VERSION ""

NS_ :

BS_:

BU_: External_Tool IFV SODFR SODFL

BO_ 1064 SODFR_DETECTION_161_164: 64 SODFR
 SG_ CAN_FR_DET_RANGE_161 : 7|14@0+ (0.015625,0) [0|255.984375] "m"  IFV
 SG_ CAN_FR_DET_SD_RANGE_161 : 9|6@0+ (0.025,0) [0|1.5] "m"  IFV
 SG_ CAN_FR_DET_RANGE_RATE_161 : 19|14@0+ (0.015625,-128) [-128|127.984375] "m/s"  IFV
 SG_ CAN_FR_DET_SD_RANGE_RATE_161 : 37|6@0+ (0.02,0) [0|1.2] "m/s"  IFV
 SG_ CAN_FR_DET_AZIMUTH_161 : 47|13@0+ (0.0007668,-3.141593) [-3.141593|3.141593] "rad"  IFV
 SG_ CAN_FR_DET_SD_AZIMUTH_161 : 50|6@0+ (0.001745329,0) [0|0.104719755] "rad"  IFV
 SG_ CAN_FR_DET_ELEVATION_161 : 60|7@0+ (0.157449,-9.99812) [-9.99812|9.997903] "deg"  IFV
 SG_ CAN_FR_DET_SD_ELEVATION_161 : 69|6@0+ (0.003490659,0) [0|0.20943951] "rad"  IFV
 SG_ CAN_FR_DET_AMPLITUDE_161 : 79|7@0+ (1,-64) [-64|63] "dBsm"  IFV
 SG_ CAN_FR_DET_VALID_FLAG_161 : 72|1@0+ (1,0) [0|1] ""  IFV
 SG_ CAN_FR_DET_SUPER_RES_161 : 80|1@0+ (1,0) [0|1] ""  IFV
 SG_ CAN_FR_DET_LOW_SNR_FLAG_161 : 81|1@0+ (1,0) [0|1] ""  IFV
 SG_ CAN_FR_DET_MIXER_BIAS_FLAG_161 : 82|1@0+ (1,0) [0|1] ""  IFV
 SG_ CAN_FR_DET_RESERVED_FLAGS_161 : 87|5@0+ (1,0) [0|31] ""  IFV
 SG_ CAN_FR_DET_SNR_161 : 95|8@0+ (0.35156,0) [0|89.6478] "dB"  IFV
 SG_ CAN_FR_DET_MULTI_TARGET_PROB_161 : 99|4@0+ (0.06667,0) [0|1] ""  IFV
 SG_ CAN_FR_DET_CONFID_AZIMUTH_161 : 101|2@0+ (1,0) [0|3] ""  IFV
 SG_ CAN_FR_DET_CONFID_ELEVATION_161 : 103|2@0+ (1,0) [0|3] ""  IFV
 SG_ CAN_FR_DET_EXISTENCE_PROB_161 : 107|4@0+ (1,0) [0|15] ""  IFV
 SG_ CAN_FR_DET_CLASS_161 : 111|4@0+ (1,0) [0|15] ""  IFV
 SG_ CAN_FR_DET_RANGE_162 : 127|14@0+ (0.015625,0) [0|255.984375] "m"  IFV
 SG_ CAN_FR_DET_SD_RANGE_162 : 129|6@0+ (0.025,0) [0|1.5] "m"  IFV
 SG_ CAN_FR_DET_RANGE_RATE_162 : 139|14@0+ (0.015625,-128) [-128|127.984375] "m/s"  IFV
 SG_ CAN_FR_DET_SD_RANGE_RATE_162 : 157|6@0+ (0.02,0) [0|1.2] "m/s"  IFV
 SG_ CAN_FR_DET_AZIMUTH_162 : 167|13@0+ (0.0007668,-3.141593) [-3.141593|3.141593] "rad"  IFV
 SG_ CAN_FR_DET_SD_AZIMUTH_162 : 170|6@0+ (0.001745329,0) [0|0.104719755] "rad"  IFV
 SG_ CAN_FR_DET_ELEVATION_162 : 180|7@0+ (0.157449,-9.99812) [-9.99812|9.997903] "deg"  IFV
 SG_ CAN_FR_DET_SD_ELEVATION_162 : 189|6@0+ (0.003490659,0) [0|0.20943951] "rad"  IFV
 SG_ CAN_FR_DET_AMPLITUDE_162 : 199|7@0+ (1,-64) [-64|63] "dBsm"  IFV
 SG_ CAN_FR_DET_VALID_FLAG_162 : 192|1@0+ (1,0) [0|1] ""  IFV
 SG_ CAN_FR_DET_SUPER_RES_162 : 200|1@0+ (1,0) [0|1] ""  IFV
 SG_ CAN_FR_DET_LOW_SNR_FLAG_162 : 201|1@0+ (1,0) [0|1] ""  IFV
 SG_ CAN_FR_DET_MIXER_BIAS_FLAG_162 : 202|1@0+ (1,0) [0|1] ""  IFV
 SG_ CAN_FR_DET_RESERVED_FLAGS_162 : 207|5@0+ (1,0) [0|31] ""  IFV
 SG_ CAN_FR_DET_SNR_162 : 215|8@0+ (0.35156,0) [0|89.6478] "dB"  IFV
 SG_ CAN_FR_DET_MULTI_TARGET_PROB_162 : 219|4@0+ (0.06667,0) [0|1] ""  IFV
 SG_ CAN_FR_DET_CONFID_AZIMUTH_162 : 221|2@0+ (1,0) [0|3] ""  IFV
 SG_ CAN_FR_DET_CONFID_ELEVATION_162 : 223|2@0+ (1,0) [0|3] ""  IFV
 SG_ CAN_FR_DET_EXISTENCE_PROB_162 : 227|4@0+ (1,0) [0|15] ""  IFV
 SG_ CAN_FR_DET_CLASS_162 : 231|4@0+ (1,0) [0|15] ""  IFV
 SG_ CAN_FR_DET_RANGE_163 : 247|14@0+ (0.015625,0) [0|255.984375] "m"  IFV
 SG_ CAN_FR_DET_SD_RANGE_163 : 249|6@0+ (0.025,0) [0|1.5] "m"  IFV
 SG_ CAN_FR_DET_RANGE_RATE_163 : 259|14@0+ (0.015625,-128) [-128|127.984375] "m/s"  IFV
 SG_ CAN_FR_DET_SD_RANGE_RATE_163 : 277|6@0+ (0.02,0) [0|1.2] "m/s"  IFV
 SG_ CAN_FR_DET_AZIMUTH_163 : 287|13@0+ (0.0007668,-3.141593) [-3.141593|3.141593] "rad"  IFV
 SG_ CAN_FR_DET_SD_AZIMUTH_163 : 290|6@0+ (0.001745329,0) [0|0.104719755] "rad"  IFV
 SG_ CAN_FR_DET_ELEVATION_163 : 300|7@0+ (0.157449,-9.99812) [-9.99812|9.997903] "deg"  IFV
 SG_ CAN_FR_DET_SD_ELEVATION_163 : 309|6@0+ (0.003490659,0) [0|0.20943951] "rad"  IFV
 SG_ CAN_FR_DET_AMPLITUDE_163 : 319|7@0+ (1,-64) [-64|63] "dBsm"  IFV
 SG_ CAN_FR_DET_VALID_FLAG_163 : 312|1@0+ (1,0) [0|1] ""  IFV
 SG_ CAN_FR_DET_SUPER_RES_163 : 320|1@0+ (1,0) [0|1] ""  IFV
 SG_ CAN_FR_DET_LOW_SNR_FLAG_163 : 321|1@0+ (1,0) [0|1] ""  IFV
 SG_ CAN_FR_DET_MIXER_BIAS_FLAG_163 : 322|1@0+ (1,0) [0|1] ""  IFV
 SG_ CAN_FR_DET_RESERVED_FLAGS_163 : 327|5@0+ (1,0) [0|31] ""  IFV
 SG_ CAN_FR_DET_SNR_163 : 335|8@0+ (0.35156,0) [0|89.6478] "dB"  IFV
 SG_ CAN_FR_DET_MULTI_TARGET_PROB_163 : 339|4@0+ (0.06667,0) [0|1] ""  IFV
 SG_ CAN_FR_DET_CONFID_AZIMUTH_163 : 341|2@0+ (1,0) [0|3] ""  IFV
 SG_ CAN_FR_DET_CONFID_ELEVATION_163 : 343|2@0+ (1,0) [0|3] ""  IFV
 SG_ CAN_FR_DET_EXISTENCE_PROB_163 : 347|4@0+ (1,0) [0|15] ""  IFV
 SG_ CAN_FR_DET_CLASS_163 : 351|4@0+ (1,0) [0|15] ""  IFV
 SG_ CAN_FR_DET_RANGE_164 : 367|14@0+ (0.015625,0) [0|255.984375] "m"  IFV
 SG_ CAN_FR_DET_SD_RANGE_164 : 369|6@0+ (0.025,0) [0|1.5] "m"  IFV
 SG_ CAN_FR_DET_RANGE_RATE_164 : 379|14@0+ (0.015625,-128) [-128|127.984375] "m/s"  IFV
 SG_ CAN_FR_DET_SD_RANGE_RATE_164 : 397|6@0+ (0.02,0) [0|1.2] "m/s"  IFV
 SG_ CAN_FR_DET_AZIMUTH_164 : 407|13@0+ (0.0007668,-3.141593) [-3.141593|3.141593] "rad"  IFV
 SG_ CAN_FR_DET_SD_AZIMUTH_164 : 410|6@0+ (0.001745329,0) [0|0.104719755] "rad"  IFV
 SG_ CAN_FR_DET_ELEVATION_164 : 420|7@0+ (0.157449,-9.99812) [-9.99812|9.997903] "deg"  IFV
 SG_ CAN_FR_DET_SD_ELEVATION_164 : 429|6@0+ (0.003490659,0) [0|0.20943951] "rad"  IFV
 SG_ CAN_FR_DET_AMPLITUDE_164 : 439|7@0+ (1,-64) [-64|63] "dBsm"  IFV
 SG_ CAN_FR_DET_VALID_FLAG_164 : 432|1@0+ (1,0) [0|1] ""  IFV
 SG_ CAN_FR_DET_SUPER_RES_164 : 440|1@0+ (1,0) [0|1] ""  IFV
 SG_ CAN_FR_DET_LOW_SNR_FLAG_164 : 441|1@0+ (1,0) [0|1] ""  IFV
 SG_ CAN_FR_DET_MIXER_BIAS_FLAG_164 : 442|1@0+ (1,0) [0|1] ""  IFV
 SG_ CAN_FR_DET_RESERVED_FLAGS_164 : 447|5@0+ (1,0) [0|31] ""  IFV
 SG_ CAN_FR_DET_SNR_164 : 455|8@0+ (0.35156,0) [0|89.6478] "dB"  IFV
 SG_ CAN_FR_DET_MULTI_TARGET_PROB_164 : 459|4@0+ (0.06667,0) [0|1] ""  IFV
 SG_ CAN_FR_DET_CONFID_AZIMUTH_164 : 461|2@0+ (1,0) [0|3] ""  IFV
 SG_ CAN_FR_DET_CONFID_ELEVATION_164 : 463|2@0+ (1,0) [0|3] ""  IFV
 SG_ CAN_FR_DET_EXISTENCE_PROB_164 : 467|4@0+ (1,0) [0|15] ""  IFV
 SG_ CAN_FR_DET_CLASS_164 : 471|4@0+ (1,0) [0|15] ""  IFV

BO_ 1065 SODFR_DETECTION_165_168: 64 SODFR
 SG_ CAN_FR_DET_RANGE_165 : 7|14@0+ (0.015625,0) [0|255.984375] "m"  IFV
 SG_ CAN_FR_DET_SD_RANGE_165 : 9|6@0+ (0.025,0) [0|1.5] "m"  IFV
 SG_ CAN_FR_DET_RANGE_RATE_165 : 19|14@0+ (0.015625,-128) [-128|127.984375] "m/s"  IFV
 SG_ CAN_FR_DET_SD_RANGE_RATE_165 : 37|6@0+ (0.02,0) [0|1.2] "m/s"  IFV
 SG_ CAN_FR_DET_AZIMUTH_165 : 47|13@0+ (0.0007668,-3.141593) [-3.141593|3.141593] "rad"  IFV
 SG_ CAN_FR_DET_SD_AZIMUTH_165 : 50|6@0+ (0.001745329,0) [0|0.104719755] "rad"  IFV
 SG_ CAN_FR_DET_ELEVATION_165 : 60|7@0+ (0.157449,-9.99812) [-9.99812|9.997903] "deg"  IFV
 SG_ CAN_FR_DET_SD_ELEVATION_165 : 69|6@0+ (0.003490659,0) [0|0.20943951] "rad"  IFV
 SG_ CAN_FR_DET_AMPLITUDE_165 : 79|7@0+ (1,-64) [-64|63] "dBsm"  IFV
 SG_ CAN_FR_DET_VALID_FLAG_165 : 72|1@0+ (1,0) [0|1] ""  IFV
 SG_ CAN_FR_DET_SUPER_RES_165 : 80|1@0+ (1,0) [0|1] ""  IFV
 SG_ CAN_FR_DET_LOW_SNR_FLAG_165 : 81|1@0+ (1,0) [0|1] ""  IFV
 SG_ CAN_FR_DET_MIXER_BIAS_FLAG_165 : 82|1@0+ (1,0) [0|1] ""  IFV
 SG_ CAN_FR_DET_RESERVED_FLAGS_165 : 87|5@0+ (1,0) [0|31] ""  IFV
 SG_ CAN_FR_DET_SNR_165 : 95|8@0+ (0.35156,0) [0|89.6478] "dB"  IFV
 SG_ CAN_FR_DET_MULTI_TARGET_PROB_165 : 99|4@0+ (0.06667,0) [0|1] ""  IFV
 SG_ CAN_FR_DET_CONFID_AZIMUTH_165 : 101|2@0+ (1,0) [0|3] ""  IFV
 SG_ CAN_FR_DET_CONFID_ELEVATION_165 : 103|2@0+ (1,0) [0|3] ""  IFV
 SG_ CAN_FR_DET_EXISTENCE_PROB_165 : 107|4@0+ (1,0) [0|15] ""  IFV
 SG_ CAN_FR_DET_CLASS_165 : 111|4@0+ (1,0) [0|15] ""  IFV
 SG_ CAN_FR_DET_RANGE_166 : 127|14@0+ (0.015625,0) [0|255.984375] "m"  IFV
 SG_ CAN_FR_DET_SD_RANGE_166 : 129|6@0+ (0.025,0) [0|1.5] "m"  IFV
 SG_ CAN_FR_DET_RANGE_RATE_166 : 139|14@0+ (0.015625,-128) [-128|127.984375] "m/s"  IFV
 SG_ CAN_FR_DET_SD_RANGE_RATE_166 : 157|6@0+ (0.02,0) [0|1.2] "m/s"  IFV
 SG_ CAN_FR_DET_AZIMUTH_166 : 167|13@0+ (0.0007668,-3.141593) [-3.141593|3.141593] "rad"  IFV
 SG_ CAN_FR_DET_SD_AZIMUTH_166 : 170|6@0+ (0.001745329,0) [0|0.104719755] "rad"  IFV
 SG_ CAN_FR_DET_ELEVATION_166 : 180|7@0+ (0.157449,-9.99812) [-9.99812|9.997903] "deg"  IFV
 SG_ CAN_FR_DET_SD_ELEVATION_166 : 189|6@0+ (0.003490659,0) [0|0.20943951] "rad"  IFV
 SG_ CAN_FR_DET_AMPLITUDE_166 : 199|7@0+ (1,-64) [-64|63] "dBsm"  IFV
 SG_ CAN_FR_DET_VALID_FLAG_166 : 192|1@0+ (1,0) [0|1] ""  IFV
 SG_ CAN_FR_DET_SUPER_RES_166 : 200|1@0+ (1,0) [0|1] ""  IFV
 SG_ CAN_FR_DET_LOW_SNR_FLAG_166 : 201|1@0+ (1,0) [0|1] ""  IFV
 SG_ CAN_FR_DET_MIXER_BIAS_FLAG_166 : 202|1@0+ (1,0) [0|1] ""  IFV
 SG_ CAN_FR_DET_RESERVED_FLAGS_166 : 207|5@0+ (1,0) [0|31] ""  IFV
 SG_ CAN_FR_DET_SNR_166 : 215|8@0+ (0.35156,0) [0|89.6478] "dB"  IFV
 SG_ CAN_FR_DET_MULTI_TARGET_PROB_166 : 219|4@0+ (0.06667,0) [0|1] ""  IFV
 SG_ CAN_FR_DET_CONFID_AZIMUTH_166 : 221|2@0+ (1,0) [0|3] ""  IFV
 SG_ CAN_FR_DET_CONFID_ELEVATION_166 : 223|2@0+ (1,0) [0|3] ""  IFV
 SG_ CAN_FR_DET_EXISTENCE_PROB_166 : 227|4@0+ (1,0) [0|15] ""  IFV
 SG_ CAN_FR_DET_CLASS_166 : 231|4@0+ (1,0) [0|15] ""  IFV
 SG_ CAN_FR_DET_RANGE_167 : 247|14@0+ (0.015625,0) [0|255.984375] "m"  IFV
 SG_ CAN_FR_DET_SD_RANGE_167 : 249|6@0+ (0.025,0) [0|1.5] "m"  IFV
 SG_ CAN_FR_DET_RANGE_RATE_167 : 259|14@0+ (0.015625,-128) [-128|127.984375] "m/s"  IFV
 SG_ CAN_FR_DET_SD_RANGE_RATE_167 : 277|6@0+ (0.02,0) [0|1.2] "m/s"  IFV
 SG_ CAN_FR_DET_AZIMUTH_167 : 287|13@0+ (0.0007668,-3.141593) [-3.141593|3.141593] "rad"  IFV
 SG_ CAN_FR_DET_SD_AZIMUTH_167 : 290|6@0+ (0.001745329,0) [0|0.104719755] "rad"  IFV
 SG_ CAN_FR_DET_ELEVATION_167 : 300|7@0+ (0.157449,-9.99812) [-9.99812|9.997903] "deg"  IFV
 SG_ CAN_FR_DET_SD_ELEVATION_167 : 309|6@0+ (0.003490659,0) [0|0.20943951] "rad"  IFV
 SG_ CAN_FR_DET_AMPLITUDE_167 : 319|7@0+ (1,-64) [-64|63] "dBsm"  IFV
 SG_ CAN_FR_DET_VALID_FLAG_167 : 312|1@0+ (1,0) [0|1] ""  IFV
 SG_ CAN_FR_DET_SUPER_RES_167 : 320|1@0+ (1,0) [0|1] ""  IFV
 SG_ CAN_FR_DET_LOW_SNR_FLAG_167 : 321|1@0+ (1,0) [0|1] ""  IFV
 SG_ CAN_FR_DET_MIXER_BIAS_FLAG_167 : 322|1@0+ (1,0) [0|1] ""  IFV
 SG_ CAN_FR_DET_RESERVED_FLAGS_167 : 327|5@0+ (1,0) [0|31] ""  IFV
 SG_ CAN_FR_DET_SNR_167 : 335|8@0+ (0.35156,0) [0|89.6478] "dB"  IFV
 SG_ CAN_FR_DET_MULTI_TARGET_PROB_167 : 339|4@0+ (0.06667,0) [0|1] ""  IFV
 SG_ CAN_FR_DET_CONFID_AZIMUTH_167 : 341|2@0+ (1,0) [0|3] ""  IFV
 SG_ CAN_FR_DET_CONFID_ELEVATION_167 : 343|2@0+ (1,0) [0|3] ""  IFV
 SG_ CAN_FR_DET_EXISTENCE_PROB_167 : 347|4@0+ (1,0) [0|15] ""  IFV
 SG_ CAN_FR_DET_CLASS_167 : 351|4@0+ (1,0) [0|15] ""  IFV
 SG_ CAN_FR_DET_RANGE_168 : 367|14@0+ (0.015625,0) [0|255.984375] "m"  IFV
 SG_ CAN_FR_DET_SD_RANGE_168 : 369|6@0+ (0.025,0) [0|1.5] "m"  IFV
 SG_ CAN_FR_DET_RANGE_RATE_168 : 379|14@0+ (0.015625,-128) [-128|127.984375] "m/s"  IFV
 SG_ CAN_FR_DET_SD_RANGE_RATE_168 : 397|6@0+ (0.02,0) [0|1.2] "m/s"  IFV
 SG_ CAN_FR_DET_AZIMUTH_168 : 407|13@0+ (0.0007668,-3.141593) [-3.141593|3.141593] "rad"  IFV
 SG_ CAN_FR_DET_SD_AZIMUTH_168 : 410|6@0+ (0.001745329,0) [0|0.104719755] "rad"  IFV
 SG_ CAN_FR_DET_ELEVATION_168 : 420|7@0+ (0.157449,-9.99812) [-9.99812|9.997903] "deg"  IFV
 SG_ CAN_FR_DET_SD_ELEVATION_168 : 429|6@0+ (0.003490659,0) [0|0.20943951] "rad"  IFV
 SG_ CAN_FR_DET_AMPLITUDE_168 : 439|7@0+ (1,-64) [-64|63] "dBsm"  IFV
 SG_ CAN_FR_DET_VALID_FLAG_168 : 432|1@0+ (1,0) [0|1] ""  IFV
 SG_ CAN_FR_DET_SUPER_RES_168 : 440|1@0+ (1,0) [0|1] ""  IFV
 SG_ CAN_FR_DET_LOW_SNR_FLAG_168 : 441|1@0+ (1,0) [0|1] ""  IFV
 SG_ CAN_FR_DET_MIXER_BIAS_FLAG_168 : 442|1@0+ (1,0) [0|1] ""  IFV
 SG_ CAN_FR_DET_RESERVED_FLAGS_168 : 447|5@0+ (1,0) [0|31] ""  IFV
 SG_ CAN_FR_DET_SNR_168 : 455|8@0+ (0.35156,0) [0|89.6478] "dB"  IFV
 SG_ CAN_FR_DET_MULTI_TARGET_PROB_168 : 459|4@0+ (0.06667,0) [0|1] ""  IFV
 SG_ CAN_FR_DET_CONFID_AZIMUTH_168 : 461|2@0+ (1,0) [0|3] ""  IFV
 SG_ CAN_FR_DET_CONFID_ELEVATION_168 : 463|2@0+ (1,0) [0|3] ""  IFV
 SG_ CAN_FR_DET_EXISTENCE_PROB_168 : 467|4@0+ (1,0) [0|15] ""  IFV
 SG_ CAN_FR_DET_CLASS_168 : 471|4@0+ (1,0) [0|15] ""  IFV

BO_ 1066 SODFR_DETECTION_169_172: 64 SODFR
 SG_ CAN_FR_DET_RANGE_169 : 7|14@0+ (0.015625,0) [0|255.984375] "m"  IFV
 SG_ CAN_FR_DET_SD_RANGE_169 : 9|6@0+ (0.025,0) [0|1.5] "m"  IFV
 SG_ CAN_FR_DET_RANGE_RATE_169 : 19|14@0+ (0.015625,-128) [-128|127.984375] "m/s"  IFV
 SG_ CAN_FR_DET_SD_RANGE_RATE_169 : 37|6@0+ (0.02,0) [0|1.2] "m/s"  IFV
 SG_ CAN_FR_DET_AZIMUTH_169 : 47|13@0+ (0.0007668,-3.141593) [-3.141593|3.141593] "rad"  IFV
 SG_ CAN_FR_DET_SD_AZIMUTH_169 : 50|6@0+ (0.001745329,0) [0|0.104719755] "rad"  IFV
 SG_ CAN_FR_DET_ELEVATION_169 : 60|7@0+ (0.157449,-9.99812) [-9.99812|9.997903] "deg"  IFV
 SG_ CAN_FR_DET_SD_ELEVATION_169 : 69|6@0+ (0.003490659,0) [0|0.20943951] "rad"  IFV
 SG_ CAN_FR_DET_AMPLITUDE_169 : 79|7@0+ (1,-64) [-64|63] "dBsm"  IFV
 SG_ CAN_FR_DET_VALID_FLAG_169 : 72|1@0+ (1,0) [0|1] ""  IFV
 SG_ CAN_FR_DET_SUPER_RES_169 : 80|1@0+ (1,0) [0|1] ""  IFV
 SG_ CAN_FR_DET_LOW_SNR_FLAG_169 : 81|1@0+ (1,0) [0|1] ""  IFV
 SG_ CAN_FR_DET_MIXER_BIAS_FLAG_169 : 82|1@0+ (1,0) [0|1] ""  IFV
 SG_ CAN_FR_DET_RESERVED_FLAGS_169 : 87|5@0+ (1,0) [0|31] ""  IFV
 SG_ CAN_FR_DET_SNR_169 : 95|8@0+ (0.35156,0) [0|89.6478] "dB"  IFV
 SG_ CAN_FR_DET_MULTI_TARGET_PROB_169 : 99|4@0+ (0.06667,0) [0|1] ""  IFV
 SG_ CAN_FR_DET_CONFID_AZIMUTH_169 : 101|2@0+ (1,0) [0|3] ""  IFV
 SG_ CAN_FR_DET_CONFID_ELEVATION_169 : 103|2@0+ (1,0) [0|3] ""  IFV
 SG_ CAN_FR_DET_EXISTENCE_PROB_169 : 107|4@0+ (1,0) [0|15] ""  IFV
 SG_ CAN_FR_DET_CLASS_169 : 111|4@0+ (1,0) [0|15] ""  IFV
 SG_ CAN_FR_DET_RANGE_170 : 127|14@0+ (0.015625,0) [0|255.984375] "m"  IFV
 SG_ CAN_FR_DET_SD_RANGE_170 : 129|6@0+ (0.025,0) [0|1.5] "m"  IFV
 SG_ CAN_FR_DET_RANGE_RATE_170 : 139|14@0+ (0.015625,-128) [-128|127.984375] "m/s"  IFV
 SG_ CAN_FR_DET_SD_RANGE_RATE_170 : 157|6@0+ (0.02,0) [0|1.2] "m/s"  IFV
 SG_ CAN_FR_DET_AZIMUTH_170 : 167|13@0+ (0.0007668,-3.141593) [-3.141593|3.141593] "rad"  IFV
 SG_ CAN_FR_DET_SD_AZIMUTH_170 : 170|6@0+ (0.001745329,0) [0|0.104719755] "rad"  IFV
 SG_ CAN_FR_DET_ELEVATION_170 : 180|7@0+ (0.157449,-9.99812) [-9.99812|9.997903] "deg"  IFV
 SG_ CAN_FR_DET_SD_ELEVATION_170 : 189|6@0+ (0.003490659,0) [0|0.20943951] "rad"  IFV
 SG_ CAN_FR_DET_AMPLITUDE_170 : 199|7@0+ (1,-64) [-64|63] "dBsm"  IFV
 SG_ CAN_FR_DET_VALID_FLAG_170 : 192|1@0+ (1,0) [0|1] ""  IFV
 SG_ CAN_FR_DET_SUPER_RES_170 : 200|1@0+ (1,0) [0|1] ""  IFV
 SG_ CAN_FR_DET_LOW_SNR_FLAG_170 : 201|1@0+ (1,0) [0|1] ""  IFV
 SG_ CAN_FR_DET_MIXER_BIAS_FLAG_170 : 202|1@0+ (1,0) [0|1] ""  IFV
 SG_ CAN_FR_DET_RESERVED_FLAGS_170 : 207|5@0+ (1,0) [0|31] ""  IFV
 SG_ CAN_FR_DET_SNR_170 : 215|8@0+ (0.35156,0) [0|89.6478] "dB"  IFV
 SG_ CAN_FR_DET_MULTI_TARGET_PROB_170 : 219|4@0+ (0.06667,0) [0|1] ""  IFV
 SG_ CAN_FR_DET_CONFID_AZIMUTH_170 : 221|2@0+ (1,0) [0|3] ""  IFV
 SG_ CAN_FR_DET_CONFID_ELEVATION_170 : 223|2@0+ (1,0) [0|3] ""  IFV
 SG_ CAN_FR_DET_EXISTENCE_PROB_170 : 227|4@0+ (1,0) [0|15] ""  IFV
 SG_ CAN_FR_DET_CLASS_170 : 231|4@0+ (1,0) [0|15] ""  IFV
 SG_ CAN_FR_DET_RANGE_171 : 247|14@0+ (0.015625,0) [0|255.984375] "m"  IFV
 SG_ CAN_FR_DET_SD_RANGE_171 : 249|6@0+ (0.025,0) [0|1.5] "m"  IFV
 SG_ CAN_FR_DET_RANGE_RATE_171 : 259|14@0+ (0.015625,-128) [-128|127.984375] "m/s"  IFV
 SG_ CAN_FR_DET_SD_RANGE_RATE_171 : 277|6@0+ (0.02,0) [0|1.2] "m/s"  IFV
 SG_ CAN_FR_DET_AZIMUTH_171 : 287|13@0+ (0.0007668,-3.141593) [-3.141593|3.141593] "rad"  IFV
 SG_ CAN_FR_DET_SD_AZIMUTH_171 : 290|6@0+ (0.001745329,0) [0|0.104719755] "rad"  IFV
 SG_ CAN_FR_DET_ELEVATION_171 : 300|7@0+ (0.157449,-9.99812) [-9.99812|9.997903] "deg"  IFV
 SG_ CAN_FR_DET_SD_ELEVATION_171 : 309|6@0+ (0.003490659,0) [0|0.20943951] "rad"  IFV
 SG_ CAN_FR_DET_AMPLITUDE_171 : 319|7@0+ (1,-64) [-64|63] "dBsm"  IFV
 SG_ CAN_FR_DET_VALID_FLAG_171 : 312|1@0+ (1,0) [0|1] ""  IFV
 SG_ CAN_FR_DET_SUPER_RES_171 : 320|1@0+ (1,0) [0|1] ""  IFV
 SG_ CAN_FR_DET_LOW_SNR_FLAG_171 : 321|1@0+ (1,0) [0|1] ""  IFV
 SG_ CAN_FR_DET_MIXER_BIAS_FLAG_171 : 322|1@0+ (1,0) [0|1] ""  IFV
 SG_ CAN_FR_DET_RESERVED_FLAGS_171 : 327|5@0+ (1,0) [0|31] ""  IFV
 SG_ CAN_FR_DET_SNR_171 : 335|8@0+ (0.35156,0) [0|89.6478] "dB"  IFV
 SG_ CAN_FR_DET_MULTI_TARGET_PROB_171 : 339|4@0+ (0.06667,0) [0|1] ""  IFV
 SG_ CAN_FR_DET_CONFID_AZIMUTH_171 : 341|2@0+ (1,0) [0|3] ""  IFV
 SG_ CAN_FR_DET_CONFID_ELEVATION_171 : 343|2@0+ (1,0) [0|3] ""  IFV
 SG_ CAN_FR_DET_EXISTENCE_PROB_171 : 347|4@0+ (1,0) [0|15] ""  IFV
 SG_ CAN_FR_DET_CLASS_171 : 351|4@0+ (1,0) [0|15] ""  IFV
 SG_ CAN_FR_DET_RANGE_172 : 367|14@0+ (0.015625,0) [0|255.984375] "m"  IFV
 SG_ CAN_FR_DET_SD_RANGE_172 : 369|6@0+ (0.025,0) [0|1.5] "m"  IFV
 SG_ CAN_FR_DET_RANGE_RATE_172 : 379|14@0+ (0.015625,-128) [-128|127.984375] "m/s"  IFV
 SG_ CAN_FR_DET_SD_RANGE_RATE_172 : 397|6@0+ (0.02,0) [0|1.2] "m/s"  IFV
 SG_ CAN_FR_DET_AZIMUTH_172 : 407|13@0+ (0.0007668,-3.141593) [-3.141593|3.141593] "rad"  IFV
 SG_ CAN_FR_DET_SD_AZIMUTH_172 : 410|6@0+ (0.001745329,0) [0|0.104719755] "rad"  IFV
 SG_ CAN_FR_DET_ELEVATION_172 : 420|7@0+ (0.157449,-9.99812) [-9.99812|9.997903] "deg"  IFV
 SG_ CAN_FR_DET_SD_ELEVATION_172 : 429|6@0+ (0.003490659,0) [0|0.20943951] "rad"  IFV
 SG_ CAN_FR_DET_AMPLITUDE_172 : 439|7@0+ (1,-64) [-64|63] "dBsm"  IFV
 SG_ CAN_FR_DET_VALID_FLAG_172 : 432|1@0+ (1,0) [0|1] ""  IFV
 SG_ CAN_FR_DET_SUPER_RES_172 : 440|1@0+ (1,0) [0|1] ""  IFV
 SG_ CAN_FR_DET_LOW_SNR_FLAG_172 : 441|1@0+ (1,0) [0|1] ""  IFV
 SG_ CAN_FR_DET_MIXER_BIAS_FLAG_172 : 442|1@0+ (1,0) [0|1] ""  IFV
 SG_ CAN_FR_DET_RESERVED_FLAGS_172 : 447|5@0+ (1,0) [0|31] ""  IFV
 SG_ CAN_FR_DET_SNR_172 : 455|8@0+ (0.35156,0) [0|89.6478] "dB"  IFV
 SG_ CAN_FR_DET_MULTI_TARGET_PROB_172 : 459|4@0+ (0.06667,0) [0|1] ""  IFV
 SG_ CAN_FR_DET_CONFID_AZIMUTH_172 : 461|2@0+ (1,0) [0|3] ""  IFV
 SG_ CAN_FR_DET_CONFID_ELEVATION_172 : 463|2@0+ (1,0) [0|3] ""  IFV
 SG_ CAN_FR_DET_EXISTENCE_PROB_172 : 467|4@0+ (1,0) [0|15] ""  IFV
 SG_ CAN_FR_DET_CLASS_172 : 471|4@0+ (1,0) [0|15] ""  IFV

BO_ 1067 SODFR_DETECTION_173_176: 64 SODFR
 SG_ CAN_FR_DET_RANGE_173 : 7|14@0+ (0.015625,0) [0|255.984375] "m"  IFV
 SG_ CAN_FR_DET_SD_RANGE_173 : 9|6@0+ (0.025,0) [0|1.5] "m"  IFV
 SG_ CAN_FR_DET_RANGE_RATE_173 : 19|14@0+ (0.015625,-128) [-128|127.984375] "m/s"  IFV
 SG_ CAN_FR_DET_SD_RANGE_RATE_173 : 37|6@0+ (0.02,0) [0|1.2] "m/s"  IFV
 SG_ CAN_FR_DET_AZIMUTH_173 : 47|13@0+ (0.0007668,-3.141593) [-3.141593|3.141593] "rad"  IFV
 SG_ CAN_FR_DET_SD_AZIMUTH_173 : 50|6@0+ (0.001745329,0) [0|0.104719755] "rad"  IFV
 SG_ CAN_FR_DET_ELEVATION_173 : 60|7@0+ (0.157449,-9.99812) [-9.99812|9.997903] "deg"  IFV
 SG_ CAN_FR_DET_SD_ELEVATION_173 : 69|6@0+ (0.003490659,0) [0|0.20943951] "rad"  IFV
 SG_ CAN_FR_DET_AMPLITUDE_173 : 79|7@0+ (1,-64) [-64|63] "dBsm"  IFV
 SG_ CAN_FR_DET_VALID_FLAG_173 : 72|1@0+ (1,0) [0|1] ""  IFV
 SG_ CAN_FR_DET_SUPER_RES_173 : 80|1@0+ (1,0) [0|1] ""  IFV
 SG_ CAN_FR_DET_LOW_SNR_FLAG_173 : 81|1@0+ (1,0) [0|1] ""  IFV
 SG_ CAN_FR_DET_MIXER_BIAS_FLAG_173 : 82|1@0+ (1,0) [0|1] ""  IFV
 SG_ CAN_FR_DET_RESERVED_FLAGS_173 : 87|5@0+ (1,0) [0|31] ""  IFV
 SG_ CAN_FR_DET_SNR_173 : 95|8@0+ (0.35156,0) [0|89.6478] "dB"  IFV
 SG_ CAN_FR_DET_MULTI_TARGET_PROB_173 : 99|4@0+ (0.06667,0) [0|1] ""  IFV
 SG_ CAN_FR_DET_CONFID_AZIMUTH_173 : 101|2@0+ (1,0) [0|3] ""  IFV
 SG_ CAN_FR_DET_CONFID_ELEVATION_173 : 103|2@0+ (1,0) [0|3] ""  IFV
 SG_ CAN_FR_DET_EXISTENCE_PROB_173 : 107|4@0+ (1,0) [0|15] ""  IFV
 SG_ CAN_FR_DET_CLASS_173 : 111|4@0+ (1,0) [0|15] ""  IFV
 SG_ CAN_FR_DET_RANGE_174 : 127|14@0+ (0.015625,0) [0|255.984375] "m"  IFV
 SG_ CAN_FR_DET_SD_RANGE_174 : 129|6@0+ (0.025,0) [0|1.5] "m"  IFV
 SG_ CAN_FR_DET_RANGE_RATE_174 : 139|14@0+ (0.015625,-128) [-128|127.984375] "m/s"  IFV
 SG_ CAN_FR_DET_SD_RANGE_RATE_174 : 157|6@0+ (0.02,0) [0|1.2] "m/s"  IFV
 SG_ CAN_FR_DET_AZIMUTH_174 : 167|13@0+ (0.0007668,-3.141593) [-3.141593|3.141593] "rad"  IFV
 SG_ CAN_FR_DET_SD_AZIMUTH_174 : 170|6@0+ (0.001745329,0) [0|0.104719755] "rad"  IFV
 SG_ CAN_FR_DET_ELEVATION_174 : 180|7@0+ (0.157449,-9.99812) [-9.99812|9.997903] "deg"  IFV
 SG_ CAN_FR_DET_SD_ELEVATION_174 : 189|6@0+ (0.003490659,0) [0|0.20943951] "rad"  IFV
 SG_ CAN_FR_DET_AMPLITUDE_174 : 199|7@0+ (1,-64) [-64|63] "dBsm"  IFV
 SG_ CAN_FR_DET_VALID_FLAG_174 : 192|1@0+ (1,0) [0|1] ""  IFV
 SG_ CAN_FR_DET_SUPER_RES_174 : 200|1@0+ (1,0) [0|1] ""  IFV
 SG_ CAN_FR_DET_LOW_SNR_FLAG_174 : 201|1@0+ (1,0) [0|1] ""  IFV
 SG_ CAN_FR_DET_MIXER_BIAS_FLAG_174 : 202|1@0+ (1,0) [0|1] ""  IFV
 SG_ CAN_FR_DET_RESERVED_FLAGS_174 : 207|5@0+ (1,0) [0|31] ""  IFV
 SG_ CAN_FR_DET_SNR_174 : 215|8@0+ (0.35156,0) [0|89.6478] "dB"  IFV
 SG_ CAN_FR_DET_MULTI_TARGET_PROB_174 : 219|4@0+ (0.06667,0) [0|1] ""  IFV
 SG_ CAN_FR_DET_CONFID_AZIMUTH_174 : 221|2@0+ (1,0) [0|3] ""  IFV
 SG_ CAN_FR_DET_CONFID_ELEVATION_174 : 223|2@0+ (1,0) [0|3] ""  IFV
 SG_ CAN_FR_DET_EXISTENCE_PROB_174 : 227|4@0+ (1,0) [0|15] ""  IFV
 SG_ CAN_FR_DET_CLASS_174 : 231|4@0+ (1,0) [0|15] ""  IFV
 SG_ CAN_FR_DET_RANGE_175 : 247|14@0+ (0.015625,0) [0|255.984375] "m"  IFV
 SG_ CAN_FR_DET_SD_RANGE_175 : 249|6@0+ (0.025,0) [0|1.5] "m"  IFV
 SG_ CAN_FR_DET_RANGE_RATE_175 : 259|14@0+ (0.015625,-128) [-128|127.984375] "m/s"  IFV
 SG_ CAN_FR_DET_SD_RANGE_RATE_175 : 277|6@0+ (0.02,0) [0|1.2] "m/s"  IFV
 SG_ CAN_FR_DET_AZIMUTH_175 : 287|13@0+ (0.0007668,-3.141593) [-3.141593|3.141593] "rad"  IFV
 SG_ CAN_FR_DET_SD_AZIMUTH_175 : 290|6@0+ (0.001745329,0) [0|0.104719755] "rad"  IFV
 SG_ CAN_FR_DET_ELEVATION_175 : 300|7@0+ (0.157449,-9.99812) [-9.99812|9.997903] "deg"  IFV
 SG_ CAN_FR_DET_SD_ELEVATION_175 : 309|6@0+ (0.003490659,0) [0|0.20943951] "rad"  IFV
 SG_ CAN_FR_DET_AMPLITUDE_175 : 319|7@0+ (1,-64) [-64|63] "dBsm"  IFV
 SG_ CAN_FR_DET_VALID_FLAG_175 : 312|1@0+ (1,0) [0|1] ""  IFV
 SG_ CAN_FR_DET_SUPER_RES_175 : 320|1@0+ (1,0) [0|1] ""  IFV
 SG_ CAN_FR_DET_LOW_SNR_FLAG_175 : 321|1@0+ (1,0) [0|1] ""  IFV
 SG_ CAN_FR_DET_MIXER_BIAS_FLAG_175 : 322|1@0+ (1,0) [0|1] ""  IFV
 SG_ CAN_FR_DET_RESERVED_FLAGS_175 : 327|5@0+ (1,0) [0|31] ""  IFV
 SG_ CAN_FR_DET_SNR_175 : 335|8@0+ (0.35156,0) [0|89.6478] "dB"  IFV
 SG_ CAN_FR_DET_MULTI_TARGET_PROB_175 : 339|4@0+ (0.06667,0) [0|1] ""  IFV
 SG_ CAN_FR_DET_CONFID_AZIMUTH_175 : 341|2@0+ (1,0) [0|3] ""  IFV
 SG_ CAN_FR_DET_CONFID_ELEVATION_175 : 343|2@0+ (1,0) [0|3] ""  IFV
 SG_ CAN_FR_DET_EXISTENCE_PROB_175 : 347|4@0+ (1,0) [0|15] ""  IFV
 SG_ CAN_FR_DET_CLASS_175 : 351|4@0+ (1,0) [0|15] ""  IFV
 SG_ CAN_FR_DET_RANGE_176 : 367|14@0+ (0.015625,0) [0|255.984375] "m"  IFV
 SG_ CAN_FR_DET_SD_RANGE_176 : 369|6@0+ (0.025,0) [0|1.5] "m"  IFV
 SG_ CAN_FR_DET_RANGE_RATE_176 : 379|14@0+ (0.015625,-128) [-128|127.984375] "m/s"  IFV
 SG_ CAN_FR_DET_SD_RANGE_RATE_176 : 397|6@0+ (0.02,0) [0|1.2] "m/s"  IFV
 SG_ CAN_FR_DET_AZIMUTH_176 : 407|13@0+ (0.0007668,-3.141593) [-3.141593|3.141593] "rad"  IFV
 SG_ CAN_FR_DET_SD_AZIMUTH_176 : 410|6@0+ (0.001745329,0) [0|0.104719755] "rad"  IFV
 SG_ CAN_FR_DET_ELEVATION_176 : 420|7@0+ (0.157449,-9.99812) [-9.99812|9.997903] "deg"  IFV
 SG_ CAN_FR_DET_SD_ELEVATION_176 : 429|6@0+ (0.003490659,0) [0|0.20943951] "rad"  IFV
 SG_ CAN_FR_DET_AMPLITUDE_176 : 439|7@0+ (1,-64) [-64|63] "dBsm"  IFV
 SG_ CAN_FR_DET_VALID_FLAG_176 : 432|1@0+ (1,0) [0|1] ""  IFV
 SG_ CAN_FR_DET_SUPER_RES_176 : 440|1@0+ (1,0) [0|1] ""  IFV
 SG_ CAN_FR_DET_LOW_SNR_FLAG_176 : 441|1@0+ (1,0) [0|1] ""  IFV
 SG_ CAN_FR_DET_MIXER_BIAS_FLAG_176 : 442|1@0+ (1,0) [0|1] ""  IFV
 SG_ CAN_FR_DET_RESERVED_FLAGS_176 : 447|5@0+ (1,0) [0|31] ""  IFV
 SG_ CAN_FR_DET_SNR_176 : 455|8@0+ (0.35156,0) [0|89.6478] "dB"  IFV
 SG_ CAN_FR_DET_MULTI_TARGET_PROB_176 : 459|4@0+ (0.06667,0) [0|1] ""  IFV
 SG_ CAN_FR_DET_CONFID_AZIMUTH_176 : 461|2@0+ (1,0) [0|3] ""  IFV
 SG_ CAN_FR_DET_CONFID_ELEVATION_176 : 463|2@0+ (1,0) [0|3] ""  IFV
 SG_ CAN_FR_DET_EXISTENCE_PROB_176 : 467|4@0+ (1,0) [0|15] ""  IFV
 SG_ CAN_FR_DET_CLASS_176 : 471|4@0+ (1,0) [0|15] ""  IFV

BO_ 1068 SODFR_DETECTION_177_180: 64 SODFR
 SG_ CAN_FR_DET_RANGE_177 : 7|14@0+ (0.015625,0) [0|255.984375] "m"  IFV
 SG_ CAN_FR_DET_SD_RANGE_177 : 9|6@0+ (0.025,0) [0|1.5] "m"  IFV
 SG_ CAN_FR_DET_RANGE_RATE_177 : 19|14@0+ (0.015625,-128) [-128|127.984375] "m/s"  IFV
 SG_ CAN_FR_DET_SD_RANGE_RATE_177 : 37|6@0+ (0.02,0) [0|1.2] "m/s"  IFV
 SG_ CAN_FR_DET_AZIMUTH_177 : 47|13@0+ (0.0007668,-3.141593) [-3.141593|3.141593] "rad"  IFV
 SG_ CAN_FR_DET_SD_AZIMUTH_177 : 50|6@0+ (0.001745329,0) [0|0.104719755] "rad"  IFV
 SG_ CAN_FR_DET_ELEVATION_177 : 60|7@0+ (0.157449,-9.99812) [-9.99812|9.997903] "deg"  IFV
 SG_ CAN_FR_DET_SD_ELEVATION_177 : 69|6@0+ (0.003490659,0) [0|0.20943951] "rad"  IFV
 SG_ CAN_FR_DET_AMPLITUDE_177 : 79|7@0+ (1,-64) [-64|63] "dBsm"  IFV
 SG_ CAN_FR_DET_VALID_FLAG_177 : 72|1@0+ (1,0) [0|1] ""  IFV
 SG_ CAN_FR_DET_SUPER_RES_177 : 80|1@0+ (1,0) [0|1] ""  IFV
 SG_ CAN_FR_DET_LOW_SNR_FLAG_177 : 81|1@0+ (1,0) [0|1] ""  IFV
 SG_ CAN_FR_DET_MIXER_BIAS_FLAG_177 : 82|1@0+ (1,0) [0|1] ""  IFV
 SG_ CAN_FR_DET_RESERVED_FLAGS_177 : 87|5@0+ (1,0) [0|31] ""  IFV
 SG_ CAN_FR_DET_SNR_177 : 95|8@0+ (0.35156,0) [0|89.6478] "dB"  IFV
 SG_ CAN_FR_DET_MULTI_TARGET_PROB_177 : 99|4@0+ (0.06667,0) [0|1] ""  IFV
 SG_ CAN_FR_DET_CONFID_AZIMUTH_177 : 101|2@0+ (1,0) [0|3] ""  IFV
 SG_ CAN_FR_DET_CONFID_ELEVATION_177 : 103|2@0+ (1,0) [0|3] ""  IFV
 SG_ CAN_FR_DET_EXISTENCE_PROB_177 : 107|4@0+ (1,0) [0|15] ""  IFV
 SG_ CAN_FR_DET_CLASS_177 : 111|4@0+ (1,0) [0|15] ""  IFV
 SG_ CAN_FR_DET_RANGE_178 : 127|14@0+ (0.015625,0) [0|255.984375] "m"  IFV
 SG_ CAN_FR_DET_SD_RANGE_178 : 129|6@0+ (0.025,0) [0|1.5] "m"  IFV
 SG_ CAN_FR_DET_RANGE_RATE_178 : 139|14@0+ (0.015625,-128) [-128|127.984375] "m/s"  IFV
 SG_ CAN_FR_DET_SD_RANGE_RATE_178 : 157|6@0+ (0.02,0) [0|1.2] "m/s"  IFV
 SG_ CAN_FR_DET_AZIMUTH_178 : 167|13@0+ (0.0007668,-3.141593) [-3.141593|3.141593] "rad"  IFV
 SG_ CAN_FR_DET_SD_AZIMUTH_178 : 170|6@0+ (0.001745329,0) [0|0.104719755] "rad"  IFV
 SG_ CAN_FR_DET_ELEVATION_178 : 180|7@0+ (0.157449,-9.99812) [-9.99812|9.997903] "deg"  IFV
 SG_ CAN_FR_DET_SD_ELEVATION_178 : 189|6@0+ (0.003490659,0) [0|0.20943951] "rad"  IFV
 SG_ CAN_FR_DET_AMPLITUDE_178 : 199|7@0+ (1,-64) [-64|63] "dBsm"  IFV
 SG_ CAN_FR_DET_VALID_FLAG_178 : 192|1@0+ (1,0) [0|1] ""  IFV
 SG_ CAN_FR_DET_SUPER_RES_178 : 200|1@0+ (1,0) [0|1] ""  IFV
 SG_ CAN_FR_DET_LOW_SNR_FLAG_178 : 201|1@0+ (1,0) [0|1] ""  IFV
 SG_ CAN_FR_DET_MIXER_BIAS_FLAG_178 : 202|1@0+ (1,0) [0|1] ""  IFV
 SG_ CAN_FR_DET_RESERVED_FLAGS_178 : 207|5@0+ (1,0) [0|31] ""  IFV
 SG_ CAN_FR_DET_SNR_178 : 215|8@0+ (0.35156,0) [0|89.6478] "dB"  IFV
 SG_ CAN_FR_DET_MULTI_TARGET_PROB_178 : 219|4@0+ (0.06667,0) [0|1] ""  IFV
 SG_ CAN_FR_DET_CONFID_AZIMUTH_178 : 221|2@0+ (1,0) [0|3] ""  IFV
 SG_ CAN_FR_DET_CONFID_ELEVATION_178 : 223|2@0+ (1,0) [0|3] ""  IFV
 SG_ CAN_FR_DET_EXISTENCE_PROB_178 : 227|4@0+ (1,0) [0|15] ""  IFV
 SG_ CAN_FR_DET_CLASS_178 : 231|4@0+ (1,0) [0|15] ""  IFV
 SG_ CAN_FR_DET_RANGE_179 : 247|14@0+ (0.015625,0) [0|255.984375] "m"  IFV
 SG_ CAN_FR_DET_SD_RANGE_179 : 249|6@0+ (0.025,0) [0|1.5] "m"  IFV
 SG_ CAN_FR_DET_RANGE_RATE_179 : 259|14@0+ (0.015625,-128) [-128|127.984375] "m/s"  IFV
 SG_ CAN_FR_DET_SD_RANGE_RATE_179 : 277|6@0+ (0.02,0) [0|1.2] "m/s"  IFV
 SG_ CAN_FR_DET_AZIMUTH_179 : 287|13@0+ (0.0007668,-3.141593) [-3.141593|3.141593] "rad"  IFV
 SG_ CAN_FR_DET_SD_AZIMUTH_179 : 290|6@0+ (0.001745329,0) [0|0.104719755] "rad"  IFV
 SG_ CAN_FR_DET_ELEVATION_179 : 300|7@0+ (0.157449,-9.99812) [-9.99812|9.997903] "deg"  IFV
 SG_ CAN_FR_DET_SD_ELEVATION_179 : 309|6@0+ (0.003490659,0) [0|0.20943951] "rad"  IFV
 SG_ CAN_FR_DET_AMPLITUDE_179 : 319|7@0+ (1,-64) [-64|63] "dBsm"  IFV
 SG_ CAN_FR_DET_VALID_FLAG_179 : 312|1@0+ (1,0) [0|1] ""  IFV
 SG_ CAN_FR_DET_SUPER_RES_179 : 320|1@0+ (1,0) [0|1] ""  IFV
 SG_ CAN_FR_DET_LOW_SNR_FLAG_179 : 321|1@0+ (1,0) [0|1] ""  IFV
 SG_ CAN_FR_DET_MIXER_BIAS_FLAG_179 : 322|1@0+ (1,0) [0|1] ""  IFV
 SG_ CAN_FR_DET_RESERVED_FLAGS_179 : 327|5@0+ (1,0) [0|31] ""  IFV
 SG_ CAN_FR_DET_SNR_179 : 335|8@0+ (0.35156,0) [0|89.6478] "dB"  IFV
 SG_ CAN_FR_DET_MULTI_TARGET_PROB_179 : 339|4@0+ (0.06667,0) [0|1] ""  IFV
 SG_ CAN_FR_DET_CONFID_AZIMUTH_179 : 341|2@0+ (1,0) [0|3] ""  IFV
 SG_ CAN_FR_DET_CONFID_ELEVATION_179 : 343|2@0+ (1,0) [0|3] ""  IFV
 SG_ CAN_FR_DET_EXISTENCE_PROB_179 : 347|4@0+ (1,0) [0|15] ""  IFV
 SG_ CAN_FR_DET_CLASS_179 : 351|4@0+ (1,0) [0|15] ""  IFV
 SG_ CAN_FR_DET_RANGE_180 : 367|14@0+ (0.015625,0) [0|255.984375] "m"  IFV
 SG_ CAN_FR_DET_SD_RANGE_180 : 369|6@0+ (0.025,0) [0|1.5] "m"  IFV
 SG_ CAN_FR_DET_RANGE_RATE_180 : 379|14@0+ (0.015625,-128) [-128|127.984375] "m/s"  IFV
 SG_ CAN_FR_DET_SD_RANGE_RATE_180 : 397|6@0+ (0.02,0) [0|1.2] "m/s"  IFV
 SG_ CAN_FR_DET_AZIMUTH_180 : 407|13@0+ (0.0007668,-3.141593) [-3.141593|3.141593] "rad"  IFV
 SG_ CAN_FR_DET_SD_AZIMUTH_180 : 410|6@0+ (0.001745329,0) [0|0.104719755] "rad"  IFV
 SG_ CAN_FR_DET_ELEVATION_180 : 420|7@0+ (0.157449,-9.99812) [-9.99812|9.997903] "deg"  IFV
 SG_ CAN_FR_DET_SD_ELEVATION_180 : 429|6@0+ (0.003490659,0) [0|0.20943951] "rad"  IFV
 SG_ CAN_FR_DET_AMPLITUDE_180 : 439|7@0+ (1,-64) [-64|63] "dBsm"  IFV
 SG_ CAN_FR_DET_VALID_FLAG_180 : 432|1@0+ (1,0) [0|1] ""  IFV
 SG_ CAN_FR_DET_SUPER_RES_180 : 440|1@0+ (1,0) [0|1] ""  IFV
 SG_ CAN_FR_DET_LOW_SNR_FLAG_180 : 441|1@0+ (1,0) [0|1] ""  IFV
 SG_ CAN_FR_DET_MIXER_BIAS_FLAG_180 : 442|1@0+ (1,0) [0|1] ""  IFV
 SG_ CAN_FR_DET_RESERVED_FLAGS_180 : 447|5@0+ (1,0) [0|31] ""  IFV
 SG_ CAN_FR_DET_SNR_180 : 455|8@0+ (0.35156,0) [0|89.6478] "dB"  IFV
 SG_ CAN_FR_DET_MULTI_TARGET_PROB_180 : 459|4@0+ (0.06667,0) [0|1] ""  IFV
 SG_ CAN_FR_DET_CONFID_AZIMUTH_180 : 461|2@0+ (1,0) [0|3] ""  IFV
 SG_ CAN_FR_DET_CONFID_ELEVATION_180 : 463|2@0+ (1,0) [0|3] ""  IFV
 SG_ CAN_FR_DET_EXISTENCE_PROB_180 : 467|4@0+ (1,0) [0|15] ""  IFV
 SG_ CAN_FR_DET_CLASS_180 : 471|4@0+ (1,0) [0|15] ""  IFV

BO_ 1069 SODFR_DETECTION_181_184: 64 SODFR
 SG_ CAN_FR_DET_RANGE_181 : 7|14@0+ (0.015625,0) [0|255.984375] "m"  IFV
 SG_ CAN_FR_DET_SD_RANGE_181 : 9|6@0+ (0.025,0) [0|1.5] "m"  IFV
 SG_ CAN_FR_DET_RANGE_RATE_181 : 19|14@0+ (0.015625,-128) [-128|127.984375] "m/s"  IFV
 SG_ CAN_FR_DET_SD_RANGE_RATE_181 : 37|6@0+ (0.02,0) [0|1.2] "m/s"  IFV
 SG_ CAN_FR_DET_AZIMUTH_181 : 47|13@0+ (0.0007668,-3.141593) [-3.141593|3.141593] "rad"  IFV
 SG_ CAN_FR_DET_SD_AZIMUTH_181 : 50|6@0+ (0.001745329,0) [0|0.104719755] "rad"  IFV
 SG_ CAN_FR_DET_ELEVATION_181 : 60|7@0+ (0.157449,-9.99812) [-9.99812|9.997903] "deg"  IFV
 SG_ CAN_FR_DET_SD_ELEVATION_181 : 69|6@0+ (0.003490659,0) [0|0.20943951] "rad"  IFV
 SG_ CAN_FR_DET_AMPLITUDE_181 : 79|7@0+ (1,-64) [-64|63] "dBsm"  IFV
 SG_ CAN_FR_DET_VALID_FLAG_181 : 72|1@0+ (1,0) [0|1] ""  IFV
 SG_ CAN_FR_DET_SUPER_RES_181 : 80|1@0+ (1,0) [0|1] ""  IFV
 SG_ CAN_FR_DET_LOW_SNR_FLAG_181 : 81|1@0+ (1,0) [0|1] ""  IFV
 SG_ CAN_FR_DET_MIXER_BIAS_FLAG_181 : 82|1@0+ (1,0) [0|1] ""  IFV
 SG_ CAN_FR_DET_RESERVED_FLAGS_181 : 87|5@0+ (1,0) [0|31] ""  IFV
 SG_ CAN_FR_DET_SNR_181 : 95|8@0+ (0.35156,0) [0|89.6478] "dB"  IFV
 SG_ CAN_FR_DET_MULTI_TARGET_PROB_181 : 99|4@0+ (0.06667,0) [0|1] ""  IFV
 SG_ CAN_FR_DET_CONFID_AZIMUTH_181 : 101|2@0+ (1,0) [0|3] ""  IFV
 SG_ CAN_FR_DET_CONFID_ELEVATION_181 : 103|2@0+ (1,0) [0|3] ""  IFV
 SG_ CAN_FR_DET_EXISTENCE_PROB_181 : 107|4@0+ (1,0) [0|15] ""  IFV
 SG_ CAN_FR_DET_CLASS_181 : 111|4@0+ (1,0) [0|15] ""  IFV
 SG_ CAN_FR_DET_RANGE_182 : 127|14@0+ (0.015625,0) [0|255.984375] "m"  IFV
 SG_ CAN_FR_DET_SD_RANGE_182 : 129|6@0+ (0.025,0) [0|1.5] "m"  IFV
 SG_ CAN_FR_DET_RANGE_RATE_182 : 139|14@0+ (0.015625,-128) [-128|127.984375] "m/s"  IFV
 SG_ CAN_FR_DET_SD_RANGE_RATE_182 : 157|6@0+ (0.02,0) [0|1.2] "m/s"  IFV
 SG_ CAN_FR_DET_AZIMUTH_182 : 167|13@0+ (0.0007668,-3.141593) [-3.141593|3.141593] "rad"  IFV
 SG_ CAN_FR_DET_SD_AZIMUTH_182 : 170|6@0+ (0.001745329,0) [0|0.104719755] "rad"  IFV
 SG_ CAN_FR_DET_ELEVATION_182 : 180|7@0+ (0.157449,-9.99812) [-9.99812|9.997903] "deg"  IFV
 SG_ CAN_FR_DET_SD_ELEVATION_182 : 189|6@0+ (0.003490659,0) [0|0.20943951] "rad"  IFV
 SG_ CAN_FR_DET_AMPLITUDE_182 : 199|7@0+ (1,-64) [-64|63] "dBsm"  IFV
 SG_ CAN_FR_DET_VALID_FLAG_182 : 192|1@0+ (1,0) [0|1] ""  IFV
 SG_ CAN_FR_DET_SUPER_RES_182 : 200|1@0+ (1,0) [0|1] ""  IFV
 SG_ CAN_FR_DET_LOW_SNR_FLAG_182 : 201|1@0+ (1,0) [0|1] ""  IFV
 SG_ CAN_FR_DET_MIXER_BIAS_FLAG_182 : 202|1@0+ (1,0) [0|1] ""  IFV
 SG_ CAN_FR_DET_RESERVED_FLAGS_182 : 207|5@0+ (1,0) [0|31] ""  IFV
 SG_ CAN_FR_DET_SNR_182 : 215|8@0+ (0.35156,0) [0|89.6478] "dB"  IFV
 SG_ CAN_FR_DET_MULTI_TARGET_PROB_182 : 219|4@0+ (0.06667,0) [0|1] ""  IFV
 SG_ CAN_FR_DET_CONFID_AZIMUTH_182 : 221|2@0+ (1,0) [0|3] ""  IFV
 SG_ CAN_FR_DET_CONFID_ELEVATION_182 : 223|2@0+ (1,0) [0|3] ""  IFV
 SG_ CAN_FR_DET_EXISTENCE_PROB_182 : 227|4@0+ (1,0) [0|15] ""  IFV
 SG_ CAN_FR_DET_CLASS_182 : 231|4@0+ (1,0) [0|15] ""  IFV
 SG_ CAN_FR_DET_RANGE_183 : 247|14@0+ (0.015625,0) [0|255.984375] "m"  IFV
 SG_ CAN_FR_DET_SD_RANGE_183 : 249|6@0+ (0.025,0) [0|1.5] "m"  IFV
 SG_ CAN_FR_DET_RANGE_RATE_183 : 259|14@0+ (0.015625,-128) [-128|127.984375] "m/s"  IFV
 SG_ CAN_FR_DET_SD_RANGE_RATE_183 : 277|6@0+ (0.02,0) [0|1.2] "m/s"  IFV
 SG_ CAN_FR_DET_AZIMUTH_183 : 287|13@0+ (0.0007668,-3.141593) [-3.141593|3.141593] "rad"  IFV
 SG_ CAN_FR_DET_SD_AZIMUTH_183 : 290|6@0+ (0.001745329,0) [0|0.104719755] "rad"  IFV
 SG_ CAN_FR_DET_ELEVATION_183 : 300|7@0+ (0.157449,-9.99812) [-9.99812|9.997903] "deg"  IFV
 SG_ CAN_FR_DET_SD_ELEVATION_183 : 309|6@0+ (0.003490659,0) [0|0.20943951] "rad"  IFV
 SG_ CAN_FR_DET_AMPLITUDE_183 : 319|7@0+ (1,-64) [-64|63] "dBsm"  IFV
 SG_ CAN_FR_DET_VALID_FLAG_183 : 312|1@0+ (1,0) [0|1] ""  IFV
 SG_ CAN_FR_DET_SUPER_RES_183 : 320|1@0+ (1,0) [0|1] ""  IFV
 SG_ CAN_FR_DET_LOW_SNR_FLAG_183 : 321|1@0+ (1,0) [0|1] ""  IFV
 SG_ CAN_FR_DET_MIXER_BIAS_FLAG_183 : 322|1@0+ (1,0) [0|1] ""  IFV
 SG_ CAN_FR_DET_RESERVED_FLAGS_183 : 327|5@0+ (1,0) [0|31] ""  IFV
 SG_ CAN_FR_DET_SNR_183 : 335|8@0+ (0.35156,0) [0|89.6478] "dB"  IFV
 SG_ CAN_FR_DET_MULTI_TARGET_PROB_183 : 339|4@0+ (0.06667,0) [0|1] ""  IFV
 SG_ CAN_FR_DET_CONFID_AZIMUTH_183 : 341|2@0+ (1,0) [0|3] ""  IFV
 SG_ CAN_FR_DET_CONFID_ELEVATION_183 : 343|2@0+ (1,0) [0|3] ""  IFV
 SG_ CAN_FR_DET_EXISTENCE_PROB_183 : 347|4@0+ (1,0) [0|15] ""  IFV
 SG_ CAN_FR_DET_CLASS_183 : 351|4@0+ (1,0) [0|15] ""  IFV
 SG_ CAN_FR_DET_RANGE_184 : 367|14@0+ (0.015625,0) [0|255.984375] "m"  IFV
 SG_ CAN_FR_DET_SD_RANGE_184 : 369|6@0+ (0.025,0) [0|1.5] "m"  IFV
 SG_ CAN_FR_DET_RANGE_RATE_184 : 379|14@0+ (0.015625,-128) [-128|127.984375] "m/s"  IFV
 SG_ CAN_FR_DET_SD_RANGE_RATE_184 : 397|6@0+ (0.02,0) [0|1.2] "m/s"  IFV
 SG_ CAN_FR_DET_AZIMUTH_184 : 407|13@0+ (0.0007668,-3.141593) [-3.141593|3.141593] "rad"  IFV
 SG_ CAN_FR_DET_SD_AZIMUTH_184 : 410|6@0+ (0.001745329,0) [0|0.104719755] "rad"  IFV
 SG_ CAN_FR_DET_ELEVATION_184 : 420|7@0+ (0.157449,-9.99812) [-9.99812|9.997903] "deg"  IFV
 SG_ CAN_FR_DET_SD_ELEVATION_184 : 429|6@0+ (0.003490659,0) [0|0.20943951] "rad"  IFV
 SG_ CAN_FR_DET_AMPLITUDE_184 : 439|7@0+ (1,-64) [-64|63] "dBsm"  IFV
 SG_ CAN_FR_DET_VALID_FLAG_184 : 432|1@0+ (1,0) [0|1] ""  IFV
 SG_ CAN_FR_DET_SUPER_RES_184 : 440|1@0+ (1,0) [0|1] ""  IFV
 SG_ CAN_FR_DET_LOW_SNR_FLAG_184 : 441|1@0+ (1,0) [0|1] ""  IFV
 SG_ CAN_FR_DET_MIXER_BIAS_FLAG_184 : 442|1@0+ (1,0) [0|1] ""  IFV
 SG_ CAN_FR_DET_RESERVED_FLAGS_184 : 447|5@0+ (1,0) [0|31] ""  IFV
 SG_ CAN_FR_DET_SNR_184 : 455|8@0+ (0.35156,0) [0|89.6478] "dB"  IFV
 SG_ CAN_FR_DET_MULTI_TARGET_PROB_184 : 459|4@0+ (0.06667,0) [0|1] ""  IFV
 SG_ CAN_FR_DET_CONFID_AZIMUTH_184 : 461|2@0+ (1,0) [0|3] ""  IFV
 SG_ CAN_FR_DET_CONFID_ELEVATION_184 : 463|2@0+ (1,0) [0|3] ""  IFV
 SG_ CAN_FR_DET_EXISTENCE_PROB_184 : 467|4@0+ (1,0) [0|15] ""  IFV
 SG_ CAN_FR_DET_CLASS_184 : 471|4@0+ (1,0) [0|15] ""  IFV

BO_ 1070 SODFR_DETECTION_185_188: 64 SODFR
 SG_ CAN_FR_DET_RANGE_185 : 7|14@0+ (0.015625,0) [0|255.984375] "m"  IFV
 SG_ CAN_FR_DET_SD_RANGE_185 : 9|6@0+ (0.025,0) [0|1.5] "m"  IFV
 SG_ CAN_FR_DET_RANGE_RATE_185 : 19|14@0+ (0.015625,-128) [-128|127.984375] "m/s"  IFV
 SG_ CAN_FR_DET_SD_RANGE_RATE_185 : 37|6@0+ (0.02,0) [0|1.2] "m/s"  IFV
 SG_ CAN_FR_DET_AZIMUTH_185 : 47|13@0+ (0.0007668,-3.141593) [-3.141593|3.141593] "rad"  IFV
 SG_ CAN_FR_DET_SD_AZIMUTH_185 : 50|6@0+ (0.001745329,0) [0|0.104719755] "rad"  IFV
 SG_ CAN_FR_DET_ELEVATION_185 : 60|7@0+ (0.157449,-9.99812) [-9.99812|9.997903] "deg"  IFV
 SG_ CAN_FR_DET_SD_ELEVATION_185 : 69|6@0+ (0.003490659,0) [0|0.20943951] "rad"  IFV
 SG_ CAN_FR_DET_AMPLITUDE_185 : 79|7@0+ (1,-64) [-64|63] "dBsm"  IFV
 SG_ CAN_FR_DET_VALID_FLAG_185 : 72|1@0+ (1,0) [0|1] ""  IFV
 SG_ CAN_FR_DET_SUPER_RES_185 : 80|1@0+ (1,0) [0|1] ""  IFV
 SG_ CAN_FR_DET_LOW_SNR_FLAG_185 : 81|1@0+ (1,0) [0|1] ""  IFV
 SG_ CAN_FR_DET_MIXER_BIAS_FLAG_185 : 82|1@0+ (1,0) [0|1] ""  IFV
 SG_ CAN_FR_DET_RESERVED_FLAGS_185 : 87|5@0+ (1,0) [0|31] ""  IFV
 SG_ CAN_FR_DET_SNR_185 : 95|8@0+ (0.35156,0) [0|89.6478] "dB"  IFV
 SG_ CAN_FR_DET_MULTI_TARGET_PROB_185 : 99|4@0+ (0.06667,0) [0|1] ""  IFV
 SG_ CAN_FR_DET_CONFID_AZIMUTH_185 : 101|2@0+ (1,0) [0|3] ""  IFV
 SG_ CAN_FR_DET_CONFID_ELEVATION_185 : 103|2@0+ (1,0) [0|3] ""  IFV
 SG_ CAN_FR_DET_EXISTENCE_PROB_185 : 107|4@0+ (1,0) [0|15] ""  IFV
 SG_ CAN_FR_DET_CLASS_185 : 111|4@0+ (1,0) [0|15] ""  IFV
 SG_ CAN_FR_DET_RANGE_186 : 127|14@0+ (0.015625,0) [0|255.984375] "m"  IFV
 SG_ CAN_FR_DET_SD_RANGE_186 : 129|6@0+ (0.025,0) [0|1.5] "m"  IFV
 SG_ CAN_FR_DET_RANGE_RATE_186 : 139|14@0+ (0.015625,-128) [-128|127.984375] "m/s"  IFV
 SG_ CAN_FR_DET_SD_RANGE_RATE_186 : 157|6@0+ (0.02,0) [0|1.2] "m/s"  IFV
 SG_ CAN_FR_DET_AZIMUTH_186 : 167|13@0+ (0.0007668,-3.141593) [-3.141593|3.141593] "rad"  IFV
 SG_ CAN_FR_DET_SD_AZIMUTH_186 : 170|6@0+ (0.001745329,0) [0|0.104719755] "rad"  IFV
 SG_ CAN_FR_DET_ELEVATION_186 : 180|7@0+ (0.157449,-9.99812) [-9.99812|9.997903] "deg"  IFV
 SG_ CAN_FR_DET_SD_ELEVATION_186 : 189|6@0+ (0.003490659,0) [0|0.20943951] "rad"  IFV
 SG_ CAN_FR_DET_AMPLITUDE_186 : 199|7@0+ (1,-64) [-64|63] "dBsm"  IFV
 SG_ CAN_FR_DET_VALID_FLAG_186 : 192|1@0+ (1,0) [0|1] ""  IFV
 SG_ CAN_FR_DET_SUPER_RES_186 : 200|1@0+ (1,0) [0|1] ""  IFV
 SG_ CAN_FR_DET_LOW_SNR_FLAG_186 : 201|1@0+ (1,0) [0|1] ""  IFV
 SG_ CAN_FR_DET_MIXER_BIAS_FLAG_186 : 202|1@0+ (1,0) [0|1] ""  IFV
 SG_ CAN_FR_DET_RESERVED_FLAGS_186 : 207|5@0+ (1,0) [0|31] ""  IFV
 SG_ CAN_FR_DET_SNR_186 : 215|8@0+ (0.35156,0) [0|89.6478] "dB"  IFV
 SG_ CAN_FR_DET_MULTI_TARGET_PROB_186 : 219|4@0+ (0.06667,0) [0|1] ""  IFV
 SG_ CAN_FR_DET_CONFID_AZIMUTH_186 : 221|2@0+ (1,0) [0|3] ""  IFV
 SG_ CAN_FR_DET_CONFID_ELEVATION_186 : 223|2@0+ (1,0) [0|3] ""  IFV
 SG_ CAN_FR_DET_EXISTENCE_PROB_186 : 227|4@0+ (1,0) [0|15] ""  IFV
 SG_ CAN_FR_DET_CLASS_186 : 231|4@0+ (1,0) [0|15] ""  IFV
 SG_ CAN_FR_DET_RANGE_187 : 247|14@0+ (0.015625,0) [0|255.984375] "m"  IFV
 SG_ CAN_FR_DET_SD_RANGE_187 : 249|6@0+ (0.025,0) [0|1.5] "m"  IFV
 SG_ CAN_FR_DET_RANGE_RATE_187 : 259|14@0+ (0.015625,-128) [-128|127.984375] "m/s"  IFV
 SG_ CAN_FR_DET_SD_RANGE_RATE_187 : 277|6@0+ (0.02,0) [0|1.2] "m/s"  IFV
 SG_ CAN_FR_DET_AZIMUTH_187 : 287|13@0+ (0.0007668,-3.141593) [-3.141593|3.141593] "rad"  IFV
 SG_ CAN_FR_DET_SD_AZIMUTH_187 : 290|6@0+ (0.001745329,0) [0|0.104719755] "rad"  IFV
 SG_ CAN_FR_DET_ELEVATION_187 : 300|7@0+ (0.157449,-9.99812) [-9.99812|9.997903] "deg"  IFV
 SG_ CAN_FR_DET_SD_ELEVATION_187 : 309|6@0+ (0.003490659,0) [0|0.20943951] "rad"  IFV
 SG_ CAN_FR_DET_AMPLITUDE_187 : 319|7@0+ (1,-64) [-64|63] "dBsm"  IFV
 SG_ CAN_FR_DET_VALID_FLAG_187 : 312|1@0+ (1,0) [0|1] ""  IFV
 SG_ CAN_FR_DET_SUPER_RES_187 : 320|1@0+ (1,0) [0|1] ""  IFV
 SG_ CAN_FR_DET_LOW_SNR_FLAG_187 : 321|1@0+ (1,0) [0|1] ""  IFV
 SG_ CAN_FR_DET_MIXER_BIAS_FLAG_187 : 322|1@0+ (1,0) [0|1] ""  IFV
 SG_ CAN_FR_DET_RESERVED_FLAGS_187 : 327|5@0+ (1,0) [0|31] ""  IFV
 SG_ CAN_FR_DET_SNR_187 : 335|8@0+ (0.35156,0) [0|89.6478] "dB"  IFV
 SG_ CAN_FR_DET_MULTI_TARGET_PROB_187 : 339|4@0+ (0.06667,0) [0|1] ""  IFV
 SG_ CAN_FR_DET_CONFID_AZIMUTH_187 : 341|2@0+ (1,0) [0|3] ""  IFV
 SG_ CAN_FR_DET_CONFID_ELEVATION_187 : 343|2@0+ (1,0) [0|3] ""  IFV
 SG_ CAN_FR_DET_EXISTENCE_PROB_187 : 347|4@0+ (1,0) [0|15] ""  IFV
 SG_ CAN_FR_DET_CLASS_187 : 351|4@0+ (1,0) [0|15] ""  IFV
 SG_ CAN_FR_DET_RANGE_188 : 367|14@0+ (0.015625,0) [0|255.984375] "m"  IFV
 SG_ CAN_FR_DET_SD_RANGE_188 : 369|6@0+ (0.025,0) [0|1.5] "m"  IFV
 SG_ CAN_FR_DET_RANGE_RATE_188 : 379|14@0+ (0.015625,-128) [-128|127.984375] "m/s"  IFV
 SG_ CAN_FR_DET_SD_RANGE_RATE_188 : 397|6@0+ (0.02,0) [0|1.2] "m/s"  IFV
 SG_ CAN_FR_DET_AZIMUTH_188 : 407|13@0+ (0.0007668,-3.141593) [-3.141593|3.141593] "rad"  IFV
 SG_ CAN_FR_DET_SD_AZIMUTH_188 : 410|6@0+ (0.001745329,0) [0|0.104719755] "rad"  IFV
 SG_ CAN_FR_DET_ELEVATION_188 : 420|7@0+ (0.157449,-9.99812) [-9.99812|9.997903] "deg"  IFV
 SG_ CAN_FR_DET_SD_ELEVATION_188 : 429|6@0+ (0.003490659,0) [0|0.20943951] "rad"  IFV
 SG_ CAN_FR_DET_AMPLITUDE_188 : 439|7@0+ (1,-64) [-64|63] "dBsm"  IFV
 SG_ CAN_FR_DET_VALID_FLAG_188 : 432|1@0+ (1,0) [0|1] ""  IFV
 SG_ CAN_FR_DET_SUPER_RES_188 : 440|1@0+ (1,0) [0|1] ""  IFV
 SG_ CAN_FR_DET_LOW_SNR_FLAG_188 : 441|1@0+ (1,0) [0|1] ""  IFV
 SG_ CAN_FR_DET_MIXER_BIAS_FLAG_188 : 442|1@0+ (1,0) [0|1] ""  IFV
 SG_ CAN_FR_DET_RESERVED_FLAGS_188 : 447|5@0+ (1,0) [0|31] ""  IFV
 SG_ CAN_FR_DET_SNR_188 : 455|8@0+ (0.35156,0) [0|89.6478] "dB"  IFV
 SG_ CAN_FR_DET_MULTI_TARGET_PROB_188 : 459|4@0+ (0.06667,0) [0|1] ""  IFV
 SG_ CAN_FR_DET_CONFID_AZIMUTH_188 : 461|2@0+ (1,0) [0|3] ""  IFV
 SG_ CAN_FR_DET_CONFID_ELEVATION_188 : 463|2@0+ (1,0) [0|3] ""  IFV
 SG_ CAN_FR_DET_EXISTENCE_PROB_188 : 467|4@0+ (1,0) [0|15] ""  IFV
 SG_ CAN_FR_DET_CLASS_188 : 471|4@0+ (1,0) [0|15] ""  IFV

BO_ 1071 SODFR_DETECTION_189_192: 64 SODFR
 SG_ CAN_FR_DET_RANGE_189 : 7|14@0+ (0.015625,0) [0|255.984375] "m"  IFV
 SG_ CAN_FR_DET_SD_RANGE_189 : 9|6@0+ (0.025,0) [0|1.5] "m"  IFV
 SG_ CAN_FR_DET_RANGE_RATE_189 : 19|14@0+ (0.015625,-128) [-128|127.984375] "m/s"  IFV
 SG_ CAN_FR_DET_SD_RANGE_RATE_189 : 37|6@0+ (0.02,0) [0|1.2] "m/s"  IFV
 SG_ CAN_FR_DET_AZIMUTH_189 : 47|13@0+ (0.0007668,-3.141593) [-3.141593|3.141593] "rad"  IFV
 SG_ CAN_FR_DET_SD_AZIMUTH_189 : 50|6@0+ (0.001745329,0) [0|0.104719755] "rad"  IFV
 SG_ CAN_FR_DET_ELEVATION_189 : 60|7@0+ (0.157449,-9.99812) [-9.99812|9.997903] "deg"  IFV
 SG_ CAN_FR_DET_SD_ELEVATION_189 : 69|6@0+ (0.003490659,0) [0|0.20943951] "rad"  IFV
 SG_ CAN_FR_DET_AMPLITUDE_189 : 79|7@0+ (1,-64) [-64|63] "dBsm"  IFV
 SG_ CAN_FR_DET_VALID_FLAG_189 : 72|1@0+ (1,0) [0|1] ""  IFV
 SG_ CAN_FR_DET_SUPER_RES_189 : 80|1@0+ (1,0) [0|1] ""  IFV
 SG_ CAN_FR_DET_LOW_SNR_FLAG_189 : 81|1@0+ (1,0) [0|1] ""  IFV
 SG_ CAN_FR_DET_MIXER_BIAS_FLAG_189 : 82|1@0+ (1,0) [0|1] ""  IFV
 SG_ CAN_FR_DET_RESERVED_FLAGS_189 : 87|5@0+ (1,0) [0|31] ""  IFV
 SG_ CAN_FR_DET_SNR_189 : 95|8@0+ (0.35156,0) [0|89.6478] "dB"  IFV
 SG_ CAN_FR_DET_MULTI_TARGET_PROB_189 : 99|4@0+ (0.06667,0) [0|1] ""  IFV
 SG_ CAN_FR_DET_CONFID_AZIMUTH_189 : 101|2@0+ (1,0) [0|3] ""  IFV
 SG_ CAN_FR_DET_CONFID_ELEVATION_189 : 103|2@0+ (1,0) [0|3] ""  IFV
 SG_ CAN_FR_DET_EXISTENCE_PROB_189 : 107|4@0+ (1,0) [0|15] ""  IFV
 SG_ CAN_FR_DET_CLASS_189 : 111|4@0+ (1,0) [0|15] ""  IFV
 SG_ CAN_FR_DET_RANGE_190 : 127|14@0+ (0.015625,0) [0|255.984375] "m"  IFV
 SG_ CAN_FR_DET_SD_RANGE_190 : 129|6@0+ (0.025,0) [0|1.5] "m"  IFV
 SG_ CAN_FR_DET_RANGE_RATE_190 : 139|14@0+ (0.015625,-128) [-128|127.984375] "m/s"  IFV
 SG_ CAN_FR_DET_SD_RANGE_RATE_190 : 157|6@0+ (0.02,0) [0|1.2] "m/s"  IFV
 SG_ CAN_FR_DET_AZIMUTH_190 : 167|13@0+ (0.0007668,-3.141593) [-3.141593|3.141593] "rad"  IFV
 SG_ CAN_FR_DET_SD_AZIMUTH_190 : 170|6@0+ (0.001745329,0) [0|0.104719755] "rad"  IFV
 SG_ CAN_FR_DET_ELEVATION_190 : 180|7@0+ (0.157449,-9.99812) [-9.99812|9.997903] "deg"  IFV
 SG_ CAN_FR_DET_SD_ELEVATION_190 : 189|6@0+ (0.003490659,0) [0|0.20943951] "rad"  IFV
 SG_ CAN_FR_DET_AMPLITUDE_190 : 199|7@0+ (1,-64) [-64|63] "dBsm"  IFV
 SG_ CAN_FR_DET_VALID_FLAG_190 : 192|1@0+ (1,0) [0|1] ""  IFV
 SG_ CAN_FR_DET_SUPER_RES_190 : 200|1@0+ (1,0) [0|1] ""  IFV
 SG_ CAN_FR_DET_LOW_SNR_FLAG_190 : 201|1@0+ (1,0) [0|1] ""  IFV
 SG_ CAN_FR_DET_MIXER_BIAS_FLAG_190 : 202|1@0+ (1,0) [0|1] ""  IFV
 SG_ CAN_FR_DET_RESERVED_FLAGS_190 : 207|5@0+ (1,0) [0|31] ""  IFV
 SG_ CAN_FR_DET_SNR_190 : 215|8@0+ (0.35156,0) [0|89.6478] "dB"  IFV
 SG_ CAN_FR_DET_MULTI_TARGET_PROB_190 : 219|4@0+ (0.06667,0) [0|1] ""  IFV
 SG_ CAN_FR_DET_CONFID_AZIMUTH_190 : 221|2@0+ (1,0) [0|3] ""  IFV
 SG_ CAN_FR_DET_CONFID_ELEVATION_190 : 223|2@0+ (1,0) [0|3] ""  IFV
 SG_ CAN_FR_DET_EXISTENCE_PROB_190 : 227|4@0+ (1,0) [0|15] ""  IFV
 SG_ CAN_FR_DET_CLASS_190 : 231|4@0+ (1,0) [0|15] ""  IFV
 SG_ CAN_FR_DET_RANGE_191 : 247|14@0+ (0.015625,0) [0|255.984375] "m"  IFV
 SG_ CAN_FR_DET_SD_RANGE_191 : 249|6@0+ (0.025,0) [0|1.5] "m"  IFV
 SG_ CAN_FR_DET_RANGE_RATE_191 : 259|14@0+ (0.015625,-128) [-128|127.984375] "m/s"  IFV
 SG_ CAN_FR_DET_SD_RANGE_RATE_191 : 277|6@0+ (0.02,0) [0|1.2] "m/s"  IFV
 SG_ CAN_FR_DET_AZIMUTH_191 : 287|13@0+ (0.0007668,-3.141593) [-3.141593|3.141593] "rad"  IFV
 SG_ CAN_FR_DET_SD_AZIMUTH_191 : 290|6@0+ (0.001745329,0) [0|0.104719755] "rad"  IFV
 SG_ CAN_FR_DET_ELEVATION_191 : 300|7@0+ (0.157449,-9.99812) [-9.99812|9.997903] "deg"  IFV
 SG_ CAN_FR_DET_SD_ELEVATION_191 : 309|6@0+ (0.003490659,0) [0|0.20943951] "rad"  IFV
 SG_ CAN_FR_DET_AMPLITUDE_191 : 319|7@0+ (1,-64) [-64|63] "dBsm"  IFV
 SG_ CAN_FR_DET_VALID_FLAG_191 : 312|1@0+ (1,0) [0|1] ""  IFV
 SG_ CAN_FR_DET_SUPER_RES_191 : 320|1@0+ (1,0) [0|1] ""  IFV
 SG_ CAN_FR_DET_LOW_SNR_FLAG_191 : 321|1@0+ (1,0) [0|1] ""  IFV
 SG_ CAN_FR_DET_MIXER_BIAS_FLAG_191 : 322|1@0+ (1,0) [0|1] ""  IFV
 SG_ CAN_FR_DET_RESERVED_FLAGS_191 : 327|5@0+ (1,0) [0|31] ""  IFV
 SG_ CAN_FR_DET_SNR_191 : 335|8@0+ (0.35156,0) [0|89.6478] "dB"  IFV
 SG_ CAN_FR_DET_MULTI_TARGET_PROB_191 : 339|4@0+ (0.06667,0) [0|1] ""  IFV
 SG_ CAN_FR_DET_CONFID_AZIMUTH_191 : 341|2@0+ (1,0) [0|3] ""  IFV
 SG_ CAN_FR_DET_CONFID_ELEVATION_191 : 343|2@0+ (1,0) [0|3] ""  IFV
 SG_ CAN_FR_DET_EXISTENCE_PROB_191 : 347|4@0+ (1,0) [0|15] ""  IFV
 SG_ CAN_FR_DET_CLASS_191 : 351|4@0+ (1,0) [0|15] ""  IFV
 SG_ CAN_FR_DET_RANGE_192 : 367|14@0+ (0.015625,0) [0|255.984375] "m"  IFV
 SG_ CAN_FR_DET_SD_RANGE_192 : 369|6@0+ (0.025,0) [0|1.5] "m"  IFV
 SG_ CAN_FR_DET_RANGE_RATE_192 : 379|14@0+ (0.015625,-128) [-128|127.984375] "m/s"  IFV
 SG_ CAN_FR_DET_SD_RANGE_RATE_192 : 397|6@0+ (0.02,0) [0|1.2] "m/s"  IFV
 SG_ CAN_FR_DET_AZIMUTH_192 : 407|13@0+ (0.0007668,-3.141593) [-3.141593|3.141593] "rad"  IFV
 SG_ CAN_FR_DET_SD_AZIMUTH_192 : 410|6@0+ (0.001745329,0) [0|0.104719755] "rad"  IFV
 SG_ CAN_FR_DET_ELEVATION_192 : 420|7@0+ (0.157449,-9.99812) [-9.99812|9.997903] "deg"  IFV
 SG_ CAN_FR_DET_SD_ELEVATION_192 : 429|6@0+ (0.003490659,0) [0|0.20943951] "rad"  IFV
 SG_ CAN_FR_DET_AMPLITUDE_192 : 439|7@0+ (1,-64) [-64|63] "dBsm"  IFV
 SG_ CAN_FR_DET_VALID_FLAG_192 : 432|1@0+ (1,0) [0|1] ""  IFV
 SG_ CAN_FR_DET_SUPER_RES_192 : 440|1@0+ (1,0) [0|1] ""  IFV
 SG_ CAN_FR_DET_LOW_SNR_FLAG_192 : 441|1@0+ (1,0) [0|1] ""  IFV
 SG_ CAN_FR_DET_MIXER_BIAS_FLAG_192 : 442|1@0+ (1,0) [0|1] ""  IFV
 SG_ CAN_FR_DET_RESERVED_FLAGS_192 : 447|5@0+ (1,0) [0|31] ""  IFV
 SG_ CAN_FR_DET_SNR_192 : 455|8@0+ (0.35156,0) [0|89.6478] "dB"  IFV
 SG_ CAN_FR_DET_MULTI_TARGET_PROB_192 : 459|4@0+ (0.06667,0) [0|1] ""  IFV
 SG_ CAN_FR_DET_CONFID_AZIMUTH_192 : 461|2@0+ (1,0) [0|3] ""  IFV
 SG_ CAN_FR_DET_CONFID_ELEVATION_192 : 463|2@0+ (1,0) [0|3] ""  IFV
 SG_ CAN_FR_DET_EXISTENCE_PROB_192 : 467|4@0+ (1,0) [0|15] ""  IFV
 SG_ CAN_FR_DET_CLASS_192 : 471|4@0+ (1,0) [0|15] ""  IFV

BO_ 1072 SODFR_DETECTION_193_196: 64 SODFR
 SG_ CAN_FR_DET_RANGE_193 : 7|14@0+ (0.015625,0) [0|255.984375] "m"  IFV
 SG_ CAN_FR_DET_SD_RANGE_193 : 9|6@0+ (0.025,0) [0|1.5] "m"  IFV
 SG_ CAN_FR_DET_RANGE_RATE_193 : 19|14@0+ (0.015625,-128) [-128|127.984375] "m/s"  IFV
 SG_ CAN_FR_DET_SD_RANGE_RATE_193 : 37|6@0+ (0.02,0) [0|1.2] "m/s"  IFV
 SG_ CAN_FR_DET_AZIMUTH_193 : 47|13@0+ (0.0007668,-3.141593) [-3.141593|3.141593] "rad"  IFV
 SG_ CAN_FR_DET_SD_AZIMUTH_193 : 50|6@0+ (0.001745329,0) [0|0.104719755] "rad"  IFV
 SG_ CAN_FR_DET_ELEVATION_193 : 60|7@0+ (0.157449,-9.99812) [-9.99812|9.997903] "deg"  IFV
 SG_ CAN_FR_DET_SD_ELEVATION_193 : 69|6@0+ (0.003490659,0) [0|0.20943951] "rad"  IFV
 SG_ CAN_FR_DET_AMPLITUDE_193 : 79|7@0+ (1,-64) [-64|63] "dBsm"  IFV
 SG_ CAN_FR_DET_VALID_FLAG_193 : 72|1@0+ (1,0) [0|1] ""  IFV
 SG_ CAN_FR_DET_SUPER_RES_193 : 80|1@0+ (1,0) [0|1] ""  IFV
 SG_ CAN_FR_DET_LOW_SNR_FLAG_193 : 81|1@0+ (1,0) [0|1] ""  IFV
 SG_ CAN_FR_DET_MIXER_BIAS_FLAG_193 : 82|1@0+ (1,0) [0|1] ""  IFV
 SG_ CAN_FR_DET_RESERVED_FLAGS_193 : 87|5@0+ (1,0) [0|31] ""  IFV
 SG_ CAN_FR_DET_SNR_193 : 95|8@0+ (0.35156,0) [0|89.6478] "dB"  IFV
 SG_ CAN_FR_DET_MULTI_TARGET_PROB_193 : 99|4@0+ (0.06667,0) [0|1] ""  IFV
 SG_ CAN_FR_DET_CONFID_AZIMUTH_193 : 101|2@0+ (1,0) [0|3] ""  IFV
 SG_ CAN_FR_DET_CONFID_ELEVATION_193 : 103|2@0+ (1,0) [0|3] ""  IFV
 SG_ CAN_FR_DET_EXISTENCE_PROB_193 : 107|4@0+ (1,0) [0|15] ""  IFV
 SG_ CAN_FR_DET_CLASS_193 : 111|4@0+ (1,0) [0|15] ""  IFV
 SG_ CAN_FR_DET_RANGE_194 : 127|14@0+ (0.015625,0) [0|255.984375] "m"  IFV
 SG_ CAN_FR_DET_SD_RANGE_194 : 129|6@0+ (0.025,0) [0|1.5] "m"  IFV
 SG_ CAN_FR_DET_RANGE_RATE_194 : 139|14@0+ (0.015625,-128) [-128|127.984375] "m/s"  IFV
 SG_ CAN_FR_DET_SD_RANGE_RATE_194 : 157|6@0+ (0.02,0) [0|1.2] "m/s"  IFV
 SG_ CAN_FR_DET_AZIMUTH_194 : 167|13@0+ (0.0007668,-3.141593) [-3.141593|3.141593] "rad"  IFV
 SG_ CAN_FR_DET_SD_AZIMUTH_194 : 170|6@0+ (0.001745329,0) [0|0.104719755] "rad"  IFV
 SG_ CAN_FR_DET_ELEVATION_194 : 180|7@0+ (0.157449,-9.99812) [-9.99812|9.997903] "deg"  IFV
 SG_ CAN_FR_DET_SD_ELEVATION_194 : 189|6@0+ (0.003490659,0) [0|0.20943951] "rad"  IFV
 SG_ CAN_FR_DET_AMPLITUDE_194 : 199|7@0+ (1,-64) [-64|63] "dBsm"  IFV
 SG_ CAN_FR_DET_VALID_FLAG_194 : 192|1@0+ (1,0) [0|1] ""  IFV
 SG_ CAN_FR_DET_SUPER_RES_194 : 200|1@0+ (1,0) [0|1] ""  IFV
 SG_ CAN_FR_DET_LOW_SNR_FLAG_194 : 201|1@0+ (1,0) [0|1] ""  IFV
 SG_ CAN_FR_DET_MIXER_BIAS_FLAG_194 : 202|1@0+ (1,0) [0|1] ""  IFV
 SG_ CAN_FR_DET_RESERVED_FLAGS_194 : 207|5@0+ (1,0) [0|31] ""  IFV
 SG_ CAN_FR_DET_SNR_194 : 215|8@0+ (0.35156,0) [0|89.6478] "dB"  IFV
 SG_ CAN_FR_DET_MULTI_TARGET_PROB_194 : 219|4@0+ (0.06667,0) [0|1] ""  IFV
 SG_ CAN_FR_DET_CONFID_AZIMUTH_194 : 221|2@0+ (1,0) [0|3] ""  IFV
 SG_ CAN_FR_DET_CONFID_ELEVATION_194 : 223|2@0+ (1,0) [0|3] ""  IFV
 SG_ CAN_FR_DET_EXISTENCE_PROB_194 : 227|4@0+ (1,0) [0|15] ""  IFV
 SG_ CAN_FR_DET_CLASS_194 : 231|4@0+ (1,0) [0|15] ""  IFV
 SG_ CAN_FR_DET_RANGE_195 : 247|14@0+ (0.015625,0) [0|255.984375] "m"  IFV
 SG_ CAN_FR_DET_SD_RANGE_195 : 249|6@0+ (0.025,0) [0|1.5] "m"  IFV
 SG_ CAN_FR_DET_RANGE_RATE_195 : 259|14@0+ (0.015625,-128) [-128|127.984375] "m/s"  IFV
 SG_ CAN_FR_DET_SD_RANGE_RATE_195 : 277|6@0+ (0.02,0) [0|1.2] "m/s"  IFV
 SG_ CAN_FR_DET_AZIMUTH_195 : 287|13@0+ (0.0007668,-3.141593) [-3.141593|3.141593] "rad"  IFV
 SG_ CAN_FR_DET_SD_AZIMUTH_195 : 290|6@0+ (0.001745329,0) [0|0.104719755] "rad"  IFV
 SG_ CAN_FR_DET_ELEVATION_195 : 300|7@0+ (0.157449,-9.99812) [-9.99812|9.997903] "deg"  IFV
 SG_ CAN_FR_DET_SD_ELEVATION_195 : 309|6@0+ (0.003490659,0) [0|0.20943951] "rad"  IFV
 SG_ CAN_FR_DET_AMPLITUDE_195 : 319|7@0+ (1,-64) [-64|63] "dBsm"  IFV
 SG_ CAN_FR_DET_VALID_FLAG_195 : 312|1@0+ (1,0) [0|1] ""  IFV
 SG_ CAN_FR_DET_SUPER_RES_195 : 320|1@0+ (1,0) [0|1] ""  IFV
 SG_ CAN_FR_DET_LOW_SNR_FLAG_195 : 321|1@0+ (1,0) [0|1] ""  IFV
 SG_ CAN_FR_DET_MIXER_BIAS_FLAG_195 : 322|1@0+ (1,0) [0|1] ""  IFV
 SG_ CAN_FR_DET_RESERVED_FLAGS_195 : 327|5@0+ (1,0) [0|31] ""  IFV
 SG_ CAN_FR_DET_SNR_195 : 335|8@0+ (0.35156,0) [0|89.6478] "dB"  IFV
 SG_ CAN_FR_DET_MULTI_TARGET_PROB_195 : 339|4@0+ (0.06667,0) [0|1] ""  IFV
 SG_ CAN_FR_DET_CONFID_AZIMUTH_195 : 341|2@0+ (1,0) [0|3] ""  IFV
 SG_ CAN_FR_DET_CONFID_ELEVATION_195 : 343|2@0+ (1,0) [0|3] ""  IFV
 SG_ CAN_FR_DET_EXISTENCE_PROB_195 : 347|4@0+ (1,0) [0|15] ""  IFV
 SG_ CAN_FR_DET_CLASS_195 : 351|4@0+ (1,0) [0|15] ""  IFV
 SG_ CAN_FR_DET_RANGE_196 : 367|14@0+ (0.015625,0) [0|255.984375] "m"  IFV
 SG_ CAN_FR_DET_SD_RANGE_196 : 369|6@0+ (0.025,0) [0|1.5] "m"  IFV
 SG_ CAN_FR_DET_RANGE_RATE_196 : 379|14@0+ (0.015625,-128) [-128|127.984375] "m/s"  IFV
 SG_ CAN_FR_DET_SD_RANGE_RATE_196 : 397|6@0+ (0.02,0) [0|1.2] "m/s"  IFV
 SG_ CAN_FR_DET_AZIMUTH_196 : 407|13@0+ (0.0007668,-3.141593) [-3.141593|3.141593] "rad"  IFV
 SG_ CAN_FR_DET_SD_AZIMUTH_196 : 410|6@0+ (0.001745329,0) [0|0.104719755] "rad"  IFV
 SG_ CAN_FR_DET_ELEVATION_196 : 420|7@0+ (0.157449,-9.99812) [-9.99812|9.997903] "deg"  IFV
 SG_ CAN_FR_DET_SD_ELEVATION_196 : 429|6@0+ (0.003490659,0) [0|0.20943951] "rad"  IFV
 SG_ CAN_FR_DET_AMPLITUDE_196 : 439|7@0+ (1,-64) [-64|63] "dBsm"  IFV
 SG_ CAN_FR_DET_VALID_FLAG_196 : 432|1@0+ (1,0) [0|1] ""  IFV
 SG_ CAN_FR_DET_SUPER_RES_196 : 440|1@0+ (1,0) [0|1] ""  IFV
 SG_ CAN_FR_DET_LOW_SNR_FLAG_196 : 441|1@0+ (1,0) [0|1] ""  IFV
 SG_ CAN_FR_DET_MIXER_BIAS_FLAG_196 : 442|1@0+ (1,0) [0|1] ""  IFV
 SG_ CAN_FR_DET_RESERVED_FLAGS_196 : 447|5@0+ (1,0) [0|31] ""  IFV
 SG_ CAN_FR_DET_SNR_196 : 455|8@0+ (0.35156,0) [0|89.6478] "dB"  IFV
 SG_ CAN_FR_DET_MULTI_TARGET_PROB_196 : 459|4@0+ (0.06667,0) [0|1] ""  IFV
 SG_ CAN_FR_DET_CONFID_AZIMUTH_196 : 461|2@0+ (1,0) [0|3] ""  IFV
 SG_ CAN_FR_DET_CONFID_ELEVATION_196 : 463|2@0+ (1,0) [0|3] ""  IFV
 SG_ CAN_FR_DET_EXISTENCE_PROB_196 : 467|4@0+ (1,0) [0|15] ""  IFV
 SG_ CAN_FR_DET_CLASS_196 : 471|4@0+ (1,0) [0|15] ""  IFV

BO_ 1073 SODFR_DETECTION_197_200: 64 SODFR
 SG_ CAN_FR_DET_RANGE_197 : 7|14@0+ (0.015625,0) [0|255.984375] "m"  IFV
 SG_ CAN_FR_DET_SD_RANGE_197 : 9|6@0+ (0.025,0) [0|1.5] "m"  IFV
 SG_ CAN_FR_DET_RANGE_RATE_197 : 19|14@0+ (0.015625,-128) [-128|127.984375] "m/s"  IFV
 SG_ CAN_FR_DET_SD_RANGE_RATE_197 : 37|6@0+ (0.02,0) [0|1.2] "m/s"  IFV
 SG_ CAN_FR_DET_AZIMUTH_197 : 47|13@0+ (0.0007668,-3.141593) [-3.141593|3.141593] "rad"  IFV
 SG_ CAN_FR_DET_SD_AZIMUTH_197 : 50|6@0+ (0.001745329,0) [0|0.104719755] "rad"  IFV
 SG_ CAN_FR_DET_ELEVATION_197 : 60|7@0+ (0.157449,-9.99812) [-9.99812|9.997903] "deg"  IFV
 SG_ CAN_FR_DET_SD_ELEVATION_197 : 69|6@0+ (0.003490659,0) [0|0.20943951] "rad"  IFV
 SG_ CAN_FR_DET_AMPLITUDE_197 : 79|7@0+ (1,-64) [-64|63] "dBsm"  IFV
 SG_ CAN_FR_DET_VALID_FLAG_197 : 72|1@0+ (1,0) [0|1] ""  IFV
 SG_ CAN_FR_DET_SUPER_RES_197 : 80|1@0+ (1,0) [0|1] ""  IFV
 SG_ CAN_FR_DET_LOW_SNR_FLAG_197 : 81|1@0+ (1,0) [0|1] ""  IFV
 SG_ CAN_FR_DET_MIXER_BIAS_FLAG_197 : 82|1@0+ (1,0) [0|1] ""  IFV
 SG_ CAN_FR_DET_RESERVED_FLAGS_197 : 87|5@0+ (1,0) [0|31] ""  IFV
 SG_ CAN_FR_DET_SNR_197 : 95|8@0+ (0.35156,0) [0|89.6478] "dB"  IFV
 SG_ CAN_FR_DET_MULTI_TARGET_PROB_197 : 99|4@0+ (0.06667,0) [0|1] ""  IFV
 SG_ CAN_FR_DET_CONFID_AZIMUTH_197 : 101|2@0+ (1,0) [0|3] ""  IFV
 SG_ CAN_FR_DET_CONFID_ELEVATION_197 : 103|2@0+ (1,0) [0|3] ""  IFV
 SG_ CAN_FR_DET_EXISTENCE_PROB_197 : 107|4@0+ (1,0) [0|15] ""  IFV
 SG_ CAN_FR_DET_CLASS_197 : 111|4@0+ (1,0) [0|15] ""  IFV
 SG_ CAN_FR_DET_RANGE_198 : 127|14@0+ (0.015625,0) [0|255.984375] "m"  IFV
 SG_ CAN_FR_DET_SD_RANGE_198 : 129|6@0+ (0.025,0) [0|1.5] "m"  IFV
 SG_ CAN_FR_DET_RANGE_RATE_198 : 139|14@0+ (0.015625,-128) [-128|127.984375] "m/s"  IFV
 SG_ CAN_FR_DET_SD_RANGE_RATE_198 : 157|6@0+ (0.02,0) [0|1.2] "m/s"  IFV
 SG_ CAN_FR_DET_AZIMUTH_198 : 167|13@0+ (0.0007668,-3.141593) [-3.141593|3.141593] "rad"  IFV
 SG_ CAN_FR_DET_SD_AZIMUTH_198 : 170|6@0+ (0.001745329,0) [0|0.104719755] "rad"  IFV
 SG_ CAN_FR_DET_ELEVATION_198 : 180|7@0+ (0.157449,-9.99812) [-9.99812|9.997903] "deg"  IFV
 SG_ CAN_FR_DET_SD_ELEVATION_198 : 189|6@0+ (0.003490659,0) [0|0.20943951] "rad"  IFV
 SG_ CAN_FR_DET_AMPLITUDE_198 : 199|7@0+ (1,-64) [-64|63] "dBsm"  IFV
 SG_ CAN_FR_DET_VALID_FLAG_198 : 192|1@0+ (1,0) [0|1] ""  IFV
 SG_ CAN_FR_DET_SUPER_RES_198 : 200|1@0+ (1,0) [0|1] ""  IFV
 SG_ CAN_FR_DET_LOW_SNR_FLAG_198 : 201|1@0+ (1,0) [0|1] ""  IFV
 SG_ CAN_FR_DET_MIXER_BIAS_FLAG_198 : 202|1@0+ (1,0) [0|1] ""  IFV
 SG_ CAN_FR_DET_RESERVED_FLAGS_198 : 207|5@0+ (1,0) [0|31] ""  IFV
 SG_ CAN_FR_DET_SNR_198 : 215|8@0+ (0.35156,0) [0|89.6478] "dB"  IFV
 SG_ CAN_FR_DET_MULTI_TARGET_PROB_198 : 219|4@0+ (0.06667,0) [0|1] ""  IFV
 SG_ CAN_FR_DET_CONFID_AZIMUTH_198 : 221|2@0+ (1,0) [0|3] ""  IFV
 SG_ CAN_FR_DET_CONFID_ELEVATION_198 : 223|2@0+ (1,0) [0|3] ""  IFV
 SG_ CAN_FR_DET_EXISTENCE_PROB_198 : 227|4@0+ (1,0) [0|15] ""  IFV
 SG_ CAN_FR_DET_CLASS_198 : 231|4@0+ (1,0) [0|15] ""  IFV
 SG_ CAN_FR_DET_RANGE_199 : 247|14@0+ (0.015625,0) [0|255.984375] "m"  IFV
 SG_ CAN_FR_DET_SD_RANGE_199 : 249|6@0+ (0.025,0) [0|1.5] "m"  IFV
 SG_ CAN_FR_DET_RANGE_RATE_199 : 259|14@0+ (0.015625,-128) [-128|127.984375] "m/s"  IFV
 SG_ CAN_FR_DET_SD_RANGE_RATE_199 : 277|6@0+ (0.02,0) [0|1.2] "m/s"  IFV
 SG_ CAN_FR_DET_AZIMUTH_199 : 287|13@0+ (0.0007668,-3.141593) [-3.141593|3.141593] "rad"  IFV
 SG_ CAN_FR_DET_SD_AZIMUTH_199 : 290|6@0+ (0.001745329,0) [0|0.104719755] "rad"  IFV
 SG_ CAN_FR_DET_ELEVATION_199 : 300|7@0+ (0.157449,-9.99812) [-9.99812|9.997903] "deg"  IFV
 SG_ CAN_FR_DET_SD_ELEVATION_199 : 309|6@0+ (0.003490659,0) [0|0.20943951] "rad"  IFV
 SG_ CAN_FR_DET_AMPLITUDE_199 : 319|7@0+ (1,-64) [-64|63] "dBsm"  IFV
 SG_ CAN_FR_DET_VALID_FLAG_199 : 312|1@0+ (1,0) [0|1] ""  IFV
 SG_ CAN_FR_DET_SUPER_RES_199 : 320|1@0+ (1,0) [0|1] ""  IFV
 SG_ CAN_FR_DET_LOW_SNR_FLAG_199 : 321|1@0+ (1,0) [0|1] ""  IFV
 SG_ CAN_FR_DET_MIXER_BIAS_FLAG_199 : 322|1@0+ (1,0) [0|1] ""  IFV
 SG_ CAN_FR_DET_RESERVED_FLAGS_199 : 327|5@0+ (1,0) [0|31] ""  IFV
 SG_ CAN_FR_DET_SNR_199 : 335|8@0+ (0.35156,0) [0|89.6478] "dB"  IFV
 SG_ CAN_FR_DET_MULTI_TARGET_PROB_199 : 339|4@0+ (0.06667,0) [0|1] ""  IFV
 SG_ CAN_FR_DET_CONFID_AZIMUTH_199 : 341|2@0+ (1,0) [0|3] ""  IFV
 SG_ CAN_FR_DET_CONFID_ELEVATION_199 : 343|2@0+ (1,0) [0|3] ""  IFV
 SG_ CAN_FR_DET_EXISTENCE_PROB_199 : 347|4@0+ (1,0) [0|15] ""  IFV
 SG_ CAN_FR_DET_CLASS_199 : 351|4@0+ (1,0) [0|15] ""  IFV
 SG_ CAN_FR_DET_RANGE_200 : 367|14@0+ (0.015625,0) [0|255.984375] "m"  IFV
 SG_ CAN_FR_DET_SD_RANGE_200 : 369|6@0+ (0.025,0) [0|1.5] "m"  IFV
 SG_ CAN_FR_DET_RANGE_RATE_200 : 379|14@0+ (0.015625,-128) [-128|127.984375] "m/s"  IFV
 SG_ CAN_FR_DET_SD_RANGE_RATE_200 : 397|6@0+ (0.02,0) [0|1.2] "m/s"  IFV
 SG_ CAN_FR_DET_AZIMUTH_200 : 407|13@0+ (0.0007668,-3.141593) [-3.141593|3.141593] "rad"  IFV
 SG_ CAN_FR_DET_SD_AZIMUTH_200 : 410|6@0+ (0.001745329,0) [0|0.104719755] "rad"  IFV
 SG_ CAN_FR_DET_ELEVATION_200 : 420|7@0+ (0.157449,-9.99812) [-9.99812|9.997903] "deg"  IFV
 SG_ CAN_FR_DET_SD_ELEVATION_200 : 429|6@0+ (0.003490659,0) [0|0.20943951] "rad"  IFV
 SG_ CAN_FR_DET_AMPLITUDE_200 : 439|7@0+ (1,-64) [-64|63] "dBsm"  IFV
 SG_ CAN_FR_DET_VALID_FLAG_200 : 432|1@0+ (1,0) [0|1] ""  IFV
 SG_ CAN_FR_DET_SUPER_RES_200 : 440|1@0+ (1,0) [0|1] ""  IFV
 SG_ CAN_FR_DET_LOW_SNR_FLAG_200 : 441|1@0+ (1,0) [0|1] ""  IFV
 SG_ CAN_FR_DET_MIXER_BIAS_FLAG_200 : 442|1@0+ (1,0) [0|1] ""  IFV
 SG_ CAN_FR_DET_RESERVED_FLAGS_200 : 447|5@0+ (1,0) [0|31] ""  IFV
 SG_ CAN_FR_DET_SNR_200 : 455|8@0+ (0.35156,0) [0|89.6478] "dB"  IFV
 SG_ CAN_FR_DET_MULTI_TARGET_PROB_200 : 459|4@0+ (0.06667,0) [0|1] ""  IFV
 SG_ CAN_FR_DET_CONFID_AZIMUTH_200 : 461|2@0+ (1,0) [0|3] ""  IFV
 SG_ CAN_FR_DET_CONFID_ELEVATION_200 : 463|2@0+ (1,0) [0|3] ""  IFV
 SG_ CAN_FR_DET_EXISTENCE_PROB_200 : 467|4@0+ (1,0) [0|15] ""  IFV
 SG_ CAN_FR_DET_CLASS_200 : 471|4@0+ (1,0) [0|15] ""  IFV

BO_ 911 SRR_FL_Status16_SW_Version: 8 SODFL
 SG_ FL_CAN_SW_Version : 39|32@0+ (1,0) [0|4294967295] ""  IFV
 SG_ FL_CAN_PBL_Version : 15|24@0+ (1,0) [0|16777215] ""  IFV

BO_ 1167 SRR_FR_Status16_SW_Version: 8 SODFR
 SG_ FR_CAN_SW_Version : 39|32@0+ (1,0) [0|4294967295] ""  IFV
 SG_ FR_CAN_PBL_Version : 15|24@0+ (1,0) [0|16777215] ""  IFV

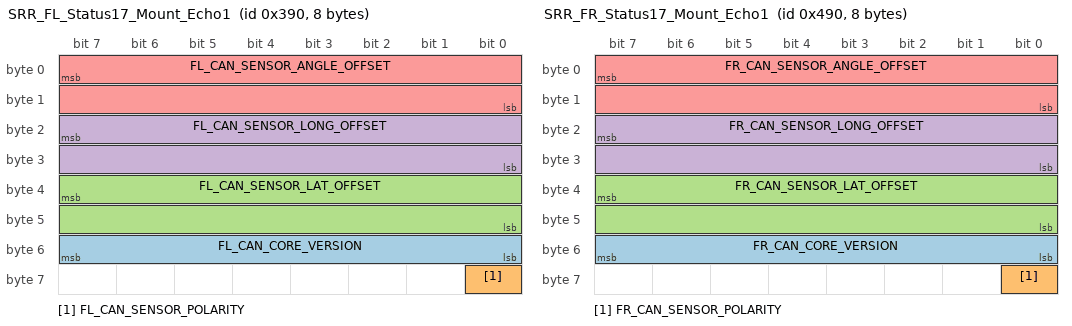
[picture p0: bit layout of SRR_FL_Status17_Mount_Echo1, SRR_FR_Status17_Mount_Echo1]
BO_ 912 SRR_FL_Status17_Mount_Echo1: 8 SODFL
 SG_ FL_CAN_CORE_VERSION : 55|8@0+ (1,0) [0|0] ""  IFV,External_Tool
 SG_ FL_CAN_SENSOR_POLARITY : 56|1@0+ (1,0) [0|1] ""  IFV,External_Tool
 SG_ FL_CAN_SENSOR_LAT_OFFSET : 39|16@0- (0.01,0) [-327.68|327.67] "cm"  IFV,External_Tool
 SG_ FL_CAN_SENSOR_LONG_OFFSET : 23|16@0- (0.02,0) [-650|0] "cm"  IFV,External_Tool
 SG_ FL_CAN_SENSOR_ANGLE_OFFSET : 7|16@0+ (0.01,-200) [-200|200] "deg"  IFV,External_Tool

BO_ 1168 SRR_FR_Status17_Mount_Echo1: 8 SODFR
 SG_ FR_CAN_CORE_VERSION : 55|8@0+ (1,0) [0|0] ""  IFV,External_Tool
 SG_ FR_CAN_SENSOR_POLARITY : 56|1@0+ (1,0) [0|1] ""  IFV,External_Tool
 SG_ FR_CAN_SENSOR_LAT_OFFSET : 39|16@0- (0.01,0) [-327.68|327.67] "cm"  IFV,External_Tool
 SG_ FR_CAN_SENSOR_LONG_OFFSET : 23|16@0- (0.02,0) [-650|0] "cm"  IFV,External_Tool
 SG_ FR_CAN_SENSOR_ANGLE_OFFSET : 7|16@0+ (0.01,-200) [-200|200] "deg"  IFV,External_Tool

BO_ 913 SRR_FL_Status18_Mount_Echo2: 8 SODFL
 SG_ FL_CAN_SENSOR_MOUNT_LOCATION : 7|8@0+ (1,0) [0|255] ""  IFV,External_Tool
 SG_ FL_CAN_SENSOR_HEIGHT : 15|32@0+ (0.01,0) [0|42949672.95] "cm"  IFV,External_Tool

BO_ 1169 SRR_FR_Status18_Mount_Echo2: 8 SODFR
 SG_ FR_CAN_SENSOR_MOUNT_LOCATION : 7|8@0+ (1,0) [0|255] ""  IFV,External_Tool
 SG_ FR_CAN_SENSOR_HEIGHT : 15|32@0+ (0.01,0) [0|42949672.95] "cm"  IFV,External_Tool

BO_ 1126 SRR_FR_Header07_Timestamps: 8 SODFR
 SG_ FR_CAN_SENSOR_TIME_STAMP_NS : 39|32@0+ (1,0) [0|4294967295] "ns"  IFV
 SG_ FR_CAN_SENSOR_TIME_STAMP_SEC : 7|32@0+ (1,0) [0|4294967295] "s"  IFV

BO_ 870 SRR_FL_Header07_Timestamps: 8 SODFL
 SG_ FL_CAN_SENSOR_TIME_STAMP_NS : 39|32@0+ (1,0) [0|4294967295] "ns"  IFV
 SG_ FL_CAN_SENSOR_TIME_STAMP_SEC : 7|32@0+ (1,0) [0|4294967295] "s"  IFV

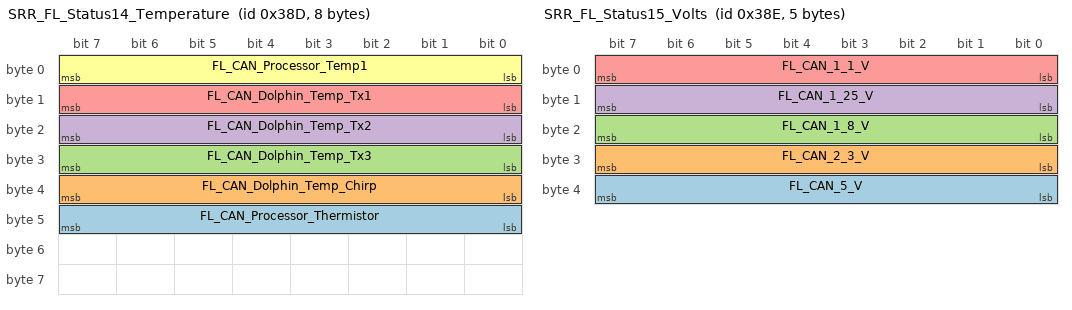
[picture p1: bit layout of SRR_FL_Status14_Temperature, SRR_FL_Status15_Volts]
BO_ 909 SRR_FL_Status14_Temperature: 8 SODFL
 SG_ FL_CAN_Processor_Thermistor : 47|8@0+ (1,-50) [-50|205] "C"  IFV
 SG_ FL_CAN_Dolphin_Temp_Chirp : 39|8@0+ (1,-50) [-50|205] "C"  IFV
 SG_ FL_CAN_Dolphin_Temp_Tx3 : 31|8@0+ (1,-50) [-50|205] "C"  IFV
 SG_ FL_CAN_Dolphin_Temp_Tx2 : 23|8@0+ (1,-50) [-50|205] "C"  IFV
 SG_ FL_CAN_Dolphin_Temp_Tx1 : 15|8@0+ (1,-50) [-50|205] "C"  IFV
 SG_ FL_CAN_Processor_Temp1 : 7|8@0+ (1,-50) [-50|205] "C"  IFV

BO_ 910 SRR_FL_Status15_Volts: 5 SODFL
 SG_ FL_CAN_5_V : 39|8@0+ (0.08,0) [0|20.4] "V"  IFV
 SG_ FL_CAN_2_3_V : 31|8@0+ (0.08,0) [0|20.4] "V"  IFV
 SG_ FL_CAN_1_8_V : 23|8@0+ (0.08,0) [0|20.4] "V"  IFV
 SG_ FL_CAN_1_25_V : 15|8@0+ (0.08,0) [0|20.4] "V"  IFV
 SG_ FL_CAN_1_1_V : 7|8@0+ (0.08,0) [0|20.4] "V"  IFV

BO_ 908 SRR_FL_Status13_BRR: 8 SODFL
 SG_ FL_CAN_BRR_STATUS : 3|2@0+ (1,0) [0|2] ""  IFV

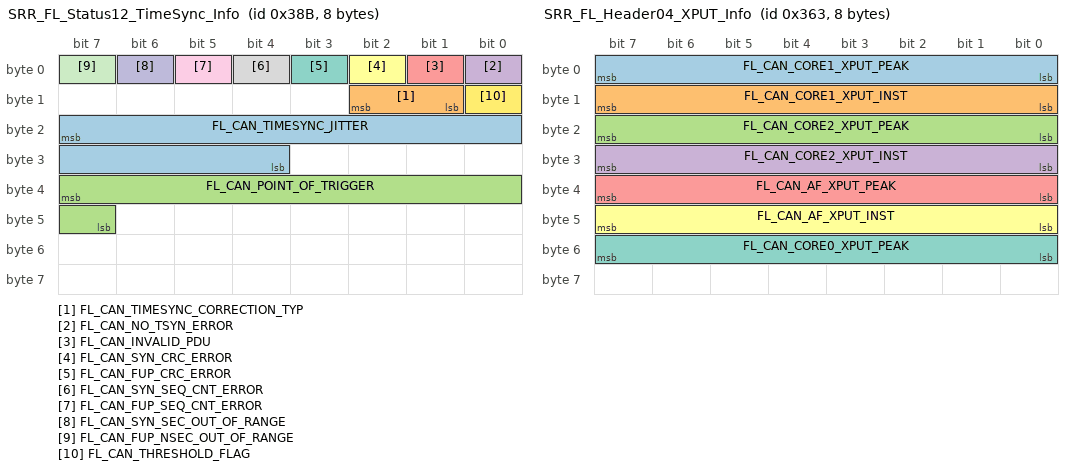
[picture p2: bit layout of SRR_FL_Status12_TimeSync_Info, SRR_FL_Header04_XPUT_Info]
BO_ 907 SRR_FL_Status12_TimeSync_Info: 8 SODFL
 SG_ FL_CAN_TIMESYNC_JITTER : 23|12@0+ (0.1,0) [0|409.5] "ms"  IFV
 SG_ FL_CAN_TIMESYNC_CORRECTION_TYP : 10|2@0+ (1,0) [0|3] ""  IFV
 SG_ FL_CAN_POINT_OF_TRIGGER : 39|9@0+ (0.1,0) [0|51.1] "ms"  IFV
 SG_ FL_CAN_NO_TSYN_ERROR : 0|1@0+ (1,0) [0|1] ""  IFV
 SG_ FL_CAN_INVALID_PDU : 1|1@0+ (1,0) [0|1] ""  IFV
 SG_ FL_CAN_SYN_CRC_ERROR : 2|1@0+ (1,0) [0|1] ""  IFV
 SG_ FL_CAN_FUP_CRC_ERROR : 3|1@0+ (1,0) [0|1] ""  IFV
 SG_ FL_CAN_SYN_SEQ_CNT_ERROR : 4|1@0+ (1,0) [0|1] ""  IFV
 SG_ FL_CAN_FUP_SEQ_CNT_ERROR : 5|1@0+ (1,0) [0|1] ""  IFV
 SG_ FL_CAN_SYN_SEC_OUT_OF_RANGE : 6|1@0+ (1,0) [0|1] ""  IFV
 SG_ FL_CAN_FUP_NSEC_OUT_OF_RANGE : 7|1@0+ (1,0) [0|1] ""  IFV
 SG_ FL_CAN_THRESHOLD_FLAG : 8|1@0+ (1,0) [0|1] ""  IFV

BO_ 867 SRR_FL_Header04_XPUT_Info: 8 SODFL
 SG_ FL_CAN_CORE1_XPUT_PEAK : 7|8@0+ (0.5,0) [0|127.5] "ms"  IFV
 SG_ FL_CAN_CORE1_XPUT_INST : 15|8@0+ (0.5,0) [0|127.5] "ms"  IFV
 SG_ FL_CAN_CORE2_XPUT_PEAK : 23|8@0+ (0.5,0) [0|127.5] "ms"  IFV
 SG_ FL_CAN_CORE2_XPUT_INST : 31|8@0+ (0.5,0) [0|127.5] "ms"  IFV
 SG_ FL_CAN_AF_XPUT_PEAK : 39|8@0+ (0.25,0) [0|50] "ms"  IFV
 SG_ FL_CAN_AF_XPUT_INST : 47|8@0+ (0.25,0) [0|50] "ms"  IFV
 SG_ FL_CAN_CORE0_XPUT_PEAK : 55|8@0+ (0.5,0) [0|127.5] "ms"  IFV

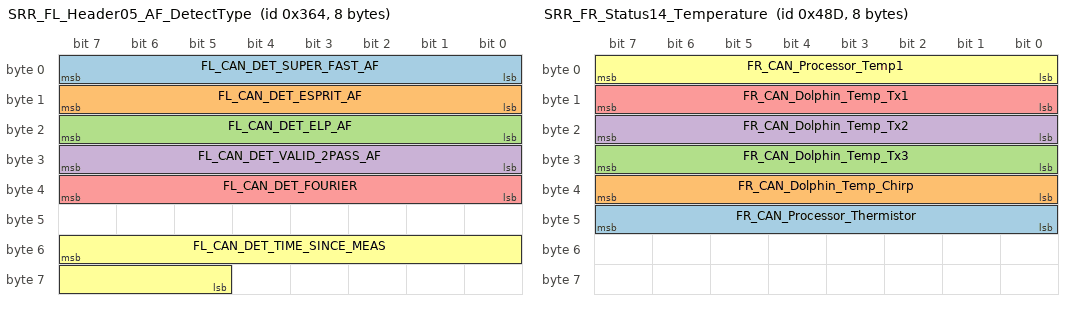
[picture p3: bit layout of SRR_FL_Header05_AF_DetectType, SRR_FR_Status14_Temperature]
BO_ 868 SRR_FL_Header05_AF_DetectType: 8 SODFL
 SG_ FL_CAN_DET_SUPER_FAST_AF : 7|8@0+ (1,0) [0|128] ""  IFV
 SG_ FL_CAN_DET_ESPRIT_AF : 15|8@0+ (1,0) [0|128] ""  IFV
 SG_ FL_CAN_DET_ELP_AF : 23|8@0+ (1,0) [0|128] ""  IFV
 SG_ FL_CAN_DET_VALID_2PASS_AF : 31|8@0+ (1,0) [0|128] ""  IFV
 SG_ FL_CAN_DET_FOURIER : 39|8@0+ (1,0) [0|128] ""  IFV
 SG_ FL_CAN_DET_TIME_SINCE_MEAS : 55|11@0+ (0.1,0) [0|204.7] "ms"  IFV

BO_ 869 SRR_FL_Header06_AF_SNR_Level: 8 SODFL
 SG_ FL_CAN_DET_SNR_LEVEL_001 : 0|1@0+ (1,0) [0|1] ""  IFV
 SG_ FL_CAN_DET_SNR_LEVEL_002 : 1|1@0+ (1,0) [0|1] ""  IFV
 SG_ FL_CAN_DET_SNR_LEVEL_003 : 2|1@0+ (1,0) [0|1] ""  IFV
 SG_ FL_CAN_DET_SNR_LEVEL_004 : 3|1@0+ (1,0) [0|1] ""  IFV
 SG_ FL_CAN_DET_SNR_LEVEL_005 : 4|1@0+ (1,0) [0|1] ""  IFV
 SG_ FL_CAN_DET_SNR_LEVEL_006 : 5|1@0+ (1,0) [0|1] ""  IFV
 SG_ FL_CAN_DET_SNR_LEVEL_007 : 6|1@0+ (1,0) [0|1] ""  IFV
 SG_ FL_CAN_DET_SNR_LEVEL_008 : 7|1@0+ (1,0) [0|1] ""  IFV
 SG_ FL_CAN_DET_SNR_LEVEL_009 : 8|1@0+ (1,0) [0|1] ""  IFV
 SG_ FL_CAN_DET_SNR_LEVEL_010 : 9|1@0+ (1,0) [0|1] ""  IFV
 SG_ FL_CAN_DET_SNR_LEVEL_011 : 10|1@0+ (1,0) [0|1] ""  IFV
 SG_ FL_CAN_DET_SNR_LEVEL_012 : 11|1@0+ (1,0) [0|1] ""  IFV
 SG_ FL_CAN_DET_SNR_LEVEL_013 : 12|1@0+ (1,0) [0|1] ""  IFV
 SG_ FL_CAN_DET_SNR_LEVEL_014 : 13|1@0+ (1,0) [0|1] ""  IFV
 SG_ FL_CAN_DET_SNR_LEVEL_015 : 14|1@0+ (1,0) [0|1] ""  IFV
 SG_ FL_CAN_DET_SNR_LEVEL_016 : 15|1@0+ (1,0) [0|1] ""  IFV
 SG_ FL_CAN_DET_SNR_LEVEL_017 : 16|1@0+ (1,0) [0|1] ""  IFV
 SG_ FL_CAN_DET_SNR_LEVEL_018 : 17|1@0+ (1,0) [0|1] ""  IFV
 SG_ FL_CAN_DET_SNR_LEVEL_019 : 18|1@0+ (1,0) [0|1] ""  IFV
 SG_ FL_CAN_DET_SNR_LEVEL_020 : 19|1@0+ (1,0) [0|1] ""  IFV
 SG_ FL_CAN_DET_SNR_LEVEL_021 : 20|1@0+ (1,0) [0|1] ""  IFV
 SG_ FL_CAN_DET_SNR_LEVEL_022 : 21|1@0+ (1,0) [0|1] ""  IFV
 SG_ FL_CAN_DET_SNR_LEVEL_023 : 22|1@0+ (1,0) [0|1] ""  IFV
 SG_ FL_CAN_DET_SNR_LEVEL_024 : 23|1@0+ (1,0) [0|1] ""  IFV
 SG_ FL_CAN_DET_SNR_LEVEL_025 : 24|1@0+ (1,0) [0|1] ""  IFV
 SG_ FL_CAN_DET_SNR_LEVEL_026 : 25|1@0+ (1,0) [0|1] ""  IFV
 SG_ FL_CAN_DET_SNR_LEVEL_027 : 26|1@0+ (1,0) [0|1] ""  IFV
 SG_ FL_CAN_DET_SNR_LEVEL_028 : 27|1@0+ (1,0) [0|1] ""  IFV
 SG_ FL_CAN_DET_SNR_LEVEL_029 : 28|1@0+ (1,0) [0|1] ""  IFV
 SG_ FL_CAN_DET_SNR_LEVEL_030 : 29|1@0+ (1,0) [0|1] ""  IFV
 SG_ FL_CAN_DET_SNR_LEVEL_031 : 30|1@0+ (1,0) [0|1] ""  IFV
 SG_ FL_CAN_DET_SNR_LEVEL_032 : 31|1@0+ (1,0) [0|1] ""  IFV
 SG_ FL_CAN_DET_SNR_LEVEL_033 : 32|1@0+ (1,0) [0|1] ""  IFV
 SG_ FL_CAN_DET_SNR_LEVEL_034 : 33|1@0+ (1,0) [0|1] ""  IFV
 SG_ FL_CAN_DET_SNR_LEVEL_035 : 34|1@0+ (1,0) [0|1] ""  IFV
 SG_ FL_CAN_DET_SNR_LEVEL_036 : 35|1@0+ (1,0) [0|1] ""  IFV
 SG_ FL_CAN_DET_SNR_LEVEL_037 : 36|1@0+ (1,0) [0|1] ""  IFV
 SG_ FL_CAN_DET_SNR_LEVEL_038 : 37|1@0+ (1,0) [0|1] ""  IFV
 SG_ FL_CAN_DET_SNR_LEVEL_039 : 38|1@0+ (1,0) [0|1] ""  IFV
 SG_ FL_CAN_DET_SNR_LEVEL_040 : 39|1@0+ (1,0) [0|1] ""  IFV
 SG_ FL_CAN_DET_SNR_LEVEL_041 : 40|1@0+ (1,0) [0|1] ""  IFV
 SG_ FL_CAN_DET_SNR_LEVEL_042 : 41|1@0+ (1,0) [0|1] ""  IFV
 SG_ FL_CAN_DET_SNR_LEVEL_043 : 42|1@0+ (1,0) [0|1] ""  IFV
 SG_ FL_CAN_DET_SNR_LEVEL_044 : 43|1@0+ (1,0) [0|1] ""  IFV
 SG_ FL_CAN_DET_SNR_LEVEL_045 : 44|1@0+ (1,0) [0|1] ""  IFV
 SG_ FL_CAN_DET_SNR_LEVEL_046 : 45|1@0+ (1,0) [0|1] ""  IFV
 SG_ FL_CAN_DET_SNR_LEVEL_047 : 46|1@0+ (1,0) [0|1] ""  IFV
 SG_ FL_CAN_DET_SNR_LEVEL_048 : 47|1@0+ (1,0) [0|1] ""  IFV
 SG_ FL_CAN_DET_SNR_LEVEL_049 : 48|1@0+ (1,0) [0|1] ""  IFV
 SG_ FL_CAN_DET_SNR_LEVEL_050 : 49|1@0+ (1,0) [0|1] ""  IFV
 SG_ FL_CAN_DET_SNR_LEVEL_051 : 50|1@0+ (1,0) [0|1] ""  IFV
 SG_ FL_CAN_DET_SNR_LEVEL_052 : 51|1@0+ (1,0) [0|1] ""  IFV
 SG_ FL_CAN_DET_SNR_LEVEL_053 : 52|1@0+ (1,0) [0|1] ""  IFV
 SG_ FL_CAN_DET_SNR_LEVEL_054 : 53|1@0+ (1,0) [0|1] ""  IFV
 SG_ FL_CAN_DET_SNR_LEVEL_055 : 54|1@0+ (1,0) [0|1] ""  IFV
 SG_ FL_CAN_DET_SNR_LEVEL_056 : 55|1@0+ (1,0) [0|1] ""  IFV
 SG_ FL_CAN_DET_SNR_LEVEL_057 : 56|1@0+ (1,0) [0|1] ""  IFV
 SG_ FL_CAN_DET_SNR_LEVEL_058 : 57|1@0+ (1,0) [0|1] ""  IFV
 SG_ FL_CAN_DET_SNR_LEVEL_059 : 58|1@0+ (1,0) [0|1] ""  IFV
 SG_ FL_CAN_DET_SNR_LEVEL_060 : 59|1@0+ (1,0) [0|1] ""  IFV
 SG_ FL_CAN_DET_SNR_LEVEL_061 : 60|1@0+ (1,0) [0|1] ""  IFV
 SG_ FL_CAN_DET_SNR_LEVEL_062 : 61|1@0+ (1,0) [0|1] ""  IFV
 SG_ FL_CAN_DET_SNR_LEVEL_063 : 62|1@0+ (1,0) [0|1] ""  IFV
 SG_ FL_CAN_DET_SNR_LEVEL_064 : 63|1@0+ (1,0) [0|1] ""  IFV

BO_ 1164 SRR_FR_Status13_BRR: 8 SODFR
 SG_ FR_CAN_BRR_STATUS : 3|2@0+ (1,0) [0|2] ""  IFV

BO_ 1165 SRR_FR_Status14_Temperature: 8 SODFR
 SG_ FR_CAN_Processor_Thermistor : 47|8@0+ (1,-50) [-50|205] "C"  IFV
 SG_ FR_CAN_Dolphin_Temp_Chirp : 39|8@0+ (1,-50) [-50|205] "C"  IFV
 SG_ FR_CAN_Dolphin_Temp_Tx3 : 31|8@0+ (1,-50) [-50|205] "C"  IFV
 SG_ FR_CAN_Dolphin_Temp_Tx2 : 23|8@0+ (1,-50) [-50|205] "C"  IFV
 SG_ FR_CAN_Dolphin_Temp_Tx1 : 15|8@0+ (1,-50) [-50|205] "C"  IFV
 SG_ FR_CAN_Processor_Temp1 : 7|8@0+ (1,-50) [-50|205] "C"  IFV

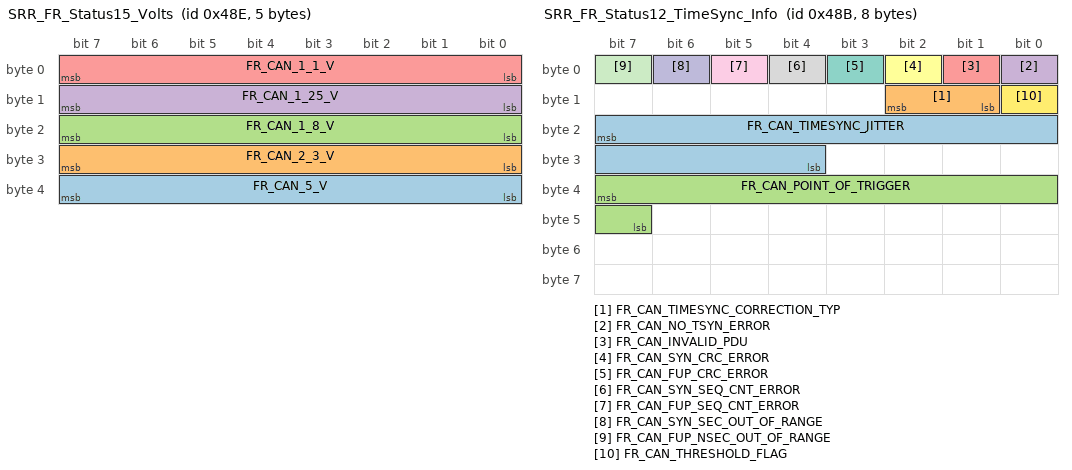
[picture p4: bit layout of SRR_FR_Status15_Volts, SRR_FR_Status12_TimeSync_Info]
BO_ 1166 SRR_FR_Status15_Volts: 5 SODFR
 SG_ FR_CAN_5_V : 39|8@0+ (0.08,0) [0|20.4] "V"  IFV
 SG_ FR_CAN_2_3_V : 31|8@0+ (0.08,0) [0|20.4] "V"  IFV
 SG_ FR_CAN_1_8_V : 23|8@0+ (0.08,0) [0|20.4] "V"  IFV
 SG_ FR_CAN_1_25_V : 15|8@0+ (0.08,0) [0|20.4] "V"  IFV
 SG_ FR_CAN_1_1_V : 7|8@0+ (0.08,0) [0|20.4] "V"  IFV

BO_ 1163 SRR_FR_Status12_TimeSync_Info: 8 SODFR
 SG_ FR_CAN_TIMESYNC_JITTER : 23|12@0+ (0.1,0) [0|409.5] "ms"  IFV
 SG_ FR_CAN_TIMESYNC_CORRECTION_TYP : 10|2@0+ (1,0) [0|3] ""  IFV
 SG_ FR_CAN_POINT_OF_TRIGGER : 39|9@0+ (0.1,0) [0|51.1] "ms"  IFV
 SG_ FR_CAN_NO_TSYN_ERROR : 0|1@0+ (1,0) [0|1] ""  IFV
 SG_ FR_CAN_INVALID_PDU : 1|1@0+ (1,0) [0|1] ""  IFV
 SG_ FR_CAN_SYN_CRC_ERROR : 2|1@0+ (1,0) [0|1] ""  IFV
 SG_ FR_CAN_FUP_CRC_ERROR : 3|1@0+ (1,0) [0|1] ""  IFV
 SG_ FR_CAN_SYN_SEQ_CNT_ERROR : 4|1@0+ (1,0) [0|1] ""  IFV
 SG_ FR_CAN_FUP_SEQ_CNT_ERROR : 5|1@0+ (1,0) [0|1] ""  IFV
 SG_ FR_CAN_SYN_SEC_OUT_OF_RANGE : 6|1@0+ (1,0) [0|1] ""  IFV
 SG_ FR_CAN_FUP_NSEC_OUT_OF_RANGE : 7|1@0+ (1,0) [0|1] ""  IFV
 SG_ FR_CAN_THRESHOLD_FLAG : 8|1@0+ (1,0) [0|1] ""  IFV

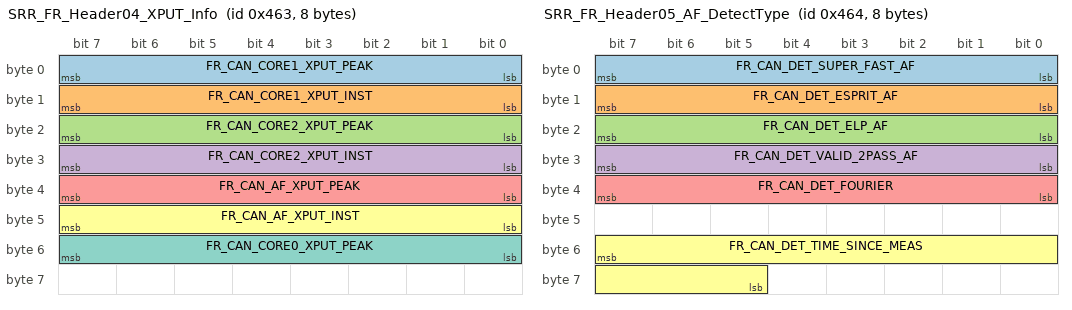
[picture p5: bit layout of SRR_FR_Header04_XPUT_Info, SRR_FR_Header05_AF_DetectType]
BO_ 1123 SRR_FR_Header04_XPUT_Info: 8 SODFR
 SG_ FR_CAN_CORE1_XPUT_PEAK : 7|8@0+ (1,0) [0|255] "ms"  IFV
 SG_ FR_CAN_CORE1_XPUT_INST : 15|8@0+ (1,0) [0|255] "ms"  IFV
 SG_ FR_CAN_CORE2_XPUT_PEAK : 23|8@0+ (1,0) [0|255] "ms"  IFV
 SG_ FR_CAN_CORE2_XPUT_INST : 31|8@0+ (1,0) [0|255] "ms"  IFV
 SG_ FR_CAN_AF_XPUT_PEAK : 39|8@0+ (1,0) [0|255] "ms"  IFV
 SG_ FR_CAN_AF_XPUT_INST : 47|8@0+ (1,0) [0|255] "ms"  IFV
 SG_ FR_CAN_CORE0_XPUT_PEAK : 55|8@0+ (1,0) [0|255] "ms"  IFV

BO_ 1124 SRR_FR_Header05_AF_DetectType: 8 SODFR
 SG_ FR_CAN_DET_SUPER_FAST_AF : 7|8@0+ (1,0) [0|128] ""  IFV
 SG_ FR_CAN_DET_ESPRIT_AF : 15|8@0+ (1,0) [0|128] ""  IFV
 SG_ FR_CAN_DET_ELP_AF : 23|8@0+ (1,0) [0|128] ""  IFV
 SG_ FR_CAN_DET_VALID_2PASS_AF : 31|8@0+ (1,0) [0|128] ""  IFV
 SG_ FR_CAN_DET_FOURIER : 39|8@0+ (1,0) [0|128] ""  IFV
 SG_ FR_CAN_DET_TIME_SINCE_MEAS : 55|11@0+ (0.1,0) [0|204.7] "ms"  IFV

BO_ 1125 SRR_FR_Header06_AF_SNR_Level: 8 SODFR
 SG_ FR_CAN_DET_SNR_LEVEL_001 : 0|1@0+ (1,0) [0|1] ""  IFV
 SG_ FR_CAN_DET_SNR_LEVEL_002 : 1|1@0+ (1,0) [0|1] ""  IFV
 SG_ FR_CAN_DET_SNR_LEVEL_003 : 2|1@0+ (1,0) [0|1] ""  IFV
 SG_ FR_CAN_DET_SNR_LEVEL_004 : 3|1@0+ (1,0) [0|1] ""  IFV
 SG_ FR_CAN_DET_SNR_LEVEL_005 : 4|1@0+ (1,0) [0|1] ""  IFV
 SG_ FR_CAN_DET_SNR_LEVEL_006 : 5|1@0+ (1,0) [0|1] ""  IFV
 SG_ FR_CAN_DET_SNR_LEVEL_007 : 6|1@0+ (1,0) [0|1] ""  IFV
 SG_ FR_CAN_DET_SNR_LEVEL_008 : 7|1@0+ (1,0) [0|1] ""  IFV
 SG_ FR_CAN_DET_SNR_LEVEL_009 : 8|1@0+ (1,0) [0|1] ""  IFV
 SG_ FR_CAN_DET_SNR_LEVEL_010 : 9|1@0+ (1,0) [0|1] ""  IFV
 SG_ FR_CAN_DET_SNR_LEVEL_011 : 10|1@0+ (1,0) [0|1] ""  IFV
 SG_ FR_CAN_DET_SNR_LEVEL_012 : 11|1@0+ (1,0) [0|1] ""  IFV
 SG_ FR_CAN_DET_SNR_LEVEL_013 : 12|1@0+ (1,0) [0|1] ""  IFV
 SG_ FR_CAN_DET_SNR_LEVEL_014 : 13|1@0+ (1,0) [0|1] ""  IFV
 SG_ FR_CAN_DET_SNR_LEVEL_015 : 14|1@0+ (1,0) [0|1] ""  IFV
 SG_ FR_CAN_DET_SNR_LEVEL_016 : 15|1@0+ (1,0) [0|1] ""  IFV
 SG_ FR_CAN_DET_SNR_LEVEL_017 : 16|1@0+ (1,0) [0|1] ""  IFV
 SG_ FR_CAN_DET_SNR_LEVEL_018 : 17|1@0+ (1,0) [0|1] ""  IFV
 SG_ FR_CAN_DET_SNR_LEVEL_019 : 18|1@0+ (1,0) [0|1] ""  IFV
 SG_ FR_CAN_DET_SNR_LEVEL_020 : 19|1@0+ (1,0) [0|1] ""  IFV
 SG_ FR_CAN_DET_SNR_LEVEL_021 : 20|1@0+ (1,0) [0|1] ""  IFV
 SG_ FR_CAN_DET_SNR_LEVEL_022 : 21|1@0+ (1,0) [0|1] ""  IFV
 SG_ FR_CAN_DET_SNR_LEVEL_023 : 22|1@0+ (1,0) [0|1] ""  IFV
 SG_ FR_CAN_DET_SNR_LEVEL_024 : 23|1@0+ (1,0) [0|1] ""  IFV
 SG_ FR_CAN_DET_SNR_LEVEL_025 : 24|1@0+ (1,0) [0|1] ""  IFV
 SG_ FR_CAN_DET_SNR_LEVEL_026 : 25|1@0+ (1,0) [0|1] ""  IFV
 SG_ FR_CAN_DET_SNR_LEVEL_027 : 26|1@0+ (1,0) [0|1] ""  IFV
 SG_ FR_CAN_DET_SNR_LEVEL_028 : 27|1@0+ (1,0) [0|1] ""  IFV
 SG_ FR_CAN_DET_SNR_LEVEL_029 : 28|1@0+ (1,0) [0|1] ""  IFV
 SG_ FR_CAN_DET_SNR_LEVEL_030 : 29|1@0+ (1,0) [0|1] ""  IFV
 SG_ FR_CAN_DET_SNR_LEVEL_031 : 30|1@0+ (1,0) [0|1] ""  IFV
 SG_ FR_CAN_DET_SNR_LEVEL_032 : 31|1@0+ (1,0) [0|1] ""  IFV
 SG_ FR_CAN_DET_SNR_LEVEL_033 : 32|1@0+ (1,0) [0|1] ""  IFV
 SG_ FR_CAN_DET_SNR_LEVEL_034 : 33|1@0+ (1,0) [0|1] ""  IFV
 SG_ FR_CAN_DET_SNR_LEVEL_035 : 34|1@0+ (1,0) [0|1] ""  IFV
 SG_ FR_CAN_DET_SNR_LEVEL_036 : 35|1@0+ (1,0) [0|1] ""  IFV
 SG_ FR_CAN_DET_SNR_LEVEL_037 : 36|1@0+ (1,0) [0|1] ""  IFV
 SG_ FR_CAN_DET_SNR_LEVEL_038 : 37|1@0+ (1,0) [0|1] ""  IFV
 SG_ FR_CAN_DET_SNR_LEVEL_039 : 38|1@0+ (1,0) [0|1] ""  IFV
 SG_ FR_CAN_DET_SNR_LEVEL_040 : 39|1@0+ (1,0) [0|1] ""  IFV
 SG_ FR_CAN_DET_SNR_LEVEL_041 : 40|1@0+ (1,0) [0|1] ""  IFV
 SG_ FR_CAN_DET_SNR_LEVEL_042 : 41|1@0+ (1,0) [0|1] ""  IFV
 SG_ FR_CAN_DET_SNR_LEVEL_043 : 42|1@0+ (1,0) [0|1] ""  IFV
 SG_ FR_CAN_DET_SNR_LEVEL_044 : 43|1@0+ (1,0) [0|1] ""  IFV
 SG_ FR_CAN_DET_SNR_LEVEL_045 : 44|1@0+ (1,0) [0|1] ""  IFV
 SG_ FR_CAN_DET_SNR_LEVEL_046 : 45|1@0+ (1,0) [0|1] ""  IFV
 SG_ FR_CAN_DET_SNR_LEVEL_047 : 46|1@0+ (1,0) [0|1] ""  IFV
 SG_ FR_CAN_DET_SNR_LEVEL_048 : 47|1@0+ (1,0) [0|1] ""  IFV
 SG_ FR_CAN_DET_SNR_LEVEL_049 : 48|1@0+ (1,0) [0|1] ""  IFV
 SG_ FR_CAN_DET_SNR_LEVEL_050 : 49|1@0+ (1,0) [0|1] ""  IFV
 SG_ FR_CAN_DET_SNR_LEVEL_051 : 50|1@0+ (1,0) [0|1] ""  IFV
 SG_ FR_CAN_DET_SNR_LEVEL_052 : 51|1@0+ (1,0) [0|1] ""  IFV
 SG_ FR_CAN_DET_SNR_LEVEL_053 : 52|1@0+ (1,0) [0|1] ""  IFV
 SG_ FR_CAN_DET_SNR_LEVEL_054 : 53|1@0+ (1,0) [0|1] ""  IFV
 SG_ FR_CAN_DET_SNR_LEVEL_055 : 54|1@0+ (1,0) [0|1] ""  IFV
 SG_ FR_CAN_DET_SNR_LEVEL_056 : 55|1@0+ (1,0) [0|1] ""  IFV
 SG_ FR_CAN_DET_SNR_LEVEL_057 : 56|1@0+ (1,0) [0|1] ""  IFV
 SG_ FR_CAN_DET_SNR_LEVEL_058 : 57|1@0+ (1,0) [0|1] ""  IFV
 SG_ FR_CAN_DET_SNR_LEVEL_059 : 58|1@0+ (1,0) [0|1] ""  IFV
 SG_ FR_CAN_DET_SNR_LEVEL_060 : 59|1@0+ (1,0) [0|1] ""  IFV
 SG_ FR_CAN_DET_SNR_LEVEL_061 : 60|1@0+ (1,0) [0|1] ""  IFV
 SG_ FR_CAN_DET_SNR_LEVEL_062 : 61|1@0+ (1,0) [0|1] ""  IFV
 SG_ FR_CAN_DET_SNR_LEVEL_063 : 62|1@0+ (1,0) [0|1] ""  IFV
 SG_ FR_CAN_DET_SNR_LEVEL_064 : 63|1@0+ (1,0) [0|1] ""  IFV

BO_ 1 SRR_FRFL_Radar_TimeSync: 8 IFV
 SG_ SRR_CAN_TSyn_UserByte m32 : 31|8@0+ (1,0) [0|0] ""  SODFL,SODFR
 SG_ SRR_CAN_TSyn_TimeDomain : 23|4@0+ (1,0) [0|15] ""  SODFL,SODFR
 SG_ SRR_CAN_TSyn_SyncTimeSec m32 : 39|32@0+ (1,0) [0|4294967295] "s"  SODFL,SODFR
 SG_ SRR_CAN_TSyn_SyncTimeNSec m40 : 39|32@0+ (1,0) [0|999999999] "ns"  SODFL,SODFR
 SG_ SRR_CAN_TSyn_SGW m40 : 26|1@0+ (1,0) [0|0] ""  SODFL,SODFR
 SG_ SRR_CAN_TSyn_SequenceCounter : 19|4@0+ (1,0) [0|15] ""  SODFL,SODFR
 SG_ SRR_CAN_TSyn_reserved m40 : 31|5@0+ (1,0) [0|0] ""  SODFL,SODFR
 SG_ SRR_CAN_TSyn_PDU M : 7|8@0+ (1,0) [0|255] ""  SODFL,SODFR
 SG_ SRR_CAN_TSyn_OVS m40 : 25|2@0+ (1,0) [0|0] ""  SODFL,SODFR
 SG_ SRR_CAN_TSyn_CRC : 15|8@0+ (1,0) [0|255] ""  SODFL,SODFR

BO_ 900 SRR_FL_Status05_Radar03: 8 SODFL
 SG_ FL_CAN_VRTCL_ALIGN_UPDATES_Nbr : 23|16@0+ (1,0) [0|65535] ""  IFV
 SG_ FL_CAN_HRZNTL_ALIGN_UPDATES_Nbr : 7|16@0+ (1,0) [0|65535] ""  IFV

BO_ 1156 SRR_FR_Status05_Radar03: 8 SODFR
 SG_ FR_CAN_VRTCL_ALIGN_UPDATES_Nbr : 23|16@0+ (1,0) [0|65535] ""  IFV
 SG_ FR_CAN_HRZNTL_ALIGN_UPDATES_Nbr : 7|16@0+ (1,0) [0|65535] ""  IFV

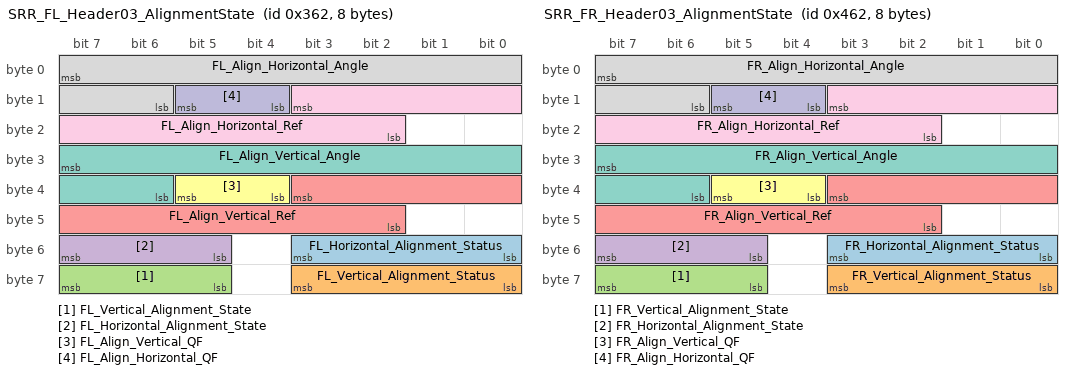
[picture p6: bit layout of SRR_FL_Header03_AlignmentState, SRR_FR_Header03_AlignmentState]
BO_ 866 SRR_FL_Header03_AlignmentState: 8 SODFL
 SG_ FL_Horizontal_Alignment_Status : 51|4@0+ (1,0) [0|15] ""  IFV,External_Tool
 SG_ FL_Vertical_Alignment_Status : 59|4@0+ (1,0) [0|15] ""  IFV,External_Tool
 SG_ FL_Vertical_Alignment_State : 63|3@0+ (1,0) [0|7] ""  IFV,External_Tool
 SG_ FL_Horizontal_Alignment_State : 55|3@0+ (1,0) [0|7] ""  IFV,External_Tool
 SG_ FL_Align_Vertical_Ref : 35|10@0+ (0.000170608920038546,-0.0872664625997165) [-0.0872664625997165|0.0872664625997165] "Rad"  IFV,External_Tool
 SG_ FL_Align_Vertical_QF : 37|2@0+ (1,0) [0|3] ""  IFV,External_Tool
 SG_ FL_Align_Vertical_Angle : 31|10@0+ (0.000170608920038546,-0.0872664625997165) [-0.0872664625997165|0.0872664625997165] "Rad"  IFV,External_Tool
 SG_ FL_Align_Horizontal_Angle : 7|10@0+ (0.000341217840077093,-0.174532925199433) [-0.174532925199433|0.174532925199433] "Rad"  IFV,External_Tool
 SG_ FL_Align_Horizontal_Ref : 11|10@0+ (0.000341217840077093,-0.174532925199433) [-0.174532925199433|0.174532925199433] "Rad"  IFV,External_Tool
 SG_ FL_Align_Horizontal_QF : 13|2@0+ (1,0) [0|3] ""  IFV,External_Tool

BO_ 1122 SRR_FR_Header03_AlignmentState: 8 SODFR
 SG_ FR_Horizontal_Alignment_Status : 51|4@0+ (1,0) [0|15] ""  IFV,External_Tool
 SG_ FR_Vertical_Alignment_Status : 59|4@0+ (1,0) [0|15] ""  IFV,External_Tool
 SG_ FR_Vertical_Alignment_State : 63|3@0+ (1,0) [0|7] ""  IFV,External_Tool
 SG_ FR_Horizontal_Alignment_State : 55|3@0+ (1,0) [0|7] ""  IFV,External_Tool
 SG_ FR_Align_Vertical_Ref : 35|10@0+ (0.000170608920038546,-0.0872664625997165) [-0.0872664625997165|0.0872664625997165] "Rad"  IFV,External_Tool
 SG_ FR_Align_Vertical_QF : 37|2@0+ (1,0) [0|3] ""  IFV,External_Tool
 SG_ FR_Align_Vertical_Angle : 31|10@0+ (0.000170608920038546,-0.0872664625997165) [-0.0872664625997165|0.0872664625997165] "Rad"  IFV,External_Tool
 SG_ FR_Align_Horizontal_Angle : 7|10@0+ (0.000341217840077093,-0.174532925199433) [-0.174532925199433|0.174532925199433] "Rad"  IFV,External_Tool
 SG_ FR_Align_Horizontal_Ref : 11|10@0+ (0.000341217840077093,-0.174532925199433) [-0.174532925199433|0.174532925199433] "Rad"  IFV,External_Tool
 SG_ FR_Align_Horizontal_QF : 13|2@0+ (1,0) [0|3] ""  IFV,External_Tool

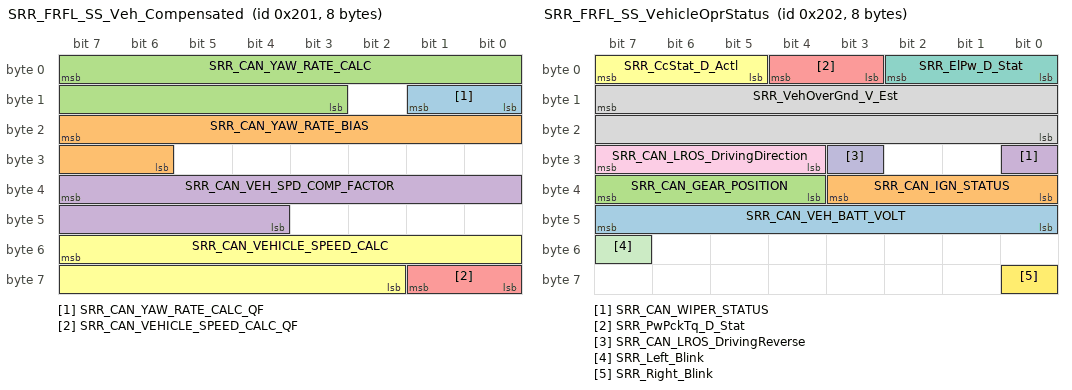
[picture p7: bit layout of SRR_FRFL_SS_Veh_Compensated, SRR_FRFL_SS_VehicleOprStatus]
BO_ 513 SRR_FRFL_SS_Veh_Compensated: 8 IFV
 SG_ SRR_CAN_YAW_RATE_CALC_QF : 9|2@0+ (1,0) [0|3] ""  SODFR,SODFL
 SG_ SRR_CAN_YAW_RATE_BIAS : 23|10@0+ (0.03125,-16) [-16|15.96875] "deg/s"  SODFR,SODFL
 SG_ SRR_CAN_YAW_RATE_CALC : 7|13@0+ (0.03125,-128) [-128|127.96875] "deg/s"  SODFR,SODFL
 SG_ SRR_CAN_VEH_SPD_COMP_FACTOR : 39|12@0+ (9.765625E-005,0.8) [0.8|1.19990234375] "NA"  SODFR,SODFL
 SG_ SRR_CAN_VEHICLE_SPEED_CALC_QF : 57|2@0+ (1,0) [0|3] ""  SODFR,SODFL
 SG_ SRR_CAN_VEHICLE_SPEED_CALC : 55|14@0+ (0.01,0) [0|163.83] "m/s"  SODFR,SODFL

BO_ 514 SRR_FRFL_SS_VehicleOprStatus: 8 IFV
 SG_ SRR_CAN_VEH_BATT_VOLT : 47|8@0+ (0.0625,0) [0|15.875] ""  SODFL,SODFR
 SG_ SRR_CAN_IGN_STATUS : 35|4@0+ (1,0) [0|15] ""  SODFL,SODFR
 SG_ SRR_CAN_GEAR_POSITION : 39|4@0+ (1,0) [0|15] ""  SODFL,SODFR
 SG_ SRR_CAN_WIPER_STATUS : 24|1@0+ (1,0) [0|1] ""  SODFL,SODFR
 SG_ SRR_PwPckTq_D_Stat : 4|2@0+ (1,0) [0|3] "SED"  SODFR,SODFL
 SG_ SRR_CcStat_D_Actl : 7|3@0+ (1,0) [0|7] "SED"  SODFR,SODFL
 SG_ SRR_ElPw_D_Stat : 2|3@0+ (1,0) [0|7] "SED"  SODFR,SODFL
 SG_ SRR_VehOverGnd_V_Est : 15|16@0+ (0.01,0) [0|655.33] "kph"  SODFR,SODFL
 SG_ SRR_CAN_LROS_DrivingDirection : 31|4@0+ (1,0) [0|3] ""  SODFR,SODFL
 SG_ SRR_CAN_LROS_DrivingReverse : 27|1@0+ (1,0) [0|1] ""  SODFR,SODFL
 SG_ SRR_Left_Blink : 55|1@0+ (1,0) [0|1] ""  SODFR,SODFL
 SG_ SRR_Right_Blink : 56|1@0+ (1,0) [0|1] ""  SODFR,SODFL

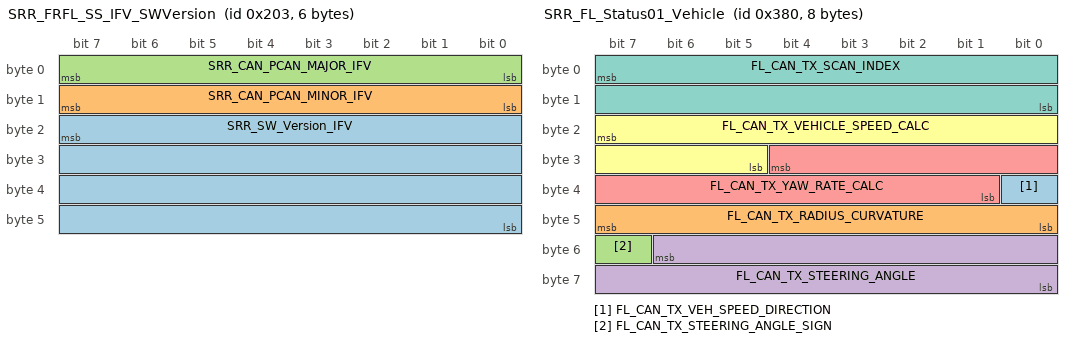
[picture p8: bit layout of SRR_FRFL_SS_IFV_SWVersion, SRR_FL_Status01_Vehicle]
BO_ 515 SRR_FRFL_SS_IFV_SWVersion: 6 IFV
 SG_ SRR_SW_Version_IFV : 23|32@0- (1,0) [0|4294967295] ""  SODFL,SODFR
 SG_ SRR_CAN_PCAN_MINOR_IFV : 15|8@0+ (1,0) [0|255] ""  SODFL,SODFR
 SG_ SRR_CAN_PCAN_MAJOR_IFV : 7|8@0+ (1,0) [0|255] ""  SODFL,SODFR

BO_ 896 SRR_FL_Status01_Vehicle: 8 SODFL
 SG_ FL_CAN_TX_VEH_SPEED_DIRECTION : 32|1@0+ (1,0) [0|0] ""  IFV
 SG_ FL_CAN_TX_RADIUS_CURVATURE : 47|8@0- (25,0) [-3200|3200] "m"  IFV
 SG_ FL_CAN_TX_STEERING_ANGLE_SIGN : 55|1@0+ (1,0) [0|1] ""  IFV
 SG_ FL_CAN_TX_STEERING_ANGLE : 54|15@0+ (1,0) [0|32767] "deg"  IFV
 SG_ FL_CAN_TX_YAW_RATE_CALC : 28|12@0- (0.0625,0) [-128|127.9375] "deg/s"  IFV
 SG_ FL_CAN_TX_VEHICLE_SPEED_CALC : 23|11@0+ (0.0625,0) [0|127.9375] "m/s"  IFV
 SG_ FL_CAN_TX_SCAN_INDEX : 7|16@0+ (1,0) [0|65535] ""  IFV

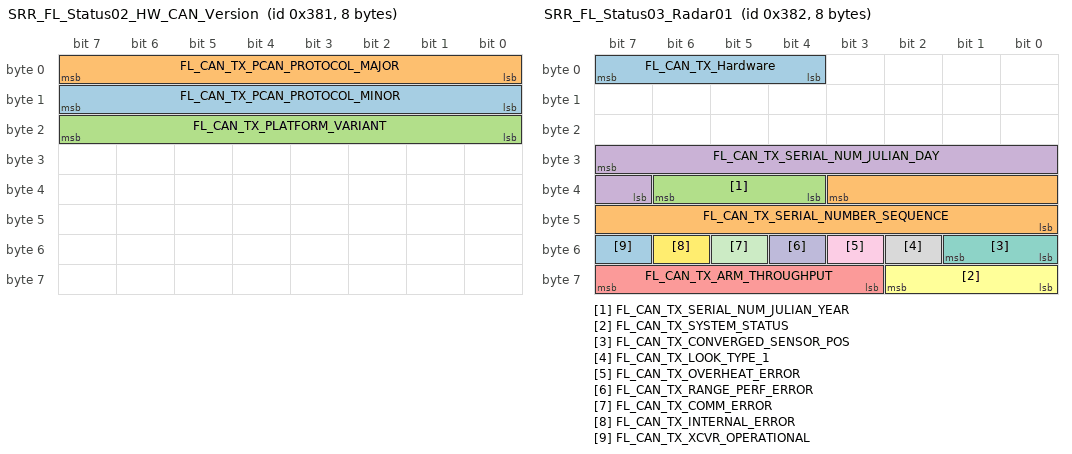
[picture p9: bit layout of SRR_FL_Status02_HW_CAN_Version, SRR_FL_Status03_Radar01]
BO_ 897 SRR_FL_Status02_HW_CAN_Version: 8 SODFL
 SG_ FL_CAN_TX_PCAN_PROTOCOL_MINOR : 15|8@0+ (1,0) [0|255] ""  IFV
 SG_ FL_CAN_TX_PCAN_PROTOCOL_MAJOR : 7|8@0+ (1,0) [0|255] ""  IFV
 SG_ FL_CAN_TX_PLATFORM_VARIANT : 23|8@0+ (1,0) [0|65535] ""  IFV

BO_ 898 SRR_FL_Status03_Radar01: 8 SODFL
 SG_ FL_CAN_TX_Hardware : 7|4@0+ (1,0) [0|0] ""  IFV
 SG_ FL_CAN_TX_SERIAL_NUMBER_SEQUENCE : 35|12@0+ (1,0) [0|0] ""  IFV
 SG_ FL_CAN_TX_SERIAL_NUM_JULIAN_YEAR : 38|3@0+ (1,2014) [0|0] ""  IFV
 SG_ FL_CAN_TX_SERIAL_NUM_JULIAN_DAY : 31|9@0+ (1,0) [0|0] ""  IFV
 SG_ FL_CAN_TX_ARM_THROUGHPUT : 63|5@0+ (3.2258,0) [0|0] ""  IFV
 SG_ FL_CAN_TX_SYSTEM_STATUS : 58|3@0+ (1,0) [0|0] ""  IFV
 SG_ FL_CAN_TX_CONVERGED_SENSOR_POS : 49|2@0+ (1,0) [0|0] ""  IFV
 SG_ FL_CAN_TX_LOOK_TYPE_1 : 50|1@0+ (1,0) [0|0] ""  IFV
 SG_ FL_CAN_TX_OVERHEAT_ERROR : 51|1@0+ (1,0) [0|0] ""  IFV
 SG_ FL_CAN_TX_RANGE_PERF_ERROR : 52|1@0+ (1,0) [0|0] ""  IFV
 SG_ FL_CAN_TX_COMM_ERROR : 53|1@0+ (1,0) [0|0] ""  IFV
 SG_ FL_CAN_TX_INTERNAL_ERROR : 54|1@0+ (1,0) [0|0] ""  IFV
 SG_ FL_CAN_TX_XCVR_OPERATIONAL : 55|1@0+ (1,0) [0|0] ""  IFV

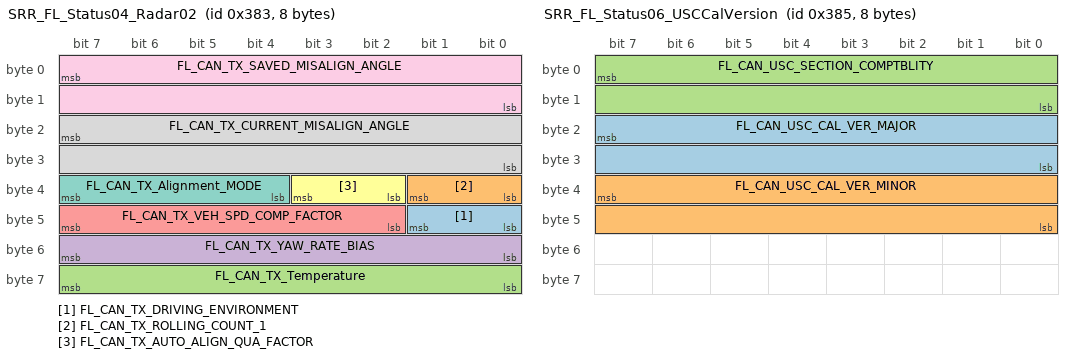
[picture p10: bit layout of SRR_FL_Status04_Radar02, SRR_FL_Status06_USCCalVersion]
BO_ 899 SRR_FL_Status04_Radar02: 8 SODFL
 SG_ FL_CAN_TX_DRIVING_ENVIRONMENT : 41|2@0+ (1,0) [0|0] ""  IFV
 SG_ FL_CAN_TX_ROLLING_COUNT_1 : 33|2@0+ (1,0) [0|0] ""  IFV
 SG_ FL_CAN_TX_Temperature : 63|8@0+ (1,-50) [-50|205] "degC"  IFV
 SG_ FL_CAN_TX_YAW_RATE_BIAS : 55|8@0- (0.125,0) [-16|15.875] ""  IFV
 SG_ FL_CAN_TX_VEH_SPD_COMP_FACTOR : 47|6@0- (0.001953125,1) [0.9375|1.060546875] ""  IFV
 SG_ FL_CAN_TX_AUTO_ALIGN_QUA_FACTOR : 35|2@0+ (1,0) [0|0] ""  IFV
 SG_ FL_CAN_TX_Alignment_MODE : 39|4@0+ (1,0) [0|0] ""  IFV
 SG_ FL_CAN_TX_CURRENT_MISALIGN_ANGLE : 23|16@0- (0.0009765625,0) [-10|10] "Deg"  IFV
 SG_ FL_CAN_TX_SAVED_MISALIGN_ANGLE : 7|16@0- (0.0009765625,0) [-10|10] "Deg"  IFV

BO_ 905 SRR_FL_Status10_Fault_Table: 8 SODFL
 SG_ FL_Supply_2_3v_Out_Of_Range_Flt : 9|1@0+ (1,0) [0|0] "" Vector__XXX
 SG_ FL_Supply_1_25v_Out_Of_Range_Flt : 10|1@0+ (1,0) [0|0] "" Vector__XXX
 SG_ FL_Software_Incompatible_Flt : 61|1@0+ (1,0) [0|0] ""  IFV
 SG_ FL_Host_Spi_Checksum_Flt : 60|1@0+ (1,0) [0|0] ""  IFV
 SG_ FL_Loss_Of_Comm_With_Dsp_Flt : 59|1@0+ (1,0) [0|0] ""  IFV
 SG_ FL_No_Communication_With_Arm_Flt : 58|1@0+ (1,0) [0|0] ""  IFV
 SG_ FL_Communication_With_Host_Flt : 57|1@0+ (1,0) [0|0] ""  IFV
 SG_ FL_Communication_With_Arm_Flt : 56|1@0+ (1,0) [0|0] ""  IFV
 SG_ FL_Dsp_Loop_Overrun_Flt_Dsp : 51|1@0+ (1,0) [0|0] ""  IFV
 SG_ FL_Tuning_Sensitivity_Flt : 50|1@0+ (1,0) [0|0] ""  IFV
 SG_ FL_Saturated_Tuning_Freq_Flt : 49|1@0+ (1,0) [0|0] ""  IFV
 SG_ FL_Local_Oscillator_Power_Flt : 48|1@0+ (1,0) [0|0] ""  IFV
 SG_ FL_Transmitter_Power_Flt : 47|1@0+ (1,0) [0|0] ""  IFV
 SG_ FL_Radar_Data_Sync_Flt : 46|1@0+ (1,0) [0|0] ""  IFV
 SG_ FL_Dsp_Spi_Hardware_Flt : 45|1@0+ (1,0) [0|0] ""  IFV
 SG_ FL_Transmitter_Device_Spi_Flt : 44|1@0+ (1,0) [0|0] ""  IFV
 SG_ FL_Receiver_Device_Spi_Flt : 43|1@0+ (1,0) [0|0] ""  IFV
 SG_ FL_Freq_Synthe_Device_Spi_Flt : 42|1@0+ (1,0) [0|0] ""  IFV
 SG_ FL_Analog_Cnvrtr_Device_Spi_Flt : 41|1@0+ (1,0) [0|0] ""  IFV
 SG_ FL_Transmitter_Id_Flt : 40|1@0+ (1,0) [0|0] ""  IFV
 SG_ FL_Ecu_Temperature_High_Flt : 39|1@0+ (1,0) [0|0] ""  IFV
 SG_ FL_Transmitter_Temp_High_Flt : 38|1@0+ (1,0) [0|0] ""  IFV
 SG_ FL_Alignment_Routine_Failed_Flt : 37|1@0+ (1,0) [0|0] ""  IFV
 SG_ FL_Unreasonable_Radar_Data : 36|1@0+ (1,0) [0|0] ""  IFV
 SG_ FL_Sensor_Blocked_Flt : 35|1@0+ (1,0) [0|0] ""  IFV
 SG_ FL_Vertical_Alignt_Out_Of_Range : 34|1@0+ (1,0) [0|0] ""  IFV
 SG_ FL_Horizontal_Align_Out_Of_Range : 33|1@0+ (1,0) [0|0] ""  IFV
 SG_ FL_Factory_Alignment_Mode : 32|1@0+ (1,0) [0|0] ""  IFV
 SG_ FL_Battery_Low_Flt : 30|1@0+ (1,0) [0|0] ""  IFV
 SG_ FL_Battery_High_Flt : 29|1@0+ (1,0) [0|0] ""  IFV
 SG_ FL_Ecu_Position_Config_Flt : 28|1@0+ (1,0) [0|0] ""  IFV
 SG_ FL_Supply_1_1v_Out_Of_Range_Flt : 27|1@0+ (1,0) [0|0] ""  IFV
 SG_ FL_Supply_1_8v_Out_Of_Range_Flt : 26|1@0+ (1,0) [0|0] ""  IFV
 SG_ FL_Thermistor_Out_Of_Range_Flt : 25|1@0+ (1,0) [0|0] ""  IFV
 SG_ FL_Supply_5v_Out_Of_Range_Flt : 24|1@0+ (1,0) [0|0] ""  IFV
 SG_ FL_Pcan_Init_Missing_Message_Flt : 22|1@0+ (1,0) [0|0] ""  IFV
 SG_ FL_Pcan_Trk_Data_Unreasnble_Flt : 21|1@0+ (1,0) [0|0] ""  IFV
 SG_ FL_Pcan_Data_Range_Check_Flt : 20|1@0+ (1,0) [0|0] ""  IFV
 SG_ FL_Pcan_Missing_Message_Flt : 19|1@0+ (1,0) [0|0] ""  IFV
 SG_ FL_Pcan_Hw_Rx_Buffer_Flt : 18|1@0+ (1,0) [0|0] ""  IFV
 SG_ FL_Pcan_Sw_Buffer_Flt : 17|1@0+ (1,0) [0|0] ""  IFV
 SG_ FL_Pcan_Bus_Off : 16|1@0+ (1,0) [0|0] ""  IFV
 SG_ FL_Host_Instrctn_Set_Check_Flt : 15|1@0+ (1,0) [0|0] ""  IFV
 SG_ FL_Host_Stack_Overflow_Flt : 14|1@0+ (1,0) [0|0] ""  IFV
 SG_ FL_Sensor_Watchdog_Flt : 13|1@0+ (1,0) [0|0] ""  IFV
 SG_ FL_Sensor_Pll_Lock_Flt : 12|1@0+ (1,0) [0|0] ""  IFV
 SG_ FL_Host_Pll_Lock_Flt : 11|1@0+ (1,0) [0|0] ""  IFV
 SG_ FL_Sensor_Ram_Memory_Test_Flt : 8|1@0+ (1,0) [0|0] ""  IFV
 SG_ FL_Host_Ram_Memory_Test_Flt : 7|1@0+ (1,0) [0|0] ""  IFV
 SG_ FL_Snsr_Custmr_Cal_Flsh_Chksum : 6|1@0+ (1,0) [0|0] ""  IFV
 SG_ FL_Dsp_Usc_Validation_Flt : 5|1@0+ (1,0) [0|0] ""  IFV
 SG_ FL_Snsr_Pgrm_Cal_Flsh_Chksum : 4|1@0+ (1,0) [0|0] ""  IFV
 SG_ FL_Sensor_App_Flash_Checksum_Flt : 3|1@0+ (1,0) [0|0] ""  IFV
 SG_ FL_Host_Kp_Alv_Flsh_Chcksm_Flt : 2|1@0+ (1,0) [0|0] ""  IFV
 SG_ FL_Host_Pgm_Cal_Flsh_Chcksum_Flt : 1|1@0+ (1,0) [0|0] ""  IFV
 SG_ FL_Host_App_Flash_Checksum_Flt : 0|1@0+ (1,0) [0|0] ""  IFV

BO_ 906 SRR_FL_Status11_Error: 8 SODFL
 SG_ FL_USC_Load_Error : 59|1@0+ (1,0) [0|0] ""  IFV
 SG_ FL_SMC_Load_Error : 58|1@0+ (1,0) [0|0] ""  IFV
 SG_ FL_TX_Temperature_Flt : 57|1@0+ (1,0) [0|0] ""  IFV
 SG_ FL_Dsp_Unit_Cal_Blk_Chcksm_Error : 56|1@0+ (1,0) [0|0] ""  IFV
 SG_ FL_Dsp_Unit_Cal_Checksum_Error : 55|1@0+ (1,0) [0|0] ""  IFV
 SG_ FL_Vertical_Misalignment_error : 54|1@0+ (1,0) [0|0] ""  IFV
 SG_ FL_RTN_SPI_Transfer_Error : 53|1@0+ (1,0) [0|0] ""  IFV
 SG_ FL_RRN_SPI_Transfer_Error : 52|1@0+ (1,0) [0|0] ""  IFV
 SG_ FL_Linearizer_SPI_Transfer_Error : 51|1@0+ (1,0) [0|0] ""  IFV
 SG_ FL_ADC_SPI_Transfer_Error : 50|1@0+ (1,0) [0|0] ""  IFV
 SG_ FL_Transmitter_ID_Error : 49|1@0+ (1,0) [0|0] ""  IFV
 SG_ FL_Dsp_Loop_Overrun_Error : 48|1@0+ (1,0) [0|0] ""  IFV
 SG_ FL_Saturated_Tuning_Freq_Error : 47|1@0+ (1,0) [0|0] ""  IFV
 SG_ FL_Radar_Data_sync_error : 46|1@0+ (1,0) [0|0] ""  IFV
 SG_ FL_Dsp_Tuning_Sensitivity_Error : 45|1@0+ (1,0) [0|0] ""  IFV
 SG_ FL_Radar_LO_Power_Error : 44|1@0+ (1,0) [0|0] ""  IFV
 SG_ FL_Radar_TX_Power_Error : 43|1@0+ (1,0) [0|0] ""  IFV
 SG_ FL_Timer_Create_Error : 6|1@0+ (1,0) [0|0] ""  IFV
 SG_ FL_Thread_Create_Error : 2|1@0+ (1,0) [0|0] ""  IFV
 SG_ FL_ARM_Calibration_Error : 9|1@0+ (1,0) [0|0] ""  IFV
 SG_ FL_SPI_FEE_Error : 14|1@0+ (1,0) [0|0] ""  IFV
 SG_ FL_SPI_Comm_Error : 13|1@0+ (1,0) [0|0] ""  IFV
 SG_ FL_Socket_Write_Error : 39|1@0+ (1,0) [0|0] ""  IFV
 SG_ FL_Socket_Read_error : 38|1@0+ (1,0) [0|0] ""  IFV
 SG_ FL_Socket_Init_Error : 37|1@0+ (1,0) [0|0] ""  IFV
 SG_ FL_Signal_Wait_Error : 4|1@0+ (1,0) [0|0] ""  IFV
 SG_ FL_Signal_Send_Error : 5|1@0+ (1,0) [0|0] ""  IFV
 SG_ FL_Signal_Create_Error : 3|1@0+ (1,0) [0|0] ""  IFV
 SG_ FL_Shared_Mem_Write_Error : 21|1@0+ (1,0) [0|0] ""  IFV
 SG_ FL_Shared_Mem_Read_Error : 20|1@0+ (1,0) [0|0] ""  IFV
 SG_ FL_Shared_Mem_Config_Error : 19|1@0+ (1,0) [0|0] ""  IFV
 SG_ FL_Share_Mem_Init_Error : 18|1@0+ (1,0) [0|0] ""  IFV
 SG_ FL_RAM_Test_Error : 1|1@0+ (1,0) [0|0] ""  IFV
 SG_ FL_Num_Errors : 63|1@0+ (1,0) [0|0] ""  IFV
 SG_ FL_MMAP_Memory_Error : 40|1@0+ (1,0) [0|0] ""  IFV
 SG_ FL_ISR_Attach_Error : 36|1@0+ (1,0) [0|0] ""  IFV
 SG_ FL_IPC_DRV_Write_Error : 29|1@0+ (1,0) [0|0] ""  IFV
 SG_ FL_IPC_DRV_Trigger_Error : 31|1@0+ (1,0) [0|0] ""  IFV
 SG_ FL_IPC_DRV_Sync_Error : 30|1@0+ (1,0) [0|0] ""  IFV
 SG_ FL_IPC_DRV_Read_Error : 28|1@0+ (1,0) [0|0] ""  IFV
 SG_ FL_IPC_DRV_Init_Error : 27|1@0+ (1,0) [0|0] ""  IFV
 SG_ FL_Interrupt_Enable_Error : 42|1@0+ (1,0) [0|0] ""  IFV
 SG_ FL_HIL_Format_Error : 41|1@0+ (1,0) [0|0] ""  IFV
 SG_ FL_Flash_Filesystem_Error : 7|1@0+ (1,0) [0|0] ""  IFV
 SG_ FL_Error_none : 0|1@0+ (1,0) [0|0] ""  IFV
 SG_ FL_Dsp_Load_Read_Error : 34|1@0+ (1,0) [0|0] ""  IFV
 SG_ FL_Dsp_Load_Open_Error : 33|1@0+ (1,0) [0|0] ""  IFV
 SG_ FL_Dsp_Load_Address_Error : 35|1@0+ (1,0) [0|0] ""  IFV
 SG_ FL_Dsp_ISP_Write_Error : 17|1@0+ (1,0) [0|0] ""  IFV
 SG_ FL_Dsp_IPC_Read_Error : 16|1@0+ (1,0) [0|0] ""  IFV
 SG_ FL_Dsp_IPC_Init : 15|1@0+ (1,0) [0|0] ""  IFV
 SG_ FL_Dsp_Init_Error : 32|1@0+ (1,0) [0|0] ""  IFV
 SG_ FL_Dsp_DRV_Start_Error : 26|1@0+ (1,0) [0|0] ""  IFV
 SG_ FL_Dsp_DRV_Load_Error : 25|1@0+ (1,0) [0|0] ""  IFV
 SG_ FL_Dsp_DRV_Init_Error : 22|1@0+ (1,0) [0|0] ""  IFV
 SG_ FL_Dsp_DRV_Init2_error : 24|1@0+ (1,0) [0|0] ""  IFV
 SG_ FL_Dsp_DRV_Init1_error : 23|1@0+ (1,0) [0|0] ""  IFV
 SG_ FL_CAN_XMT_Error : 10|1@0+ (1,0) [0|0] ""  IFV
 SG_ FL_CAN_RCV_Error : 11|1@0+ (1,0) [0|0] ""  IFV
 SG_ FL_CAN_Hardware_Error : 12|1@0+ (1,0) [0|0] ""  IFV
 SG_ FL_Always_True : 62|1@0+ (1,0) [0|0] ""  IFV

BO_ 901 SRR_FL_Status06_USCCalVersion: 8 SODFL
 SG_ FL_CAN_USC_CAL_VER_MAJOR : 23|16@0+ (1,0) [0|65535] ""  IFV
 SG_ FL_CAN_USC_CAL_VER_MINOR : 39|16@0+ (1,0) [0|65535] ""  IFV
 SG_ FL_CAN_USC_SECTION_COMPTBLITY : 7|16@0+ (1,0) [0|255] ""  IFV

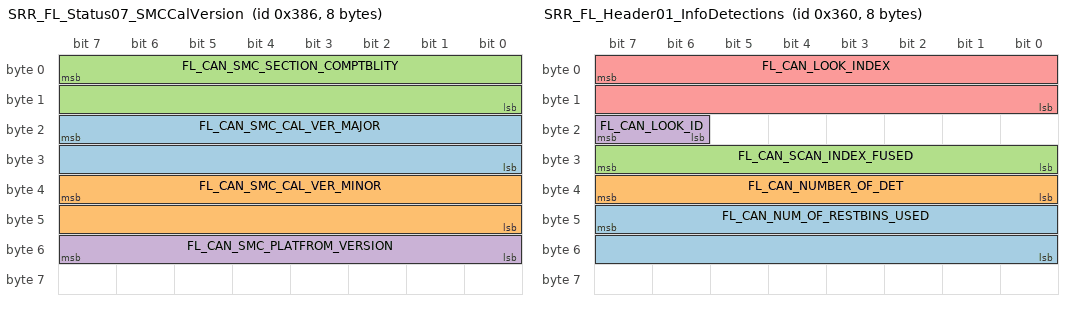
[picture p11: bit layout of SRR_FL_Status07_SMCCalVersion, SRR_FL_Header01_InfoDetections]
BO_ 902 SRR_FL_Status07_SMCCalVersion: 8 SODFL
 SG_ FL_CAN_SMC_CAL_VER_MAJOR : 23|16@0+ (1,0) [0|65535] ""  IFV
 SG_ FL_CAN_SMC_CAL_VER_MINOR : 39|16@0+ (1,0) [0|65535] ""  IFV
 SG_ FL_CAN_SMC_SECTION_COMPTBLITY : 7|16@0+ (1,0) [0|65535] ""  IFV
 SG_ FL_CAN_SMC_PLATFROM_VERSION : 55|8@0+ (1,0) [0|65535] ""  IFV

BO_ 864 SRR_FL_Header01_InfoDetections: 8 SODFL
 SG_ FL_CAN_NUM_OF_RESTBINS_USED : 47|16@0+ (1,0) [0|65535] ""  IFV
 SG_ FL_CAN_NUMBER_OF_DET : 39|8@0+ (1,0) [0|255] ""  IFV
 SG_ FL_CAN_SCAN_INDEX_FUSED : 31|8@0+ (1,0) [0|255] ""  IFV
 SG_ FL_CAN_LOOK_ID : 23|2@0+ (1,0) [0|3] ""  IFV
 SG_ FL_CAN_LOOK_INDEX : 7|16@0+ (1,0) [0|65535] ""  IFV

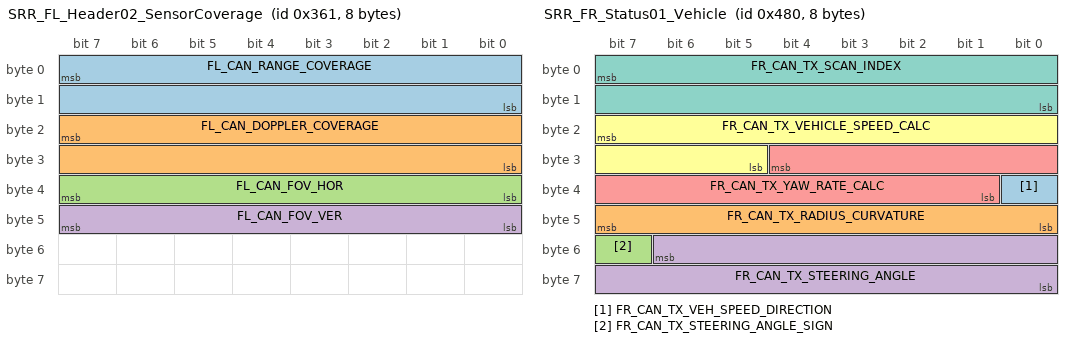
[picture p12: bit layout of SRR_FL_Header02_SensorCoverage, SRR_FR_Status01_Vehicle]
BO_ 865 SRR_FL_Header02_SensorCoverage: 8 SODFL
 SG_ FL_CAN_RANGE_COVERAGE : 7|16@0+ (0.00390625,0) [0|255.99609375] "m"  IFV
 SG_ FL_CAN_DOPPLER_COVERAGE : 23|16@0+ (0.00390625,-128) [-128|127.99609375] "m/s"  IFV
 SG_ FL_CAN_FOV_HOR : 39|8@0+ (1,0) [0|255] "deg"  IFV
 SG_ FL_CAN_FOV_VER : 47|8@0+ (1,0) [0|255] "deg"  IFV

BO_ 903 SRR_FL_Status08_Active_Flts: 8 SODFL
 SG_ FL_CAN_ACTIVE_FAULTS : 7|64@0+ (1,0) [0|1.8446744074E+019] ""  IFV

BO_ 904 SRR_FL_Status09_Latch_Flts: 8 SODFL
 SG_ FL_CAN_LATCH_FAULTS : 7|64@0+ (1,0) [0|1.84467E+019] ""  IFV

BO_ 1152 SRR_FR_Status01_Vehicle: 8 SODFR
 SG_ FR_CAN_TX_VEH_SPEED_DIRECTION : 32|1@0+ (1,0) [0|0] ""  IFV
 SG_ FR_CAN_TX_RADIUS_CURVATURE : 47|8@0- (25,0) [-3200|3200] "m"  IFV
 SG_ FR_CAN_TX_STEERING_ANGLE_SIGN : 55|1@0+ (1,0) [0|1] ""  IFV
 SG_ FR_CAN_TX_STEERING_ANGLE : 54|15@0+ (1,0) [0|32767] "deg"  IFV
 SG_ FR_CAN_TX_YAW_RATE_CALC : 28|12@0- (0.0625,0) [-128|127.9375] "deg/s"  IFV
 SG_ FR_CAN_TX_VEHICLE_SPEED_CALC : 23|11@0+ (0.0625,0) [0|127.9375] "m/s"  IFV
 SG_ FR_CAN_TX_SCAN_INDEX : 7|16@0+ (1,0) [0|65535] ""  IFV

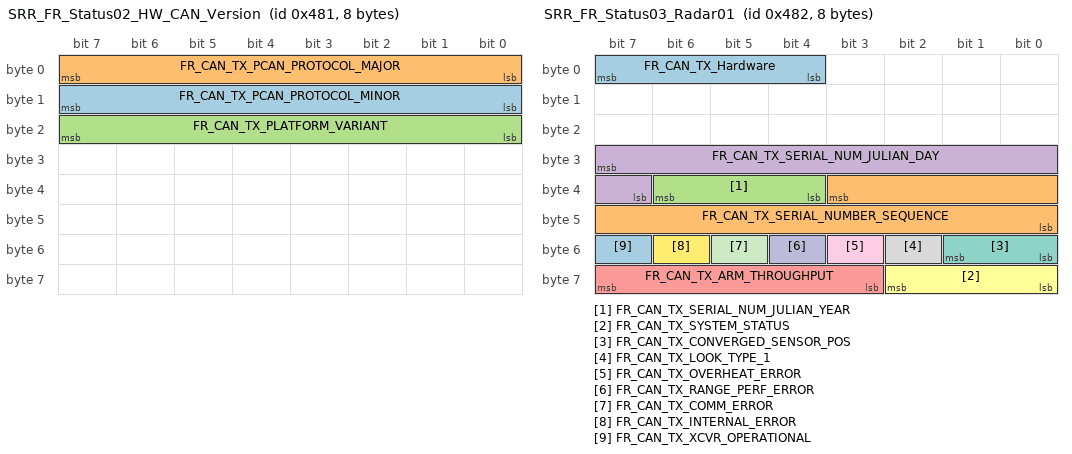
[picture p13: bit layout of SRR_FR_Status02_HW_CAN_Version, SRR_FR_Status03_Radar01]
BO_ 1153 SRR_FR_Status02_HW_CAN_Version: 8 SODFR
 SG_ FR_CAN_TX_PCAN_PROTOCOL_MINOR : 15|8@0+ (1,0) [0|255] ""  IFV
 SG_ FR_CAN_TX_PCAN_PROTOCOL_MAJOR : 7|8@0+ (1,0) [0|255] ""  IFV
 SG_ FR_CAN_TX_PLATFORM_VARIANT : 23|8@0+ (1,0) [0|65535] ""  IFV

BO_ 1170 SRR_FR_Status19_SerialNumber: 8 SODFR
 SG_ FR_CAN_SEQUENCE_NUMBER : 55|16@0+ (1,0) [0|65535] ""  IFV
 SG_ FR_CAN_SERIAL_NUMBER : 7|40@0+ (1,0) [0|1099511627800] ""  IFV

BO_ 914 SRR_FL_Status19_SerialNumber: 8 SODFL
 SG_ FL_CAN_SEQUENCE_NUMBER : 55|16@0+ (1,0) [0|65535] ""  IFV
 SG_ FL_CAN_SERIAL_NUMBER : 7|40@0+ (1,0) [0|1099511627800] ""  IFV

BO_ 1154 SRR_FR_Status03_Radar01: 8 SODFR
 SG_ FR_CAN_TX_Hardware : 7|4@0+ (1,0) [0|0] ""  IFV
 SG_ FR_CAN_TX_SERIAL_NUMBER_SEQUENCE : 35|12@0+ (1,0) [0|0] ""  IFV
 SG_ FR_CAN_TX_SERIAL_NUM_JULIAN_YEAR : 38|3@0+ (1,2014) [0|0] ""  IFV
 SG_ FR_CAN_TX_SERIAL_NUM_JULIAN_DAY : 31|9@0+ (1,0) [0|0] ""  IFV
 SG_ FR_CAN_TX_ARM_THROUGHPUT : 63|5@0+ (3.2258,0) [0|0] ""  IFV
 SG_ FR_CAN_TX_SYSTEM_STATUS : 58|3@0+ (1,0) [0|0] ""  IFV
 SG_ FR_CAN_TX_CONVERGED_SENSOR_POS : 49|2@0+ (1,0) [0|0] ""  IFV
 SG_ FR_CAN_TX_LOOK_TYPE_1 : 50|1@0+ (1,0) [0|0] ""  IFV
 SG_ FR_CAN_TX_OVERHEAT_ERROR : 51|1@0+ (1,0) [0|0] ""  IFV
 SG_ FR_CAN_TX_RANGE_PERF_ERROR : 52|1@0+ (1,0) [0|0] ""  IFV
 SG_ FR_CAN_TX_COMM_ERROR : 53|1@0+ (1,0) [0|0] ""  IFV
 SG_ FR_CAN_TX_INTERNAL_ERROR : 54|1@0+ (1,0) [0|0] ""  IFV
 SG_ FR_CAN_TX_XCVR_OPERATIONAL : 55|1@0+ (1,0) [0|0] ""  IFV

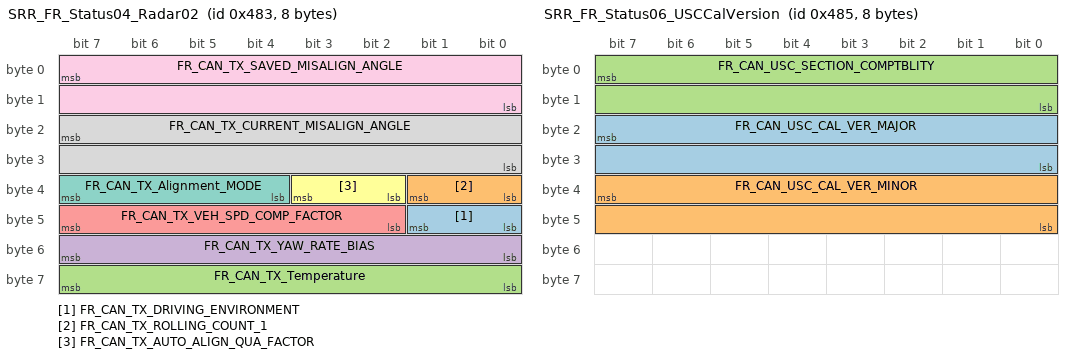
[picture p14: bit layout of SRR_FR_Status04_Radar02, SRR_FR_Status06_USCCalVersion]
BO_ 1155 SRR_FR_Status04_Radar02: 8 SODFR
 SG_ FR_CAN_TX_DRIVING_ENVIRONMENT : 41|2@0+ (1,0) [0|0] ""  IFV
 SG_ FR_CAN_TX_ROLLING_COUNT_1 : 33|2@0+ (1,0) [0|0] ""  IFV
 SG_ FR_CAN_TX_Temperature : 63|8@0+ (1,-50) [-50|205] "degC"  IFV
 SG_ FR_CAN_TX_YAW_RATE_BIAS : 55|8@0- (0.125,0) [-16|15.875] ""  IFV
 SG_ FR_CAN_TX_VEH_SPD_COMP_FACTOR : 47|6@0- (0.001953125,1) [0.9375|1.060546875] ""  IFV
 SG_ FR_CAN_TX_AUTO_ALIGN_QUA_FACTOR : 35|2@0+ (1,0) [0|0] ""  IFV
 SG_ FR_CAN_TX_Alignment_MODE : 39|4@0+ (1,0) [0|0] ""  IFV
 SG_ FR_CAN_TX_CURRENT_MISALIGN_ANGLE : 23|16@0- (0.0009765625,0) [-10|10] "Deg"  IFV
 SG_ FR_CAN_TX_SAVED_MISALIGN_ANGLE : 7|16@0- (0.0009765625,0) [-10|10] "Deg"  IFV

BO_ 1161 SRR_FR_Status10_Fault_Table: 8 SODFR
 SG_ FR_Supply_2_3v_Out_Of_Range_Flt : 9|1@0+ (1,0) [0|0] "" Vector__XXX
 SG_ FR_Supply_1_25v_Out_Of_Range_Flt : 10|1@0+ (1,0) [0|0] "" Vector__XXX
 SG_ FR_Software_Incompatible_Flt : 61|1@0+ (1,0) [0|0] ""  IFV
 SG_ FR_Host_Spi_Checksum_Flt : 60|1@0+ (1,0) [0|0] ""  IFV
 SG_ FR_Loss_Of_Comm_With_Dsp_Flt : 59|1@0+ (1,0) [0|0] ""  IFV
 SG_ FR_No_Communication_With_Arm_Flt : 58|1@0+ (1,0) [0|0] ""  IFV
 SG_ FR_Communication_With_Host_Flt : 57|1@0+ (1,0) [0|0] ""  IFV
 SG_ FR_Communication_With_Arm_Flt : 56|1@0+ (1,0) [0|0] ""  IFV
 SG_ FR_Dsp_Loop_Overrun_Flt_Dsp : 51|1@0+ (1,0) [0|0] ""  IFV
 SG_ FR_Tuning_Sensitivity_Flt : 50|1@0+ (1,0) [0|0] ""  IFV
 SG_ FR_Saturated_Tuning_Freq_Flt : 49|1@0+ (1,0) [0|0] ""  IFV
 SG_ FR_Local_Oscillator_Power_Flt : 48|1@0+ (1,0) [0|0] ""  IFV
 SG_ FR_Transmitter_Power_Flt : 47|1@0+ (1,0) [0|0] ""  IFV
 SG_ FR_Radar_Data_Sync_Flt : 46|1@0+ (1,0) [0|0] ""  IFV
 SG_ FR_Dsp_Spi_Hardware_Flt : 45|1@0+ (1,0) [0|0] ""  IFV
 SG_ FR_Transmitter_Device_Spi_Flt : 44|1@0+ (1,0) [0|0] ""  IFV
 SG_ FR_Receiver_Device_Spi_Flt : 43|1@0+ (1,0) [0|0] ""  IFV
 SG_ FR_Freq_Synthe_Device_Spi_Flt : 42|1@0+ (1,0) [0|0] ""  IFV
 SG_ FR_Analog_Cnvrtr_Device_Spi_Flt : 41|1@0+ (1,0) [0|0] ""  IFV
 SG_ FR_Transmitter_Id_Flt : 40|1@0+ (1,0) [0|0] ""  IFV
 SG_ FR_Ecu_Temperature_High_Flt : 39|1@0+ (1,0) [0|0] ""  IFV
 SG_ FR_Transmitter_Temp_High_Flt : 38|1@0+ (1,0) [0|0] ""  IFV
 SG_ FR_Alignment_Routine_Failed_Flt : 37|1@0+ (1,0) [0|0] ""  IFV
 SG_ FR_Unreasonable_Radar_Data : 36|1@0+ (1,0) [0|0] ""  IFV
 SG_ FR_Sensor_Blocked_Flt : 35|1@0+ (1,0) [0|0] ""  IFV
 SG_ FR_Vertical_Alignt_Out_Of_Range : 34|1@0+ (1,0) [0|0] ""  IFV
 SG_ FR_Horizontal_Align_Out_Of_Range : 33|1@0+ (1,0) [0|0] ""  IFV
 SG_ FR_Factory_Alignment_Mode : 32|1@0+ (1,0) [0|0] ""  IFV
 SG_ FR_Battery_Low_Flt : 30|1@0+ (1,0) [0|0] ""  IFV
 SG_ FR_Battery_High_Flt : 29|1@0+ (1,0) [0|0] ""  IFV
 SG_ FR_Ecu_Position_Config_Flt : 28|1@0+ (1,0) [0|0] ""  IFV
 SG_ FR_Supply_1_1v_Out_Of_Range_Flt : 27|1@0+ (1,0) [0|0] ""  IFV
 SG_ FR_Supply_1_8v_Out_Of_Range_Flt : 26|1@0+ (1,0) [0|0] ""  IFV
 SG_ FR_Thermistor_Out_Of_Range_Flt : 25|1@0+ (1,0) [0|0] ""  IFV
 SG_ FR_Supply_5v_Out_Of_Range_Flt : 24|1@0+ (1,0) [0|0] ""  IFV
 SG_ FR_Pcan_Init_Missing_Message_Flt : 22|1@0+ (1,0) [0|0] ""  IFV
 SG_ FR_Pcan_Trk_Data_Unreasnble_Flt : 21|1@0+ (1,0) [0|0] ""  IFV
 SG_ FR_Pcan_Data_Range_Check_Flt : 20|1@0+ (1,0) [0|0] ""  IFV
 SG_ FR_Pcan_Missing_Message_Flt : 19|1@0+ (1,0) [0|0] ""  IFV
 SG_ FR_Pcan_Hw_Rx_Buffer_Flt : 18|1@0+ (1,0) [0|0] ""  IFV
 SG_ FR_Pcan_Sw_Buffer_Flt : 17|1@0+ (1,0) [0|0] ""  IFV
 SG_ FR_Pcan_Bus_Off : 16|1@0+ (1,0) [0|0] ""  IFV
 SG_ FR_Host_Instrctn_Set_Check_Flt : 15|1@0+ (1,0) [0|0] ""  IFV
 SG_ FR_Host_Stack_Overflow_Flt : 14|1@0+ (1,0) [0|0] ""  IFV
 SG_ FR_Sensor_Watchdog_Flt : 13|1@0+ (1,0) [0|0] ""  IFV
 SG_ FR_Sensor_Pll_Lock_Flt : 12|1@0+ (1,0) [0|0] ""  IFV
 SG_ FR_Host_Pll_Lock_Flt : 11|1@0+ (1,0) [0|0] ""  IFV
 SG_ FR_Sensor_Ram_Memory_Test_Flt : 8|1@0+ (1,0) [0|0] ""  IFV
 SG_ FR_Host_Ram_Memory_Test_Flt : 7|1@0+ (1,0) [0|0] ""  IFV
 SG_ FR_Snsr_Custmr_Cal_Flsh_Chksum : 6|1@0+ (1,0) [0|0] ""  IFV
 SG_ FR_Dsp_Usc_Validation_Flt : 5|1@0+ (1,0) [0|0] ""  IFV
 SG_ FR_Snsr_Pgrm_Cal_Flsh_Chksum : 4|1@0+ (1,0) [0|0] ""  IFV
 SG_ FR_Sensor_App_Flash_Checksum_Flt : 3|1@0+ (1,0) [0|0] ""  IFV
 SG_ FR_Host_Kp_Alv_Flsh_Chcksm_Flt : 2|1@0+ (1,0) [0|0] ""  IFV
 SG_ FR_Host_Pgm_Cal_Flsh_Chcksum_Flt : 1|1@0+ (1,0) [0|0] ""  IFV
 SG_ FR_Host_App_Flash_Checksum_Flt : 0|1@0+ (1,0) [0|0] ""  IFV

BO_ 1162 SRR_FR_Status11_Error: 8 SODFR
 SG_ FR_USC_Load_Error : 59|1@0+ (1,0) [0|0] ""  IFV
 SG_ FR_SMC_Load_Error : 58|1@0+ (1,0) [0|0] ""  IFV
 SG_ FR_TX_Temperature_Flt : 57|1@0+ (1,0) [0|0] ""  IFV
 SG_ FR_Dsp_Unit_Cal_Blk_Chcksm_Error : 56|1@0+ (1,0) [0|0] ""  IFV
 SG_ FR_Dsp_Unit_Cal_Checksum_Error : 55|1@0+ (1,0) [0|0] ""  IFV
 SG_ FR_Vertical_Misalignment_error : 54|1@0+ (1,0) [0|0] ""  IFV
 SG_ FR_RTN_SPI_Transfer_Error : 53|1@0+ (1,0) [0|0] ""  IFV
 SG_ FR_RRN_SPI_Transfer_Error : 52|1@0+ (1,0) [0|0] ""  IFV
 SG_ FR_Linearizer_SPI_Transfer_Error : 51|1@0+ (1,0) [0|0] ""  IFV
 SG_ FR_ADC_SPI_Transfer_Error : 50|1@0+ (1,0) [0|0] ""  IFV
 SG_ FR_Transmitter_ID_Error : 49|1@0+ (1,0) [0|0] ""  IFV
 SG_ FR_Dsp_Loop_Overrun_Error : 48|1@0+ (1,0) [0|0] ""  IFV
 SG_ FR_Saturated_Tuning_Freq_Error : 47|1@0+ (1,0) [0|0] ""  IFV
 SG_ FR_Radar_Data_sync_error : 46|1@0+ (1,0) [0|0] ""  IFV
 SG_ FR_Dsp_Tuning_Sensitivity_Error : 45|1@0+ (1,0) [0|0] ""  IFV
 SG_ FR_Radar_LO_Power_Error : 44|1@0+ (1,0) [0|0] ""  IFV
 SG_ FR_Radar_TX_Power_Error : 43|1@0+ (1,0) [0|0] ""  IFV
 SG_ FR_Timer_Create_Error : 6|1@0+ (1,0) [0|0] ""  IFV
 SG_ FR_Thread_Create_Error : 2|1@0+ (1,0) [0|0] ""  IFV
 SG_ FR_ARM_Calibration_Error : 9|1@0+ (1,0) [0|0] ""  IFV
 SG_ FR_SPI_FEE_Error : 14|1@0+ (1,0) [0|0] ""  IFV
 SG_ FR_SPI_Comm_Error : 13|1@0+ (1,0) [0|0] ""  IFV
 SG_ FR_Socket_Write_Error : 39|1@0+ (1,0) [0|0] ""  IFV
 SG_ FR_Socket_Read_error : 38|1@0+ (1,0) [0|0] ""  IFV
 SG_ FR_Socket_Init_Error : 37|1@0+ (1,0) [0|0] ""  IFV
 SG_ FR_Signal_Wait_Error : 4|1@0+ (1,0) [0|0] ""  IFV
 SG_ FR_Signal_Send_Error : 5|1@0+ (1,0) [0|0] ""  IFV
 SG_ FR_Signal_Create_Error : 3|1@0+ (1,0) [0|0] ""  IFV
 SG_ FR_Shared_Mem_Write_Error : 21|1@0+ (1,0) [0|0] ""  IFV
 SG_ FR_Shared_Mem_Read_Error : 20|1@0+ (1,0) [0|0] ""  IFV
 SG_ FR_Shared_Mem_Config_Error : 19|1@0+ (1,0) [0|0] ""  IFV
 SG_ FR_Share_Mem_Init_Error : 18|1@0+ (1,0) [0|0] ""  IFV
 SG_ FR_RAM_Test_Error : 1|1@0+ (1,0) [0|0] ""  IFV
 SG_ FR_Num_Errors : 63|1@0+ (1,0) [0|0] ""  IFV
 SG_ FR_MMAP_Memory_Error : 40|1@0+ (1,0) [0|0] ""  IFV
 SG_ FR_ISR_Attach_Error : 36|1@0+ (1,0) [0|0] ""  IFV
 SG_ FR_IPC_DRV_Write_Error : 29|1@0+ (1,0) [0|0] ""  IFV
 SG_ FR_IPC_DRV_Trigger_Error : 31|1@0+ (1,0) [0|0] ""  IFV
 SG_ FR_IPC_DRV_Sync_Error : 30|1@0+ (1,0) [0|0] ""  IFV
 SG_ FR_IPC_DRV_Read_Error : 28|1@0+ (1,0) [0|0] ""  IFV
 SG_ FR_IPC_DRV_Init_Error : 27|1@0+ (1,0) [0|0] ""  IFV
 SG_ FR_Interrupt_Enable_Error : 42|1@0+ (1,0) [0|0] ""  IFV
 SG_ FR_HIL_Format_Error : 41|1@0+ (1,0) [0|0] ""  IFV
 SG_ FR_Flash_Filesystem_Error : 7|1@0+ (1,0) [0|0] ""  IFV
 SG_ FR_Error_none : 0|1@0+ (1,0) [0|0] ""  IFV
 SG_ FR_Dsp_Load_Read_Error : 34|1@0+ (1,0) [0|0] ""  IFV
 SG_ FR_Dsp_Load_Open_Error : 33|1@0+ (1,0) [0|0] ""  IFV
 SG_ FR_Dsp_Load_Address_Error : 35|1@0+ (1,0) [0|0] ""  IFV
 SG_ FR_Dsp_ISP_Write_Error : 17|1@0+ (1,0) [0|0] ""  IFV
 SG_ FR_Dsp_IPC_Read_Error : 16|1@0+ (1,0) [0|0] ""  IFV
 SG_ FR_Dsp_IPC_Init : 15|1@0+ (1,0) [0|0] ""  IFV
 SG_ FR_Dsp_Init_Error : 32|1@0+ (1,0) [0|0] ""  IFV
 SG_ FR_Dsp_DRV_Start_Error : 26|1@0+ (1,0) [0|0] ""  IFV
 SG_ FR_Dsp_DRV_Load_Error : 25|1@0+ (1,0) [0|0] ""  IFV
 SG_ FR_Dsp_DRV_Init_Error : 22|1@0+ (1,0) [0|0] ""  IFV
 SG_ FR_Dsp_DRV_Init2_error : 24|1@0+ (1,0) [0|0] ""  IFV
 SG_ FR_Dsp_DRV_Init1_error : 23|1@0+ (1,0) [0|0] ""  IFV
 SG_ FR_CAN_XMT_Error : 10|1@0+ (1,0) [0|0] ""  IFV
 SG_ FR_CAN_RCV_Error : 11|1@0+ (1,0) [0|0] ""  IFV
 SG_ FR_CAN_Hardware_Error : 12|1@0+ (1,0) [0|0] ""  IFV
 SG_ FR_Always_True : 62|1@0+ (1,0) [0|0] ""  IFV

BO_ 1157 SRR_FR_Status06_USCCalVersion: 8 SODFR
 SG_ FR_CAN_USC_CAL_VER_MAJOR : 23|16@0+ (1,0) [0|65535] ""  IFV
 SG_ FR_CAN_USC_CAL_VER_MINOR : 39|16@0+ (1,0) [0|65535] ""  IFV
 SG_ FR_CAN_USC_SECTION_COMPTBLITY : 7|16@0+ (1,0) [0|255] ""  IFV

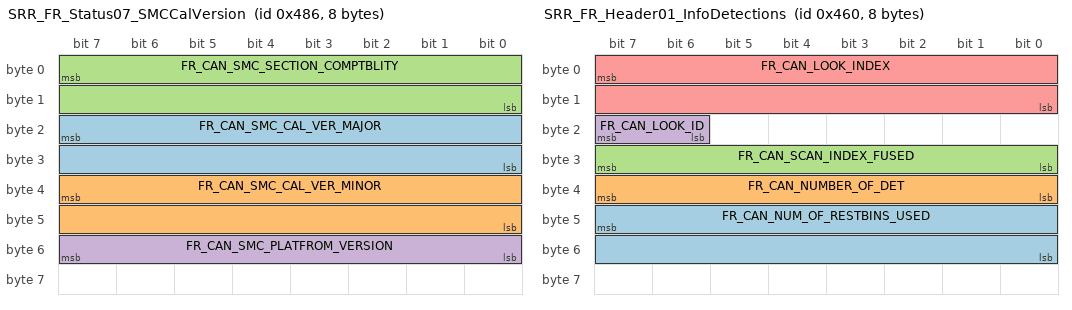
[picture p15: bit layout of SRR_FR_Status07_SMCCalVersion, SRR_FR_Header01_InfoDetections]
BO_ 1158 SRR_FR_Status07_SMCCalVersion: 8 SODFR
 SG_ FR_CAN_SMC_CAL_VER_MAJOR : 23|16@0+ (1,0) [0|65535] ""  IFV
 SG_ FR_CAN_SMC_CAL_VER_MINOR : 39|16@0+ (1,0) [0|65535] ""  IFV
 SG_ FR_CAN_SMC_SECTION_COMPTBLITY : 7|16@0+ (1,0) [0|255] ""  IFV
 SG_ FR_CAN_SMC_PLATFROM_VERSION : 55|8@0+ (1,0) [0|65535] ""  IFV

BO_ 1120 SRR_FR_Header01_InfoDetections: 8 SODFR
 SG_ FR_CAN_NUM_OF_RESTBINS_USED : 47|16@0+ (1,0) [0|65535] ""  IFV
 SG_ FR_CAN_NUMBER_OF_DET : 39|8@0+ (1,0) [0|255] ""  IFV
 SG_ FR_CAN_SCAN_INDEX_FUSED : 31|8@0+ (1,0) [0|255] ""  IFV
 SG_ FR_CAN_LOOK_ID : 23|2@0+ (1,0) [0|3] ""  IFV
 SG_ FR_CAN_LOOK_INDEX : 7|16@0+ (1,0) [0|65535] ""  IFV

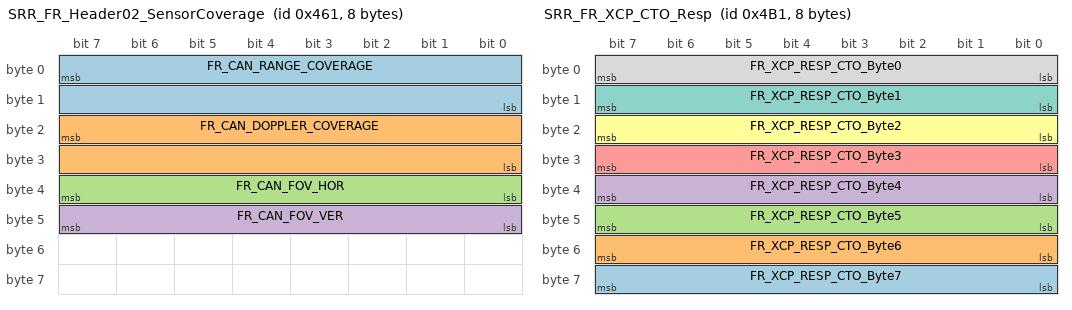
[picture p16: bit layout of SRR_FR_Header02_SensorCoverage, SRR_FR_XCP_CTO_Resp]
BO_ 1121 SRR_FR_Header02_SensorCoverage: 8 SODFR
 SG_ FR_CAN_RANGE_COVERAGE : 7|16@0+ (0.00390625,0) [0|255.99609375] "m"  IFV
 SG_ FR_CAN_DOPPLER_COVERAGE : 23|16@0+ (0.00390625,-128) [-128|127.99609375] "m/s"  IFV
 SG_ FR_CAN_FOV_HOR : 39|8@0+ (1,0) [0|255] "deg"  IFV
 SG_ FR_CAN_FOV_VER : 47|8@0+ (1,0) [0|255] "deg"  IFV

BO_ 1159 SRR_FR_Status08_Active_Flts: 8 SODFR
 SG_ FR_CAN_ACTIVE_FAULTS : 7|64@0+ (1,0) [0|1.8446744074E+019] ""  IFV

BO_ 1160 SRR_FR_Status09_Latch_Flts: 8 SODFR
 SG_ FR_CAN_LATCH_FAULTS : 7|64@0+ (1,0) [0|1.84467E+019] ""  IFV

BO_ 928 SRR_FL_Diag_Req_Phys: 8 IFV
 SG_ FL_Req_Phys : 7|64@0+ (1,0) [0|0] ""  SODFL

BO_ 1184 SRR_FR_Diag_Req_Phys: 8 IFV
 SG_ FR_Req_Phys : 7|64@0+ (1,0) [0|0] ""  SODFR

BO_ 929 SRR_FL_Diag_Resp_Phys: 8 SODFL
 SG_ FL_Resp_Phys : 7|64@0+ (1,0) [0|0] ""  IFV

BO_ 1185 SRR_FR_Diag_Resp_Phys: 8 SODFR
 SG_ FR_Resp_Phys : 7|64@0+ (1,0) [0|0] ""  IFV

BO_ 2015 SRR_FRFL_Diag_Req_Func: 8 IFV
 SG_ SRR_Diag_Req_Func : 7|8@0+ (1,0) [0|0] ""  SODFL,SODFR

BO_ 1201 SRR_FR_XCP_CTO_Resp: 8 SODFR
 SG_ FR_XCP_RESP_CTO_Byte7 : 63|8@0+ (1,0) [0|0] ""  External_Tool
 SG_ FR_XCP_RESP_CTO_Byte6 : 55|8@0+ (1,0) [0|0] ""  External_Tool
 SG_ FR_XCP_RESP_CTO_Byte5 : 47|8@0+ (1,0) [0|0] ""  External_Tool
 SG_ FR_XCP_RESP_CTO_Byte4 : 39|8@0+ (1,0) [0|0] ""  External_Tool
 SG_ FR_XCP_RESP_CTO_Byte3 : 31|8@0+ (1,0) [0|0] ""  External_Tool
 SG_ FR_XCP_RESP_CTO_Byte2 : 23|8@0+ (1,0) [0|0] ""  External_Tool
 SG_ FR_XCP_RESP_CTO_Byte1 : 15|8@0+ (1,0) [0|0] ""  External_Tool
 SG_ FR_XCP_RESP_CTO_Byte0 : 7|8@0+ (1,0) [0|0] ""  External_Tool

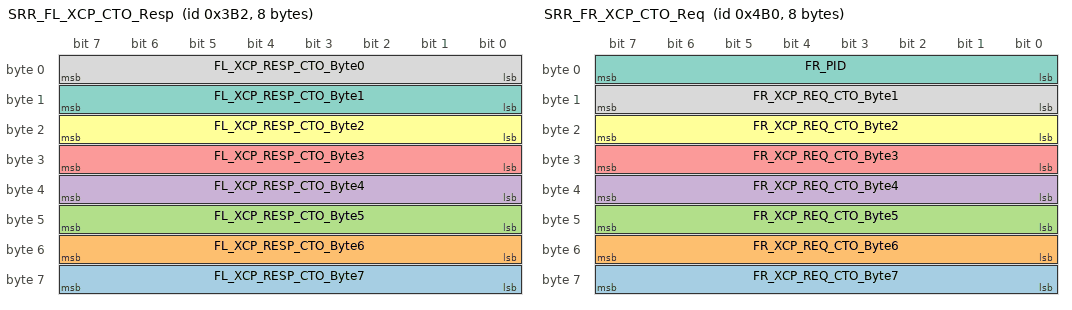
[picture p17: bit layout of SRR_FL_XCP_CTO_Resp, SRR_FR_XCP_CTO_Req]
BO_ 946 SRR_FL_XCP_CTO_Resp: 8 SODFL
 SG_ FL_XCP_RESP_CTO_Byte7 : 63|8@0+ (1,0) [0|0] ""  External_Tool
 SG_ FL_XCP_RESP_CTO_Byte6 : 55|8@0+ (1,0) [0|0] ""  External_Tool
 SG_ FL_XCP_RESP_CTO_Byte5 : 47|8@0+ (1,0) [0|0] ""  External_Tool
 SG_ FL_XCP_RESP_CTO_Byte4 : 39|8@0+ (1,0) [0|0] ""  External_Tool
 SG_ FL_XCP_RESP_CTO_Byte3 : 31|8@0+ (1,0) [0|0] ""  External_Tool
 SG_ FL_XCP_RESP_CTO_Byte2 : 23|8@0+ (1,0) [0|0] ""  External_Tool
 SG_ FL_XCP_RESP_CTO_Byte1 : 15|8@0+ (1,0) [0|0] ""  External_Tool
 SG_ FL_XCP_RESP_CTO_Byte0 : 7|8@0+ (1,0) [0|0] ""  External_Tool

BO_ 1200 SRR_FR_XCP_CTO_Req: 8 External_Tool
 SG_ FR_XCP_REQ_CTO_Byte7 : 63|8@0+ (1,0) [0|0] ""  SODFR
 SG_ FR_XCP_REQ_CTO_Byte6 : 55|8@0+ (1,0) [0|0] ""  SODFR
 SG_ FR_XCP_REQ_CTO_Byte5 : 47|8@0+ (1,0) [0|0] ""  SODFR
 SG_ FR_XCP_REQ_CTO_Byte4 : 39|8@0+ (1,0) [0|0] ""  SODFR
 SG_ FR_XCP_REQ_CTO_Byte3 : 31|8@0+ (1,0) [0|0] ""  SODFR
 SG_ FR_XCP_REQ_CTO_Byte2 : 23|8@0+ (1,0) [0|0] ""  SODFR
 SG_ FR_PID : 7|8@0+ (1,0) [0|0] ""  SODFR
 SG_ FR_XCP_REQ_CTO_Byte1 : 15|8@0+ (1,0) [0|0] ""  SODFR

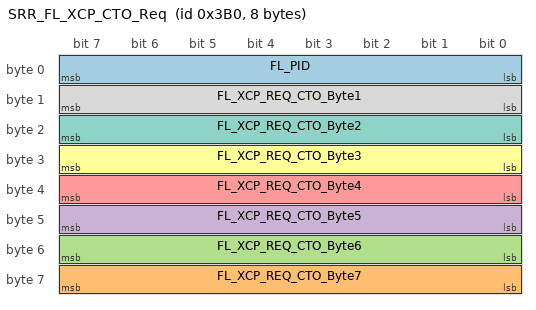
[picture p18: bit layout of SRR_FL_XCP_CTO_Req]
BO_ 944 SRR_FL_XCP_CTO_Req: 8 External_Tool
 SG_ FL_PID : 7|8@0+ (1,0) [0|0] ""  SODFL
 SG_ FL_XCP_REQ_CTO_Byte7 : 63|8@0+ (1,0) [0|0] ""  SODFL
 SG_ FL_XCP_REQ_CTO_Byte6 : 55|8@0+ (1,0) [0|0] ""  SODFL
 SG_ FL_XCP_REQ_CTO_Byte5 : 47|8@0+ (1,0) [0|0] ""  SODFL
 SG_ FL_XCP_REQ_CTO_Byte4 : 39|8@0+ (1,0) [0|0] ""  SODFL
 SG_ FL_XCP_REQ_CTO_Byte3 : 31|8@0+ (1,0) [0|0] ""  SODFL
 SG_ FL_XCP_REQ_CTO_Byte2 : 23|8@0+ (1,0) [0|0] ""  SODFL
 SG_ FL_XCP_REQ_CTO_Byte1 : 15|8@0+ (1,0) [0|0] ""  SODFL

CM_ SG_ 870 FL_CAN_SENSOR_TIME_STAMP_NS "FL sensor absolute time when the radar measurement was taken";
CM_ SG_ 908 FL_CAN_BRR_STATUS "Current status of BRR , active/inactive/fault";
CM_ SG_ 907 FL_CAN_TIMESYNC_JITTER "Delay between sync and FUL";
CM_ SG_ 907 FL_CAN_TIMESYNC_CORRECTION_TYP "Time adjustment type";
CM_ SG_ 907 FL_CAN_POINT_OF_TRIGGER "Delay betwen TymSyc message received and actual trigger";
CM_ SG_ 907 FL_CAN_THRESHOLD_FLAG "Set if time difference between SYNC and FLUP Time is greater than threshhold value";
CM_ SG_ 868 FL_CAN_DET_TIME_SINCE_MEAS "Relative time from when the radar measurement was taken until the detection data is sent on CAN";
CM_ SG_ 1164 FR_CAN_BRR_STATUS "Current status of BRR , active/inactive/fault";
CM_ SG_ 1163 FR_CAN_TIMESYNC_JITTER "Delay between sync and FUL";
CM_ SG_ 1163 FR_CAN_TIMESYNC_CORRECTION_TYP "Time adjustment type";
CM_ SG_ 1163 FR_CAN_POINT_OF_TRIGGER "Delay betwen TymSyc message received and actual trigger";
CM_ SG_ 1163 FR_CAN_THRESHOLD_FLAG "Set if time difference between SYNC and FFUP Time is greater than threshhold value";
CM_ BO_ 1 "The CAN message from the Time Master is a multiplexed message, viz. CAN-SYN and CAN-FUP";
CM_ SG_ 1 SRR_CAN_TSyn_UserByte "User specific data within the time measurement and synchronization protocol";
CM_ SG_ 1 SRR_CAN_TSyn_TimeDomain "Time Domian ID";
CM_ SG_ 1 SRR_CAN_TSyn_SyncTimeSec "TIme in Seconds";
CM_ SG_ 1 SRR_CAN_TSyn_SyncTimeNSec "Time in Nano Seconds";
CM_ SG_ 1 SRR_CAN_TSyn_SGW "Sync to Global Time or Sync to Sub Domian";
CM_ SG_ 1 SRR_CAN_TSyn_SequenceCounter "Sequence Counter (SC) of 4 bit is representing numbers from 0 to 15 per Time
Domain";
CM_ SG_ 1 SRR_CAN_TSyn_reserved "resreved for future extension";
CM_ SG_ 1 SRR_CAN_TSyn_PDU "TSyn_PDU signal value of 0x20 is  CAN-SYN. and TSyn_PDU signal value of 0x28 is CAN-FUP";
CM_ SG_ 1 SRR_CAN_TSyn_OVS "Overflow of seconds. If the value calculated for TSyn_SynTimeNSec overflows";
CM_ SG_ 1 SRR_CAN_TSyn_CRC "CRC CRC8H2F";
BA_DEF_ BO_  "VFrameFormat" ENUM  "StandardCAN","ExtendedCAN","reserved","reserved","reserved","reserved","reserved","reserved","reserved","reserved","reserved","reserved","reserved","reserved","StandardCAN_FD","ExtendedCAN_FD";
BA_DEF_ BO_  "CanTpBs" INT 0 255;
BA_DEF_ BO_  "EventRateOfChange" INT 10 10000;
BA_DEF_ SG_  "GenSigTimeoutTime_SRR01RR" INT 0 0;
BA_DEF_ SG_  "GenSigCycleTime" INT 0 0;
BA_DEF_ SG_  "GenSigVtName" STRING ;
BA_DEF_ SG_  "GenSigVtEn" STRING ;
BA_DEF_ SG_  "GenSigCmt" STRING ;
BA_DEF_ SG_  "GenSigSendType" ENUM  "Cyclic","OnWrite","vector_leerstring","OnChange","vector_leerstring","IfActive","vector_leerstring","NoSigSendType";
BA_DEF_ SG_  "GenSigStartValue" INT 0 1000000000;
BA_DEF_ BO_  "GenMsgILSupport" ENUM  "No","Yes";
BA_DEF_ BO_  "GenMsgSendType" ENUM  "FixedPeriodic","Event","EnabledPeriodic","NotUsed","NotUsed","EventPeriodic","NotUsed","NotUsed","NoMsgSendType";
BA_DEF_ BO_  "GenMsgCycleTime" INT 0 100000;
BA_DEF_ BO_  "GenMsgNrOfRepetition" INT 0 100;
BA_DEF_ BO_  "NetworkInitialization" ENUM  "No","Yes";
BA_DEF_DEF_  "VFrameFormat" "StandardCAN_FD";
BA_DEF_DEF_  "CanTpBs" 255;
BA_DEF_DEF_  "EventRateOfChange" 10000;
BA_DEF_DEF_  "GenSigTimeoutTime_SRR01RR" 0;
BA_DEF_DEF_  "GenSigCycleTime" 0;
BA_DEF_DEF_  "GenSigVtName" "";
BA_DEF_DEF_  "GenSigVtEn" "";
BA_DEF_DEF_  "GenSigCmt" "";
BA_DEF_DEF_  "GenSigSendType" "NoSigSendType";
BA_DEF_DEF_  "GenSigStartValue" 0;
BA_DEF_DEF_  "GenMsgILSupport" "Yes";
BA_DEF_DEF_  "GenMsgSendType" "NoMsgSendType";
BA_DEF_DEF_  "GenMsgCycleTime" 0;
BA_DEF_DEF_  "GenMsgNrOfRepetition" 0;
BA_DEF_DEF_  "NetworkInitialization" "Yes";
BA_ "GenMsgCycleTime" BO_ 1064 50;
BA_ "GenMsgCycleTime" BO_ 1065 50;
BA_ "GenMsgCycleTime" BO_ 1066 50;
BA_ "GenMsgCycleTime" BO_ 1067 50;
BA_ "GenMsgCycleTime" BO_ 1068 50;
BA_ "GenMsgCycleTime" BO_ 1069 50;
BA_ "GenMsgCycleTime" BO_ 1070 50;
BA_ "GenMsgCycleTime" BO_ 1071 50;
BA_ "GenMsgCycleTime" BO_ 1072 50;
BA_ "GenMsgCycleTime" BO_ 1073 50;
BA_ "GenMsgSendType" BO_ 911 0;
BA_ "GenMsgSendType" BO_ 1167 0;
BA_ "GenMsgCycleTime" BO_ 912 1000;
BA_ "GenMsgSendType" BO_ 912 0;
BA_ "GenMsgCycleTime" BO_ 1168 1000;
BA_ "GenMsgSendType" BO_ 1168 0;
BA_ "GenMsgCycleTime" BO_ 913 1000;
BA_ "GenMsgSendType" BO_ 913 0;
BA_ "GenMsgSendType" BO_ 1169 0;
BA_ "GenMsgCycleTime" BO_ 1169 1000;
BA_ "GenMsgSendType" BO_ 1126 1;
BA_ "GenMsgSendType" BO_ 870 1;
BA_ "GenMsgCycleTime" BO_ 909 1000;
BA_ "GenMsgSendType" BO_ 909 0;
BA_ "GenMsgCycleTime" BO_ 910 1000;
BA_ "GenMsgSendType" BO_ 910 0;
BA_ "GenMsgSendType" BO_ 908 0;
BA_ "GenMsgCycleTime" BO_ 908 1000;
BA_ "GenMsgSendType" BO_ 907 1;
BA_ "GenMsgSendType" BO_ 867 1;
BA_ "GenMsgSendType" BO_ 868 1;
BA_ "GenMsgSendType" BO_ 869 1;
BA_ "GenMsgSendType" BO_ 1164 0;
BA_ "GenMsgCycleTime" BO_ 1164 1000;
BA_ "GenMsgCycleTime" BO_ 1165 1000;
BA_ "GenMsgSendType" BO_ 1165 0;
BA_ "GenMsgCycleTime" BO_ 1166 1000;
BA_ "GenMsgSendType" BO_ 1166 0;
BA_ "GenMsgSendType" BO_ 1163 1;
BA_ "GenMsgSendType" BO_ 1123 1;
BA_ "GenMsgSendType" BO_ 1124 1;
BA_ "GenMsgSendType" BO_ 1125 1;
BA_ "GenMsgCycleTime" BO_ 1 1000;
BA_ "GenMsgSendType" BO_ 1 0;
BA_ "GenMsgSendType" BO_ 900 0;
BA_ "GenMsgCycleTime" BO_ 900 50;
BA_ "GenMsgSendType" BO_ 1156 0;
BA_ "GenMsgCycleTime" BO_ 1156 50;
BA_ "GenMsgSendType" BO_ 866 1;
BA_ "GenMsgSendType" BO_ 1122 1;
BA_ "GenMsgCycleTime" BO_ 513 25;
BA_ "GenMsgSendType" BO_ 513 0;
BA_ "GenMsgCycleTime" BO_ 514 25;
BA_ "GenMsgSendType" BO_ 514 0;
BA_ "GenMsgCycleTime" BO_ 515 1000;
BA_ "GenMsgSendType" BO_ 515 0;
BA_ "GenMsgSendType" BO_ 896 0;
BA_ "GenMsgCycleTime" BO_ 896 1000;
BA_ "GenMsgSendType" BO_ 897 0;
BA_ "GenMsgSendType" BO_ 898 0;
BA_ "GenMsgCycleTime" BO_ 898 50;
BA_ "GenMsgSendType" BO_ 899 0;
BA_ "GenMsgCycleTime" BO_ 899 50;
BA_ "GenMsgSendType" BO_ 905 0;
BA_ "GenMsgCycleTime" BO_ 905 1000;
BA_ "GenMsgSendType" BO_ 906 0;
BA_ "GenMsgCycleTime" BO_ 901 1000;
BA_ "GenMsgSendType" BO_ 901 0;
BA_ "GenMsgCycleTime" BO_ 902 1000;
BA_ "GenMsgSendType" BO_ 902 0;
BA_ "GenMsgSendType" BO_ 864 1;
BA_ "GenMsgSendType" BO_ 865 1;
BA_ "GenMsgSendType" BO_ 903 0;
BA_ "GenMsgCycleTime" BO_ 903 1000;
BA_ "GenMsgSendType" BO_ 904 0;
BA_ "GenMsgCycleTime" BO_ 904 1000;
BA_ "GenMsgSendType" BO_ 1152 0;
BA_ "GenMsgCycleTime" BO_ 1152 1000;
BA_ "GenMsgSendType" BO_ 1153 0;
BA_ "GenMsgSendType" BO_ 1154 0;
BA_ "GenMsgCycleTime" BO_ 1154 50;
BA_ "GenMsgSendType" BO_ 1155 0;
BA_ "GenMsgCycleTime" BO_ 1155 50;
BA_ "GenMsgSendType" BO_ 1161 0;
BA_ "GenMsgCycleTime" BO_ 1161 1000;
BA_ "GenMsgSendType" BO_ 1162 0;
BA_ "GenMsgCycleTime" BO_ 1157 1000;
BA_ "GenMsgSendType" BO_ 1157 0;
BA_ "GenMsgCycleTime" BO_ 1158 1000;
BA_ "GenMsgSendType" BO_ 1158 0;
BA_ "GenMsgSendType" BO_ 1120 1;
BA_ "GenMsgSendType" BO_ 1121 1;
BA_ "GenMsgSendType" BO_ 1159 0;
BA_ "GenMsgCycleTime" BO_ 1159 1000;
BA_ "GenMsgSendType" BO_ 1160 0;
BA_ "GenMsgCycleTime" BO_ 1160 1000;
BA_ "GenMsgSendType" BO_ 928 1;
BA_ "GenMsgSendType" BO_ 1184 1;
BA_ "GenMsgSendType" BO_ 929 1;
BA_ "GenMsgSendType" BO_ 1185 1;
BA_ "GenMsgSendType" BO_ 2015 1;
BA_ "GenMsgSendType" BO_ 1201 1;
BA_ "GenMsgSendType" BO_ 946 1;
BA_ "GenMsgSendType" BO_ 1200 1;
BA_ "GenMsgSendType" BO_ 944 1;
BA_ "GenSigSendType" SG_ 900 FL_CAN_VRTCL_ALIGN_UPDATES_Nbr 1;
BA_ "GenSigCmt" SG_ 900 FL_CAN_VRTCL_ALIGN_UPDATES_Nbr "Number of alignment updates done.";
BA_ "GenSigSendType" SG_ 900 FL_CAN_HRZNTL_ALIGN_UPDATES_Nbr 1;
BA_ "GenSigCmt" SG_ 900 FL_CAN_HRZNTL_ALIGN_UPDATES_Nbr "Number of alignment updates done.";
BA_ "GenSigSendType" SG_ 1156 FR_CAN_VRTCL_ALIGN_UPDATES_Nbr 1;
BA_ "GenSigCmt" SG_ 1156 FR_CAN_VRTCL_ALIGN_UPDATES_Nbr "Number of alignment updates done.";
BA_ "GenSigSendType" SG_ 1156 FR_CAN_HRZNTL_ALIGN_UPDATES_Nbr 1;
BA_ "GenSigCmt" SG_ 1156 FR_CAN_HRZNTL_ALIGN_UPDATES_Nbr "Number of alignment updates done.";
BA_ "GenSigStartValue" SG_ 866 FL_Align_Vertical_Ref 511.500000000001;
BA_ "GenSigStartValue" SG_ 866 FL_Align_Vertical_Angle 511.500000000001;
BA_ "GenSigStartValue" SG_ 866 FL_Align_Horizontal_Angle 511.5;
BA_ "GenSigStartValue" SG_ 866 FL_Align_Horizontal_Ref 511.5;
BA_ "GenSigStartValue" SG_ 1122 FR_Align_Vertical_Ref 511.500000000001;
BA_ "GenSigStartValue" SG_ 1122 FR_Align_Vertical_Angle 511.500000000001;
BA_ "GenSigStartValue" SG_ 1122 FR_Align_Horizontal_Angle 511.5;
BA_ "GenSigStartValue" SG_ 1122 FR_Align_Horizontal_Ref 511.5;
BA_ "GenSigCmt" SG_ 513 SRR_CAN_YAW_RATE_CALC_QF "Quality factor of the CAN_YAW_RATE_CALC signal";
BA_ "GenSigVtName" SG_ 513 SRR_CAN_YAW_RATE_CALC_QF "VtSig_CAN_YAW_RATE_CALC_QF";
BA_ "GenSigVtEn" SG_ 513 SRR_CAN_YAW_RATE_CALC_QF "TRUE";
BA_ "GenSigStartValue" SG_ 513 SRR_CAN_YAW_RATE_BIAS 512;
BA_ "GenSigCmt" SG_ 513 SRR_CAN_YAW_RATE_BIAS "Yaw rate bias";
BA_ "GenSigStartValue" SG_ 513 SRR_CAN_YAW_RATE_CALC 4096;
BA_ "GenSigCmt" SG_ 513 SRR_CAN_YAW_RATE_CALC "Contains the bias-compensated yaw rate";
BA_ "GenSigCmt" SG_ 513 SRR_CAN_VEH_SPD_COMP_FACTOR "Compensated vehicle speed factor";
BA_ "GenSigStartValue" SG_ 513 SRR_CAN_VEH_SPD_COMP_FACTOR 2048;
BA_ "GenSigCmt" SG_ 513 SRR_CAN_VEHICLE_SPEED_CALC_QF "Quality factor of the CAN_VEHICLE_SPEED_CALC";
BA_ "GenSigVtName" SG_ 513 SRR_CAN_VEHICLE_SPEED_CALC_QF "VtSig_CAN_VEHICLE_SPEED_CALC_QF";
BA_ "GenSigVtEn" SG_ 513 SRR_CAN_VEHICLE_SPEED_CALC_QF "TRUE";
BA_ "GenSigCmt" SG_ 513 SRR_CAN_VEHICLE_SPEED_CALC "Contains the compensated vehicle speed used within the FCR";
BA_ "GenSigCmt" SG_ 514 SRR_CAN_GEAR_POSITION "Gear Position";
BA_ "GenSigVtEn" SG_ 514 SRR_CAN_GEAR_POSITION "TRUE";
BA_ "GenSigVtName" SG_ 514 SRR_CAN_GEAR_POSITION "VtSig_CAN_GEAR_POSITION";
BA_ "GenSigCycleTime" SG_ 896 FL_CAN_TX_VEH_SPEED_DIRECTION 50;
BA_ "GenSigTimeoutTime_SRR01RR" SG_ 896 FL_CAN_TX_VEH_SPEED_DIRECTION 150;
BA_ "GenSigSendType" SG_ 896 FL_CAN_TX_VEH_SPEED_DIRECTION 0;
BA_ "GenSigCycleTime" SG_ 896 FL_CAN_TX_RADIUS_CURVATURE 50;
BA_ "GenSigTimeoutTime_SRR01RR" SG_ 896 FL_CAN_TX_RADIUS_CURVATURE 150;
BA_ "GenSigSendType" SG_ 896 FL_CAN_TX_RADIUS_CURVATURE 0;
BA_ "GenSigCycleTime" SG_ 896 FL_CAN_TX_STEERING_ANGLE_SIGN 50;
BA_ "GenSigTimeoutTime_SRR01RR" SG_ 896 FL_CAN_TX_STEERING_ANGLE_SIGN 150;
BA_ "GenSigSendType" SG_ 896 FL_CAN_TX_STEERING_ANGLE_SIGN 0;
BA_ "GenSigCycleTime" SG_ 896 FL_CAN_TX_STEERING_ANGLE 50;
BA_ "GenSigTimeoutTime_SRR01RR" SG_ 896 FL_CAN_TX_STEERING_ANGLE 150;
BA_ "GenSigSendType" SG_ 896 FL_CAN_TX_STEERING_ANGLE 0;
BA_ "GenSigCycleTime" SG_ 896 FL_CAN_TX_YAW_RATE_CALC 50;
BA_ "GenSigTimeoutTime_SRR01RR" SG_ 896 FL_CAN_TX_YAW_RATE_CALC 150;
BA_ "GenSigSendType" SG_ 896 FL_CAN_TX_YAW_RATE_CALC 0;
BA_ "GenSigCycleTime" SG_ 896 FL_CAN_TX_VEHICLE_SPEED_CALC 50;
BA_ "GenSigTimeoutTime_SRR01RR" SG_ 896 FL_CAN_TX_VEHICLE_SPEED_CALC 150;
BA_ "GenSigSendType" SG_ 896 FL_CAN_TX_VEHICLE_SPEED_CALC 0;
BA_ "GenSigCycleTime" SG_ 896 FL_CAN_TX_SCAN_INDEX 50;
BA_ "GenSigTimeoutTime_SRR01RR" SG_ 896 FL_CAN_TX_SCAN_INDEX 150;
BA_ "GenSigSendType" SG_ 896 FL_CAN_TX_SCAN_INDEX 0;
BA_ "GenSigCycleTime" SG_ 897 FL_CAN_TX_PCAN_PROTOCOL_MINOR 50;
BA_ "GenSigTimeoutTime_SRR01RR" SG_ 897 FL_CAN_TX_PCAN_PROTOCOL_MINOR 150;
BA_ "GenSigSendType" SG_ 897 FL_CAN_TX_PCAN_PROTOCOL_MINOR 0;
BA_ "GenSigCycleTime" SG_ 897 FL_CAN_TX_PCAN_PROTOCOL_MAJOR 50;
BA_ "GenSigTimeoutTime_SRR01RR" SG_ 897 FL_CAN_TX_PCAN_PROTOCOL_MAJOR 150;
BA_ "GenSigSendType" SG_ 897 FL_CAN_TX_PCAN_PROTOCOL_MAJOR 0;
BA_ "GenSigCycleTime" SG_ 898 FL_CAN_TX_SERIAL_NUMBER_SEQUENCE 50;
BA_ "GenSigTimeoutTime_SRR01RR" SG_ 898 FL_CAN_TX_SERIAL_NUMBER_SEQUENCE 150;
BA_ "GenSigSendType" SG_ 898 FL_CAN_TX_SERIAL_NUMBER_SEQUENCE 0;
BA_ "GenSigCycleTime" SG_ 898 FL_CAN_TX_SERIAL_NUM_JULIAN_YEAR 50;
BA_ "GenSigTimeoutTime_SRR01RR" SG_ 898 FL_CAN_TX_SERIAL_NUM_JULIAN_YEAR 150;
BA_ "GenSigSendType" SG_ 898 FL_CAN_TX_SERIAL_NUM_JULIAN_YEAR 0;
BA_ "GenSigCycleTime" SG_ 898 FL_CAN_TX_SERIAL_NUM_JULIAN_DAY 50;
BA_ "GenSigTimeoutTime_SRR01RR" SG_ 898 FL_CAN_TX_SERIAL_NUM_JULIAN_DAY 150;
BA_ "GenSigSendType" SG_ 898 FL_CAN_TX_SERIAL_NUM_JULIAN_DAY 0;
BA_ "GenSigCycleTime" SG_ 898 FL_CAN_TX_ARM_THROUGHPUT 50;
BA_ "GenSigTimeoutTime_SRR01RR" SG_ 898 FL_CAN_TX_ARM_THROUGHPUT 150;
BA_ "GenSigSendType" SG_ 898 FL_CAN_TX_ARM_THROUGHPUT 0;
BA_ "GenSigCycleTime" SG_ 898 FL_CAN_TX_SYSTEM_STATUS 50;
BA_ "GenSigTimeoutTime_SRR01RR" SG_ 898 FL_CAN_TX_SYSTEM_STATUS 150;
BA_ "GenSigSendType" SG_ 898 FL_CAN_TX_SYSTEM_STATUS 0;
BA_ "GenSigCycleTime" SG_ 898 FL_CAN_TX_CONVERGED_SENSOR_POS 50;
BA_ "GenSigTimeoutTime_SRR01RR" SG_ 898 FL_CAN_TX_CONVERGED_SENSOR_POS 150;
BA_ "GenSigSendType" SG_ 898 FL_CAN_TX_CONVERGED_SENSOR_POS 0;
BA_ "GenSigCycleTime" SG_ 898 FL_CAN_TX_LOOK_TYPE_1 50;
BA_ "GenSigTimeoutTime_SRR01RR" SG_ 898 FL_CAN_TX_LOOK_TYPE_1 150;
BA_ "GenSigSendType" SG_ 898 FL_CAN_TX_LOOK_TYPE_1 0;
BA_ "GenSigCycleTime" SG_ 898 FL_CAN_TX_OVERHEAT_ERROR 50;
BA_ "GenSigTimeoutTime_SRR01RR" SG_ 898 FL_CAN_TX_OVERHEAT_ERROR 150;
BA_ "GenSigSendType" SG_ 898 FL_CAN_TX_OVERHEAT_ERROR 0;
BA_ "GenSigCycleTime" SG_ 898 FL_CAN_TX_RANGE_PERF_ERROR 50;
BA_ "GenSigTimeoutTime_SRR01RR" SG_ 898 FL_CAN_TX_RANGE_PERF_ERROR 150;
BA_ "GenSigSendType" SG_ 898 FL_CAN_TX_RANGE_PERF_ERROR 0;
BA_ "GenSigCycleTime" SG_ 898 FL_CAN_TX_COMM_ERROR 50;
BA_ "GenSigTimeoutTime_SRR01RR" SG_ 898 FL_CAN_TX_COMM_ERROR 150;
BA_ "GenSigSendType" SG_ 898 FL_CAN_TX_COMM_ERROR 0;
BA_ "GenSigCycleTime" SG_ 898 FL_CAN_TX_INTERNAL_ERROR 50;
BA_ "GenSigTimeoutTime_SRR01RR" SG_ 898 FL_CAN_TX_INTERNAL_ERROR 150;
BA_ "GenSigSendType" SG_ 898 FL_CAN_TX_INTERNAL_ERROR 0;
BA_ "GenSigCycleTime" SG_ 898 FL_CAN_TX_XCVR_OPERATIONAL 50;
BA_ "GenSigTimeoutTime_SRR01RR" SG_ 898 FL_CAN_TX_XCVR_OPERATIONAL 150;
BA_ "GenSigSendType" SG_ 898 FL_CAN_TX_XCVR_OPERATIONAL 0;
BA_ "GenSigCycleTime" SG_ 899 FL_CAN_TX_DRIVING_ENVIRONMENT 50;
BA_ "GenSigTimeoutTime_SRR01RR" SG_ 899 FL_CAN_TX_DRIVING_ENVIRONMENT 150;
BA_ "GenSigSendType" SG_ 899 FL_CAN_TX_DRIVING_ENVIRONMENT 0;
BA_ "GenSigCycleTime" SG_ 899 FL_CAN_TX_ROLLING_COUNT_1 50;
BA_ "GenSigTimeoutTime_SRR01RR" SG_ 899 FL_CAN_TX_ROLLING_COUNT_1 150;
BA_ "GenSigSendType" SG_ 899 FL_CAN_TX_ROLLING_COUNT_1 0;
BA_ "GenSigCycleTime" SG_ 899 FL_CAN_TX_Temperature 50;
BA_ "GenSigTimeoutTime_SRR01RR" SG_ 899 FL_CAN_TX_Temperature 150;
BA_ "GenSigSendType" SG_ 899 FL_CAN_TX_Temperature 0;
BA_ "GenSigCycleTime" SG_ 899 FL_CAN_TX_YAW_RATE_BIAS 50;
BA_ "GenSigTimeoutTime_SRR01RR" SG_ 899 FL_CAN_TX_YAW_RATE_BIAS 150;
BA_ "GenSigSendType" SG_ 899 FL_CAN_TX_YAW_RATE_BIAS 0;
BA_ "GenSigCycleTime" SG_ 899 FL_CAN_TX_VEH_SPD_COMP_FACTOR 50;
BA_ "GenSigTimeoutTime_SRR01RR" SG_ 899 FL_CAN_TX_VEH_SPD_COMP_FACTOR 150;
BA_ "GenSigSendType" SG_ 899 FL_CAN_TX_VEH_SPD_COMP_FACTOR 0;
BA_ "GenSigCycleTime" SG_ 899 FL_CAN_TX_AUTO_ALIGN_QUA_FACTOR 50;
BA_ "GenSigTimeoutTime_SRR01RR" SG_ 899 FL_CAN_TX_AUTO_ALIGN_QUA_FACTOR 150;
BA_ "GenSigSendType" SG_ 899 FL_CAN_TX_AUTO_ALIGN_QUA_FACTOR 0;
BA_ "GenSigCycleTime" SG_ 899 FL_CAN_TX_Alignment_MODE 50;
BA_ "GenSigTimeoutTime_SRR01RR" SG_ 899 FL_CAN_TX_Alignment_MODE 150;
BA_ "GenSigSendType" SG_ 899 FL_CAN_TX_Alignment_MODE 0;
BA_ "GenSigCycleTime" SG_ 899 FL_CAN_TX_CURRENT_MISALIGN_ANGLE 50;
BA_ "GenSigTimeoutTime_SRR01RR" SG_ 899 FL_CAN_TX_CURRENT_MISALIGN_ANGLE 150;
BA_ "GenSigSendType" SG_ 899 FL_CAN_TX_CURRENT_MISALIGN_ANGLE 0;
BA_ "GenSigCycleTime" SG_ 899 FL_CAN_TX_SAVED_MISALIGN_ANGLE 50;
BA_ "GenSigTimeoutTime_SRR01RR" SG_ 899 FL_CAN_TX_SAVED_MISALIGN_ANGLE 150;
BA_ "GenSigSendType" SG_ 899 FL_CAN_TX_SAVED_MISALIGN_ANGLE 0;
BA_ "GenSigSendType" SG_ 905 FL_Supply_2_3v_Out_Of_Range_Flt 0;
BA_ "GenSigCycleTime" SG_ 905 FL_Supply_2_3v_Out_Of_Range_Flt 50;
BA_ "GenSigTimeoutTime_SRR01RR" SG_ 905 FL_Supply_2_3v_Out_Of_Range_Flt 150;
BA_ "GenSigSendType" SG_ 905 FL_Supply_1_25v_Out_Of_Range_Flt 0;
BA_ "GenSigCycleTime" SG_ 905 FL_Supply_1_25v_Out_Of_Range_Flt 50;
BA_ "GenSigTimeoutTime_SRR01RR" SG_ 905 FL_Supply_1_25v_Out_Of_Range_Flt 150;
BA_ "GenSigCycleTime" SG_ 905 FL_Software_Incompatible_Flt 50;
BA_ "GenSigTimeoutTime_SRR01RR" SG_ 905 FL_Software_Incompatible_Flt 150;
BA_ "GenSigSendType" SG_ 905 FL_Software_Incompatible_Flt 0;
BA_ "GenSigCycleTime" SG_ 905 FL_Host_Spi_Checksum_Flt 50;
BA_ "GenSigTimeoutTime_SRR01RR" SG_ 905 FL_Host_Spi_Checksum_Flt 150;
BA_ "GenSigSendType" SG_ 905 FL_Host_Spi_Checksum_Flt 0;
BA_ "GenSigCycleTime" SG_ 905 FL_Loss_Of_Comm_With_Dsp_Flt 50;
BA_ "GenSigTimeoutTime_SRR01RR" SG_ 905 FL_Loss_Of_Comm_With_Dsp_Flt 150;
BA_ "GenSigSendType" SG_ 905 FL_Loss_Of_Comm_With_Dsp_Flt 0;
BA_ "GenSigCycleTime" SG_ 905 FL_No_Communication_With_Arm_Flt 50;
BA_ "GenSigTimeoutTime_SRR01RR" SG_ 905 FL_No_Communication_With_Arm_Flt 150;
BA_ "GenSigSendType" SG_ 905 FL_No_Communication_With_Arm_Flt 0;
BA_ "GenSigCycleTime" SG_ 905 FL_Communication_With_Host_Flt 50;
BA_ "GenSigTimeoutTime_SRR01RR" SG_ 905 FL_Communication_With_Host_Flt 150;
BA_ "GenSigSendType" SG_ 905 FL_Communication_With_Host_Flt 0;
BA_ "GenSigCycleTime" SG_ 905 FL_Communication_With_Arm_Flt 50;
BA_ "GenSigTimeoutTime_SRR01RR" SG_ 905 FL_Communication_With_Arm_Flt 150;
BA_ "GenSigSendType" SG_ 905 FL_Communication_With_Arm_Flt 0;
BA_ "GenSigCycleTime" SG_ 905 FL_Dsp_Loop_Overrun_Flt_Dsp 50;
BA_ "GenSigTimeoutTime_SRR01RR" SG_ 905 FL_Dsp_Loop_Overrun_Flt_Dsp 150;
BA_ "GenSigSendType" SG_ 905 FL_Dsp_Loop_Overrun_Flt_Dsp 0;
BA_ "GenSigCycleTime" SG_ 905 FL_Tuning_Sensitivity_Flt 50;
BA_ "GenSigTimeoutTime_SRR01RR" SG_ 905 FL_Tuning_Sensitivity_Flt 150;
BA_ "GenSigSendType" SG_ 905 FL_Tuning_Sensitivity_Flt 0;
BA_ "GenSigCycleTime" SG_ 905 FL_Saturated_Tuning_Freq_Flt 50;
BA_ "GenSigTimeoutTime_SRR01RR" SG_ 905 FL_Saturated_Tuning_Freq_Flt 150;
BA_ "GenSigSendType" SG_ 905 FL_Saturated_Tuning_Freq_Flt 0;
BA_ "GenSigCycleTime" SG_ 905 FL_Local_Oscillator_Power_Flt 50;
BA_ "GenSigTimeoutTime_SRR01RR" SG_ 905 FL_Local_Oscillator_Power_Flt 150;
BA_ "GenSigSendType" SG_ 905 FL_Local_Oscillator_Power_Flt 0;
BA_ "GenSigCycleTime" SG_ 905 FL_Transmitter_Power_Flt 50;
BA_ "GenSigTimeoutTime_SRR01RR" SG_ 905 FL_Transmitter_Power_Flt 150;
BA_ "GenSigSendType" SG_ 905 FL_Transmitter_Power_Flt 0;
BA_ "GenSigCycleTime" SG_ 905 FL_Radar_Data_Sync_Flt 50;
BA_ "GenSigTimeoutTime_SRR01RR" SG_ 905 FL_Radar_Data_Sync_Flt 150;
BA_ "GenSigSendType" SG_ 905 FL_Radar_Data_Sync_Flt 0;
BA_ "GenSigCycleTime" SG_ 905 FL_Dsp_Spi_Hardware_Flt 50;
BA_ "GenSigTimeoutTime_SRR01RR" SG_ 905 FL_Dsp_Spi_Hardware_Flt 150;
BA_ "GenSigSendType" SG_ 905 FL_Dsp_Spi_Hardware_Flt 0;
BA_ "GenSigCycleTime" SG_ 905 FL_Transmitter_Device_Spi_Flt 50;
BA_ "GenSigTimeoutTime_SRR01RR" SG_ 905 FL_Transmitter_Device_Spi_Flt 150;
BA_ "GenSigSendType" SG_ 905 FL_Transmitter_Device_Spi_Flt 0;
BA_ "GenSigCycleTime" SG_ 905 FL_Receiver_Device_Spi_Flt 50;
BA_ "GenSigTimeoutTime_SRR01RR" SG_ 905 FL_Receiver_Device_Spi_Flt 150;
BA_ "GenSigSendType" SG_ 905 FL_Receiver_Device_Spi_Flt 0;
BA_ "GenSigCycleTime" SG_ 905 FL_Freq_Synthe_Device_Spi_Flt 50;
BA_ "GenSigTimeoutTime_SRR01RR" SG_ 905 FL_Freq_Synthe_Device_Spi_Flt 150;
BA_ "GenSigSendType" SG_ 905 FL_Freq_Synthe_Device_Spi_Flt 0;
BA_ "GenSigCycleTime" SG_ 905 FL_Analog_Cnvrtr_Device_Spi_Flt 50;
BA_ "GenSigTimeoutTime_SRR01RR" SG_ 905 FL_Analog_Cnvrtr_Device_Spi_Flt 150;
BA_ "GenSigSendType" SG_ 905 FL_Analog_Cnvrtr_Device_Spi_Flt 0;
BA_ "GenSigCycleTime" SG_ 905 FL_Transmitter_Id_Flt 50;
BA_ "GenSigTimeoutTime_SRR01RR" SG_ 905 FL_Transmitter_Id_Flt 150;
BA_ "GenSigSendType" SG_ 905 FL_Transmitter_Id_Flt 0;
BA_ "GenSigCycleTime" SG_ 905 FL_Ecu_Temperature_High_Flt 50;
BA_ "GenSigTimeoutTime_SRR01RR" SG_ 905 FL_Ecu_Temperature_High_Flt 150;
BA_ "GenSigSendType" SG_ 905 FL_Ecu_Temperature_High_Flt 0;
BA_ "GenSigCycleTime" SG_ 905 FL_Transmitter_Temp_High_Flt 50;
BA_ "GenSigTimeoutTime_SRR01RR" SG_ 905 FL_Transmitter_Temp_High_Flt 150;
BA_ "GenSigSendType" SG_ 905 FL_Transmitter_Temp_High_Flt 0;
BA_ "GenSigCycleTime" SG_ 905 FL_Alignment_Routine_Failed_Flt 50;
BA_ "GenSigTimeoutTime_SRR01RR" SG_ 905 FL_Alignment_Routine_Failed_Flt 150;
BA_ "GenSigSendType" SG_ 905 FL_Alignment_Routine_Failed_Flt 0;
BA_ "GenSigCycleTime" SG_ 905 FL_Unreasonable_Radar_Data 50;
BA_ "GenSigTimeoutTime_SRR01RR" SG_ 905 FL_Unreasonable_Radar_Data 150;
BA_ "GenSigSendType" SG_ 905 FL_Unreasonable_Radar_Data 0;
BA_ "GenSigCycleTime" SG_ 905 FL_Sensor_Blocked_Flt 50;
BA_ "GenSigTimeoutTime_SRR01RR" SG_ 905 FL_Sensor_Blocked_Flt 150;
BA_ "GenSigSendType" SG_ 905 FL_Sensor_Blocked_Flt 0;
BA_ "GenSigCycleTime" SG_ 905 FL_Vertical_Alignt_Out_Of_Range 50;
BA_ "GenSigTimeoutTime_SRR01RR" SG_ 905 FL_Vertical_Alignt_Out_Of_Range 150;
BA_ "GenSigSendType" SG_ 905 FL_Vertical_Alignt_Out_Of_Range 0;
BA_ "GenSigCycleTime" SG_ 905 FL_Horizontal_Align_Out_Of_Range 50;
BA_ "GenSigTimeoutTime_SRR01RR" SG_ 905 FL_Horizontal_Align_Out_Of_Range 150;
BA_ "GenSigSendType" SG_ 905 FL_Horizontal_Align_Out_Of_Range 0;
BA_ "GenSigCycleTime" SG_ 905 FL_Factory_Alignment_Mode 50;
BA_ "GenSigTimeoutTime_SRR01RR" SG_ 905 FL_Factory_Alignment_Mode 150;
BA_ "GenSigSendType" SG_ 905 FL_Factory_Alignment_Mode 0;
BA_ "GenSigCycleTime" SG_ 905 FL_Battery_Low_Flt 50;
BA_ "GenSigTimeoutTime_SRR01RR" SG_ 905 FL_Battery_Low_Flt 150;
BA_ "GenSigSendType" SG_ 905 FL_Battery_Low_Flt 0;
BA_ "GenSigCycleTime" SG_ 905 FL_Battery_High_Flt 50;
BA_ "GenSigTimeoutTime_SRR01RR" SG_ 905 FL_Battery_High_Flt 150;
BA_ "GenSigSendType" SG_ 905 FL_Battery_High_Flt 0;
BA_ "GenSigCycleTime" SG_ 905 FL_Ecu_Position_Config_Flt 50;
BA_ "GenSigTimeoutTime_SRR01RR" SG_ 905 FL_Ecu_Position_Config_Flt 150;
BA_ "GenSigSendType" SG_ 905 FL_Ecu_Position_Config_Flt 0;
BA_ "GenSigCycleTime" SG_ 905 FL_Supply_1_1v_Out_Of_Range_Flt 50;
BA_ "GenSigTimeoutTime_SRR01RR" SG_ 905 FL_Supply_1_1v_Out_Of_Range_Flt 150;
BA_ "GenSigSendType" SG_ 905 FL_Supply_1_1v_Out_Of_Range_Flt 0;
BA_ "GenSigCycleTime" SG_ 905 FL_Supply_1_8v_Out_Of_Range_Flt 50;
BA_ "GenSigTimeoutTime_SRR01RR" SG_ 905 FL_Supply_1_8v_Out_Of_Range_Flt 150;
BA_ "GenSigSendType" SG_ 905 FL_Supply_1_8v_Out_Of_Range_Flt 0;
BA_ "GenSigCycleTime" SG_ 905 FL_Thermistor_Out_Of_Range_Flt 50;
BA_ "GenSigTimeoutTime_SRR01RR" SG_ 905 FL_Thermistor_Out_Of_Range_Flt 150;
BA_ "GenSigSendType" SG_ 905 FL_Thermistor_Out_Of_Range_Flt 0;
BA_ "GenSigCycleTime" SG_ 905 FL_Supply_5v_Out_Of_Range_Flt 50;
BA_ "GenSigTimeoutTime_SRR01RR" SG_ 905 FL_Supply_5v_Out_Of_Range_Flt 150;
BA_ "GenSigSendType" SG_ 905 FL_Supply_5v_Out_Of_Range_Flt 0;
BA_ "GenSigCycleTime" SG_ 905 FL_Pcan_Init_Missing_Message_Flt 50;
BA_ "GenSigTimeoutTime_SRR01RR" SG_ 905 FL_Pcan_Init_Missing_Message_Flt 150;
BA_ "GenSigSendType" SG_ 905 FL_Pcan_Init_Missing_Message_Flt 0;
BA_ "GenSigCycleTime" SG_ 905 FL_Pcan_Trk_Data_Unreasnble_Flt 50;
BA_ "GenSigTimeoutTime_SRR01RR" SG_ 905 FL_Pcan_Trk_Data_Unreasnble_Flt 150;
BA_ "GenSigSendType" SG_ 905 FL_Pcan_Trk_Data_Unreasnble_Flt 0;
BA_ "GenSigCycleTime" SG_ 905 FL_Pcan_Data_Range_Check_Flt 50;
BA_ "GenSigTimeoutTime_SRR01RR" SG_ 905 FL_Pcan_Data_Range_Check_Flt 150;
BA_ "GenSigSendType" SG_ 905 FL_Pcan_Data_Range_Check_Flt 0;
BA_ "GenSigCycleTime" SG_ 905 FL_Pcan_Missing_Message_Flt 50;
BA_ "GenSigTimeoutTime_SRR01RR" SG_ 905 FL_Pcan_Missing_Message_Flt 150;
BA_ "GenSigSendType" SG_ 905 FL_Pcan_Missing_Message_Flt 0;
BA_ "GenSigCycleTime" SG_ 905 FL_Pcan_Hw_Rx_Buffer_Flt 50;
BA_ "GenSigTimeoutTime_SRR01RR" SG_ 905 FL_Pcan_Hw_Rx_Buffer_Flt 150;
BA_ "GenSigSendType" SG_ 905 FL_Pcan_Hw_Rx_Buffer_Flt 0;
BA_ "GenSigCycleTime" SG_ 905 FL_Pcan_Sw_Buffer_Flt 50;
BA_ "GenSigTimeoutTime_SRR01RR" SG_ 905 FL_Pcan_Sw_Buffer_Flt 150;
BA_ "GenSigSendType" SG_ 905 FL_Pcan_Sw_Buffer_Flt 0;
BA_ "GenSigCycleTime" SG_ 905 FL_Pcan_Bus_Off 50;
BA_ "GenSigTimeoutTime_SRR01RR" SG_ 905 FL_Pcan_Bus_Off 150;
BA_ "GenSigSendType" SG_ 905 FL_Pcan_Bus_Off 0;
BA_ "GenSigCycleTime" SG_ 905 FL_Host_Instrctn_Set_Check_Flt 50;
BA_ "GenSigTimeoutTime_SRR01RR" SG_ 905 FL_Host_Instrctn_Set_Check_Flt 150;
BA_ "GenSigSendType" SG_ 905 FL_Host_Instrctn_Set_Check_Flt 0;
BA_ "GenSigCycleTime" SG_ 905 FL_Host_Stack_Overflow_Flt 50;
BA_ "GenSigTimeoutTime_SRR01RR" SG_ 905 FL_Host_Stack_Overflow_Flt 150;
BA_ "GenSigSendType" SG_ 905 FL_Host_Stack_Overflow_Flt 0;
BA_ "GenSigCycleTime" SG_ 905 FL_Sensor_Watchdog_Flt 50;
BA_ "GenSigTimeoutTime_SRR01RR" SG_ 905 FL_Sensor_Watchdog_Flt 150;
BA_ "GenSigSendType" SG_ 905 FL_Sensor_Watchdog_Flt 0;
BA_ "GenSigCycleTime" SG_ 905 FL_Sensor_Pll_Lock_Flt 50;
BA_ "GenSigTimeoutTime_SRR01RR" SG_ 905 FL_Sensor_Pll_Lock_Flt 150;
BA_ "GenSigSendType" SG_ 905 FL_Sensor_Pll_Lock_Flt 0;
BA_ "GenSigCycleTime" SG_ 905 FL_Host_Pll_Lock_Flt 50;
BA_ "GenSigTimeoutTime_SRR01RR" SG_ 905 FL_Host_Pll_Lock_Flt 150;
BA_ "GenSigSendType" SG_ 905 FL_Host_Pll_Lock_Flt 0;
BA_ "GenSigCycleTime" SG_ 905 FL_Sensor_Ram_Memory_Test_Flt 50;
BA_ "GenSigTimeoutTime_SRR01RR" SG_ 905 FL_Sensor_Ram_Memory_Test_Flt 150;
BA_ "GenSigSendType" SG_ 905 FL_Sensor_Ram_Memory_Test_Flt 0;
BA_ "GenSigCycleTime" SG_ 905 FL_Host_Ram_Memory_Test_Flt 50;
BA_ "GenSigTimeoutTime_SRR01RR" SG_ 905 FL_Host_Ram_Memory_Test_Flt 150;
BA_ "GenSigSendType" SG_ 905 FL_Host_Ram_Memory_Test_Flt 0;
BA_ "GenSigCycleTime" SG_ 905 FL_Snsr_Custmr_Cal_Flsh_Chksum 50;
BA_ "GenSigTimeoutTime_SRR01RR" SG_ 905 FL_Snsr_Custmr_Cal_Flsh_Chksum 150;
BA_ "GenSigSendType" SG_ 905 FL_Snsr_Custmr_Cal_Flsh_Chksum 0;
BA_ "GenSigCycleTime" SG_ 905 FL_Dsp_Usc_Validation_Flt 50;
BA_ "GenSigTimeoutTime_SRR01RR" SG_ 905 FL_Dsp_Usc_Validation_Flt 150;
BA_ "GenSigSendType" SG_ 905 FL_Dsp_Usc_Validation_Flt 0;
BA_ "GenSigCycleTime" SG_ 905 FL_Sensor_App_Flash_Checksum_Flt 50;
BA_ "GenSigTimeoutTime_SRR01RR" SG_ 905 FL_Sensor_App_Flash_Checksum_Flt 150;
BA_ "GenSigSendType" SG_ 905 FL_Sensor_App_Flash_Checksum_Flt 0;
BA_ "GenSigCycleTime" SG_ 905 FL_Host_Kp_Alv_Flsh_Chcksm_Flt 50;
BA_ "GenSigTimeoutTime_SRR01RR" SG_ 905 FL_Host_Kp_Alv_Flsh_Chcksm_Flt 150;
BA_ "GenSigSendType" SG_ 905 FL_Host_Kp_Alv_Flsh_Chcksm_Flt 0;
BA_ "GenSigCycleTime" SG_ 905 FL_Host_Pgm_Cal_Flsh_Chcksum_Flt 50;
BA_ "GenSigTimeoutTime_SRR01RR" SG_ 905 FL_Host_Pgm_Cal_Flsh_Chcksum_Flt 150;
BA_ "GenSigSendType" SG_ 905 FL_Host_Pgm_Cal_Flsh_Chcksum_Flt 0;
BA_ "GenSigCycleTime" SG_ 905 FL_Host_App_Flash_Checksum_Flt 50;
BA_ "GenSigTimeoutTime_SRR01RR" SG_ 905 FL_Host_App_Flash_Checksum_Flt 150;
BA_ "GenSigSendType" SG_ 905 FL_Host_App_Flash_Checksum_Flt 0;
BA_ "GenSigCycleTime" SG_ 906 FL_USC_Load_Error 50;
BA_ "GenSigTimeoutTime_SRR01RR" SG_ 906 FL_USC_Load_Error 150;
BA_ "GenSigSendType" SG_ 906 FL_USC_Load_Error 0;
BA_ "GenSigCycleTime" SG_ 906 FL_SMC_Load_Error 50;
BA_ "GenSigTimeoutTime_SRR01RR" SG_ 906 FL_SMC_Load_Error 150;
BA_ "GenSigSendType" SG_ 906 FL_SMC_Load_Error 0;
BA_ "GenSigCycleTime" SG_ 906 FL_TX_Temperature_Flt 50;
BA_ "GenSigTimeoutTime_SRR01RR" SG_ 906 FL_TX_Temperature_Flt 150;
BA_ "GenSigSendType" SG_ 906 FL_TX_Temperature_Flt 0;
BA_ "GenSigCycleTime" SG_ 906 FL_Dsp_Unit_Cal_Blk_Chcksm_Error 50;
BA_ "GenSigTimeoutTime_SRR01RR" SG_ 906 FL_Dsp_Unit_Cal_Blk_Chcksm_Error 150;
BA_ "GenSigSendType" SG_ 906 FL_Dsp_Unit_Cal_Blk_Chcksm_Error 0;
BA_ "GenSigCycleTime" SG_ 906 FL_Dsp_Unit_Cal_Checksum_Error 50;
BA_ "GenSigTimeoutTime_SRR01RR" SG_ 906 FL_Dsp_Unit_Cal_Checksum_Error 150;
BA_ "GenSigSendType" SG_ 906 FL_Dsp_Unit_Cal_Checksum_Error 0;
BA_ "GenSigCycleTime" SG_ 906 FL_Vertical_Misalignment_error 50;
BA_ "GenSigTimeoutTime_SRR01RR" SG_ 906 FL_Vertical_Misalignment_error 150;
BA_ "GenSigSendType" SG_ 906 FL_Vertical_Misalignment_error 0;
BA_ "GenSigCycleTime" SG_ 906 FL_RTN_SPI_Transfer_Error 50;
BA_ "GenSigTimeoutTime_SRR01RR" SG_ 906 FL_RTN_SPI_Transfer_Error 150;
BA_ "GenSigSendType" SG_ 906 FL_RTN_SPI_Transfer_Error 0;
BA_ "GenSigCycleTime" SG_ 906 FL_RRN_SPI_Transfer_Error 50;
BA_ "GenSigTimeoutTime_SRR01RR" SG_ 906 FL_RRN_SPI_Transfer_Error 150;
BA_ "GenSigSendType" SG_ 906 FL_RRN_SPI_Transfer_Error 0;
BA_ "GenSigCycleTime" SG_ 906 FL_Linearizer_SPI_Transfer_Error 50;
BA_ "GenSigTimeoutTime_SRR01RR" SG_ 906 FL_Linearizer_SPI_Transfer_Error 150;
BA_ "GenSigSendType" SG_ 906 FL_Linearizer_SPI_Transfer_Error 0;
BA_ "GenSigCycleTime" SG_ 906 FL_ADC_SPI_Transfer_Error 50;
BA_ "GenSigTimeoutTime_SRR01RR" SG_ 906 FL_ADC_SPI_Transfer_Error 150;
BA_ "GenSigSendType" SG_ 906 FL_ADC_SPI_Transfer_Error 0;
BA_ "GenSigCycleTime" SG_ 906 FL_Transmitter_ID_Error 50;
BA_ "GenSigTimeoutTime_SRR01RR" SG_ 906 FL_Transmitter_ID_Error 150;
BA_ "GenSigSendType" SG_ 906 FL_Transmitter_ID_Error 0;
BA_ "GenSigCycleTime" SG_ 906 FL_Dsp_Loop_Overrun_Error 50;
BA_ "GenSigTimeoutTime_SRR01RR" SG_ 906 FL_Dsp_Loop_Overrun_Error 150;
BA_ "GenSigSendType" SG_ 906 FL_Dsp_Loop_Overrun_Error 0;
BA_ "GenSigCycleTime" SG_ 906 FL_Saturated_Tuning_Freq_Error 50;
BA_ "GenSigTimeoutTime_SRR01RR" SG_ 906 FL_Saturated_Tuning_Freq_Error 150;
BA_ "GenSigSendType" SG_ 906 FL_Saturated_Tuning_Freq_Error 0;
BA_ "GenSigCycleTime" SG_ 906 FL_Radar_Data_sync_error 50;
BA_ "GenSigTimeoutTime_SRR01RR" SG_ 906 FL_Radar_Data_sync_error 150;
BA_ "GenSigSendType" SG_ 906 FL_Radar_Data_sync_error 0;
BA_ "GenSigCycleTime" SG_ 906 FL_Dsp_Tuning_Sensitivity_Error 50;
BA_ "GenSigTimeoutTime_SRR01RR" SG_ 906 FL_Dsp_Tuning_Sensitivity_Error 150;
BA_ "GenSigSendType" SG_ 906 FL_Dsp_Tuning_Sensitivity_Error 0;
BA_ "GenSigCycleTime" SG_ 906 FL_Radar_LO_Power_Error 50;
BA_ "GenSigTimeoutTime_SRR01RR" SG_ 906 FL_Radar_LO_Power_Error 150;
BA_ "GenSigSendType" SG_ 906 FL_Radar_LO_Power_Error 0;
BA_ "GenSigCycleTime" SG_ 906 FL_Radar_TX_Power_Error 50;
BA_ "GenSigTimeoutTime_SRR01RR" SG_ 906 FL_Radar_TX_Power_Error 150;
BA_ "GenSigSendType" SG_ 906 FL_Radar_TX_Power_Error 0;
BA_ "GenSigCycleTime" SG_ 906 FL_Timer_Create_Error 50;
BA_ "GenSigTimeoutTime_SRR01RR" SG_ 906 FL_Timer_Create_Error 150;
BA_ "GenSigSendType" SG_ 906 FL_Timer_Create_Error 0;
BA_ "GenSigCycleTime" SG_ 906 FL_Thread_Create_Error 50;
BA_ "GenSigTimeoutTime_SRR01RR" SG_ 906 FL_Thread_Create_Error 150;
BA_ "GenSigSendType" SG_ 906 FL_Thread_Create_Error 0;
BA_ "GenSigCycleTime" SG_ 906 FL_ARM_Calibration_Error 50;
BA_ "GenSigTimeoutTime_SRR01RR" SG_ 906 FL_ARM_Calibration_Error 150;
BA_ "GenSigSendType" SG_ 906 FL_ARM_Calibration_Error 0;
BA_ "GenSigCycleTime" SG_ 906 FL_SPI_FEE_Error 50;
BA_ "GenSigTimeoutTime_SRR01RR" SG_ 906 FL_SPI_FEE_Error 150;
BA_ "GenSigSendType" SG_ 906 FL_SPI_FEE_Error 0;
BA_ "GenSigCycleTime" SG_ 906 FL_SPI_Comm_Error 50;
BA_ "GenSigTimeoutTime_SRR01RR" SG_ 906 FL_SPI_Comm_Error 150;
BA_ "GenSigSendType" SG_ 906 FL_SPI_Comm_Error 0;
BA_ "GenSigCycleTime" SG_ 906 FL_Socket_Write_Error 50;
BA_ "GenSigTimeoutTime_SRR01RR" SG_ 906 FL_Socket_Write_Error 150;
BA_ "GenSigSendType" SG_ 906 FL_Socket_Write_Error 0;
BA_ "GenSigCycleTime" SG_ 906 FL_Socket_Read_error 50;
BA_ "GenSigTimeoutTime_SRR01RR" SG_ 906 FL_Socket_Read_error 150;
BA_ "GenSigSendType" SG_ 906 FL_Socket_Read_error 0;
BA_ "GenSigCycleTime" SG_ 906 FL_Socket_Init_Error 50;
BA_ "GenSigTimeoutTime_SRR01RR" SG_ 906 FL_Socket_Init_Error 150;
BA_ "GenSigSendType" SG_ 906 FL_Socket_Init_Error 0;
BA_ "GenSigCycleTime" SG_ 906 FL_Signal_Wait_Error 50;
BA_ "GenSigTimeoutTime_SRR01RR" SG_ 906 FL_Signal_Wait_Error 150;
BA_ "GenSigSendType" SG_ 906 FL_Signal_Wait_Error 0;
BA_ "GenSigCycleTime" SG_ 906 FL_Signal_Send_Error 50;
BA_ "GenSigTimeoutTime_SRR01RR" SG_ 906 FL_Signal_Send_Error 150;
BA_ "GenSigSendType" SG_ 906 FL_Signal_Send_Error 0;
BA_ "GenSigCycleTime" SG_ 906 FL_Signal_Create_Error 50;
BA_ "GenSigTimeoutTime_SRR01RR" SG_ 906 FL_Signal_Create_Error 150;
BA_ "GenSigSendType" SG_ 906 FL_Signal_Create_Error 0;
BA_ "GenSigCycleTime" SG_ 906 FL_Shared_Mem_Write_Error 50;
BA_ "GenSigTimeoutTime_SRR01RR" SG_ 906 FL_Shared_Mem_Write_Error 150;
BA_ "GenSigSendType" SG_ 906 FL_Shared_Mem_Write_Error 0;
BA_ "GenSigCycleTime" SG_ 906 FL_Shared_Mem_Read_Error 50;
BA_ "GenSigTimeoutTime_SRR01RR" SG_ 906 FL_Shared_Mem_Read_Error 150;
BA_ "GenSigSendType" SG_ 906 FL_Shared_Mem_Read_Error 0;
BA_ "GenSigCycleTime" SG_ 906 FL_Shared_Mem_Config_Error 50;
BA_ "GenSigTimeoutTime_SRR01RR" SG_ 906 FL_Shared_Mem_Config_Error 150;
BA_ "GenSigSendType" SG_ 906 FL_Shared_Mem_Config_Error 0;
BA_ "GenSigCycleTime" SG_ 906 FL_Share_Mem_Init_Error 50;
BA_ "GenSigTimeoutTime_SRR01RR" SG_ 906 FL_Share_Mem_Init_Error 150;
BA_ "GenSigSendType" SG_ 906 FL_Share_Mem_Init_Error 0;
BA_ "GenSigCycleTime" SG_ 906 FL_RAM_Test_Error 50;
BA_ "GenSigTimeoutTime_SRR01RR" SG_ 906 FL_RAM_Test_Error 150;
BA_ "GenSigSendType" SG_ 906 FL_RAM_Test_Error 0;
BA_ "GenSigCycleTime" SG_ 906 FL_Num_Errors 50;
BA_ "GenSigTimeoutTime_SRR01RR" SG_ 906 FL_Num_Errors 150;
BA_ "GenSigSendType" SG_ 906 FL_Num_Errors 0;
BA_ "GenSigCycleTime" SG_ 906 FL_MMAP_Memory_Error 50;
BA_ "GenSigTimeoutTime_SRR01RR" SG_ 906 FL_MMAP_Memory_Error 150;
BA_ "GenSigSendType" SG_ 906 FL_MMAP_Memory_Error 0;
BA_ "GenSigCycleTime" SG_ 906 FL_ISR_Attach_Error 50;
BA_ "GenSigTimeoutTime_SRR01RR" SG_ 906 FL_ISR_Attach_Error 150;
BA_ "GenSigSendType" SG_ 906 FL_ISR_Attach_Error 0;
BA_ "GenSigCycleTime" SG_ 906 FL_IPC_DRV_Write_Error 50;
BA_ "GenSigTimeoutTime_SRR01RR" SG_ 906 FL_IPC_DRV_Write_Error 150;
BA_ "GenSigSendType" SG_ 906 FL_IPC_DRV_Write_Error 0;
BA_ "GenSigCycleTime" SG_ 906 FL_IPC_DRV_Trigger_Error 50;
BA_ "GenSigTimeoutTime_SRR01RR" SG_ 906 FL_IPC_DRV_Trigger_Error 150;
BA_ "GenSigSendType" SG_ 906 FL_IPC_DRV_Trigger_Error 0;
BA_ "GenSigCycleTime" SG_ 906 FL_IPC_DRV_Sync_Error 50;
BA_ "GenSigTimeoutTime_SRR01RR" SG_ 906 FL_IPC_DRV_Sync_Error 150;
BA_ "GenSigSendType" SG_ 906 FL_IPC_DRV_Sync_Error 0;
BA_ "GenSigCycleTime" SG_ 906 FL_IPC_DRV_Read_Error 50;
BA_ "GenSigTimeoutTime_SRR01RR" SG_ 906 FL_IPC_DRV_Read_Error 150;
BA_ "GenSigSendType" SG_ 906 FL_IPC_DRV_Read_Error 0;
BA_ "GenSigCycleTime" SG_ 906 FL_IPC_DRV_Init_Error 50;
BA_ "GenSigTimeoutTime_SRR01RR" SG_ 906 FL_IPC_DRV_Init_Error 150;
BA_ "GenSigSendType" SG_ 906 FL_IPC_DRV_Init_Error 0;
BA_ "GenSigCycleTime" SG_ 906 FL_Interrupt_Enable_Error 50;
BA_ "GenSigTimeoutTime_SRR01RR" SG_ 906 FL_Interrupt_Enable_Error 150;
BA_ "GenSigSendType" SG_ 906 FL_Interrupt_Enable_Error 0;
BA_ "GenSigCycleTime" SG_ 906 FL_HIL_Format_Error 50;
BA_ "GenSigTimeoutTime_SRR01RR" SG_ 906 FL_HIL_Format_Error 150;
BA_ "GenSigSendType" SG_ 906 FL_HIL_Format_Error 0;
BA_ "GenSigCycleTime" SG_ 906 FL_Flash_Filesystem_Error 50;
BA_ "GenSigTimeoutTime_SRR01RR" SG_ 906 FL_Flash_Filesystem_Error 150;
BA_ "GenSigSendType" SG_ 906 FL_Flash_Filesystem_Error 0;
BA_ "GenSigCycleTime" SG_ 906 FL_Error_none 50;
BA_ "GenSigTimeoutTime_SRR01RR" SG_ 906 FL_Error_none 150;
BA_ "GenSigSendType" SG_ 906 FL_Error_none 0;
BA_ "GenSigCycleTime" SG_ 906 FL_Dsp_Load_Read_Error 50;
BA_ "GenSigTimeoutTime_SRR01RR" SG_ 906 FL_Dsp_Load_Read_Error 150;
BA_ "GenSigSendType" SG_ 906 FL_Dsp_Load_Read_Error 0;
BA_ "GenSigCycleTime" SG_ 906 FL_Dsp_Load_Open_Error 50;
BA_ "GenSigTimeoutTime_SRR01RR" SG_ 906 FL_Dsp_Load_Open_Error 150;
BA_ "GenSigSendType" SG_ 906 FL_Dsp_Load_Open_Error 0;
BA_ "GenSigCycleTime" SG_ 906 FL_Dsp_Load_Address_Error 50;
BA_ "GenSigTimeoutTime_SRR01RR" SG_ 906 FL_Dsp_Load_Address_Error 150;
BA_ "GenSigSendType" SG_ 906 FL_Dsp_Load_Address_Error 0;
BA_ "GenSigCycleTime" SG_ 906 FL_Dsp_ISP_Write_Error 50;
BA_ "GenSigTimeoutTime_SRR01RR" SG_ 906 FL_Dsp_ISP_Write_Error 150;
BA_ "GenSigSendType" SG_ 906 FL_Dsp_ISP_Write_Error 0;
BA_ "GenSigCycleTime" SG_ 906 FL_Dsp_IPC_Read_Error 50;
BA_ "GenSigTimeoutTime_SRR01RR" SG_ 906 FL_Dsp_IPC_Read_Error 150;
BA_ "GenSigSendType" SG_ 906 FL_Dsp_IPC_Read_Error 0;
BA_ "GenSigCycleTime" SG_ 906 FL_Dsp_IPC_Init 50;
BA_ "GenSigTimeoutTime_SRR01RR" SG_ 906 FL_Dsp_IPC_Init 150;
BA_ "GenSigSendType" SG_ 906 FL_Dsp_IPC_Init 0;
BA_ "GenSigCycleTime" SG_ 906 FL_Dsp_Init_Error 50;
BA_ "GenSigTimeoutTime_SRR01RR" SG_ 906 FL_Dsp_Init_Error 150;
BA_ "GenSigSendType" SG_ 906 FL_Dsp_Init_Error 0;
BA_ "GenSigCycleTime" SG_ 906 FL_Dsp_DRV_Start_Error 50;
BA_ "GenSigTimeoutTime_SRR01RR" SG_ 906 FL_Dsp_DRV_Start_Error 150;
BA_ "GenSigSendType" SG_ 906 FL_Dsp_DRV_Start_Error 0;
BA_ "GenSigCycleTime" SG_ 906 FL_Dsp_DRV_Load_Error 50;
BA_ "GenSigTimeoutTime_SRR01RR" SG_ 906 FL_Dsp_DRV_Load_Error 150;
BA_ "GenSigSendType" SG_ 906 FL_Dsp_DRV_Load_Error 0;
BA_ "GenSigCycleTime" SG_ 906 FL_Dsp_DRV_Init_Error 50;
BA_ "GenSigTimeoutTime_SRR01RR" SG_ 906 FL_Dsp_DRV_Init_Error 150;
BA_ "GenSigSendType" SG_ 906 FL_Dsp_DRV_Init_Error 0;
BA_ "GenSigCycleTime" SG_ 906 FL_Dsp_DRV_Init2_error 50;
BA_ "GenSigTimeoutTime_SRR01RR" SG_ 906 FL_Dsp_DRV_Init2_error 150;
BA_ "GenSigSendType" SG_ 906 FL_Dsp_DRV_Init2_error 0;
BA_ "GenSigCycleTime" SG_ 906 FL_Dsp_DRV_Init1_error 50;
BA_ "GenSigTimeoutTime_SRR01RR" SG_ 906 FL_Dsp_DRV_Init1_error 150;
BA_ "GenSigSendType" SG_ 906 FL_Dsp_DRV_Init1_error 0;
BA_ "GenSigCycleTime" SG_ 906 FL_CAN_XMT_Error 50;
BA_ "GenSigTimeoutTime_SRR01RR" SG_ 906 FL_CAN_XMT_Error 150;
BA_ "GenSigSendType" SG_ 906 FL_CAN_XMT_Error 0;
BA_ "GenSigCycleTime" SG_ 906 FL_CAN_RCV_Error 50;
BA_ "GenSigTimeoutTime_SRR01RR" SG_ 906 FL_CAN_RCV_Error 150;
BA_ "GenSigSendType" SG_ 906 FL_CAN_RCV_Error 0;
BA_ "GenSigCycleTime" SG_ 906 FL_CAN_Hardware_Error 50;
BA_ "GenSigTimeoutTime_SRR01RR" SG_ 906 FL_CAN_Hardware_Error 150;
BA_ "GenSigSendType" SG_ 906 FL_CAN_Hardware_Error 0;
BA_ "GenSigCycleTime" SG_ 906 FL_Always_True 50;
BA_ "GenSigTimeoutTime_SRR01RR" SG_ 906 FL_Always_True 150;
BA_ "GenSigSendType" SG_ 906 FL_Always_True 0;
BA_ "GenSigCmt" SG_ 864 FL_CAN_NUMBER_OF_DET "Number of detections sent";
BA_ "GenSigCmt" SG_ 864 FL_CAN_SCAN_INDEX_FUSED "Scan index fused";
BA_ "GenSigCmt" SG_ 864 FL_CAN_LOOK_ID "Indicates the look type values 1 to 4 base on medium/long look and near/far look";
BA_ "GenSigCmt" SG_ 864 FL_CAN_LOOK_INDEX "Scan index for SODFL";
BA_ "GenSigCmt" SG_ 865 FL_CAN_RANGE_COVERAGE "CAN range coverage";
BA_ "GenSigCmt" SG_ 865 FL_CAN_DOPPLER_COVERAGE "CAN range coverage";
BA_ "GenSigStartValue" SG_ 865 FL_CAN_DOPPLER_COVERAGE 32768;
BA_ "GenSigCmt" SG_ 865 FL_CAN_FOV_HOR "CAN range coverage";
BA_ "GenSigCmt" SG_ 865 FL_CAN_FOV_VER "CAN range coverage";
BA_ "GenSigCmt" SG_ 903 FL_CAN_ACTIVE_FAULTS "Active faults";
BA_ "GenSigCmt" SG_ 904 FL_CAN_LATCH_FAULTS "Active Latch Faults";
BA_ "GenSigCycleTime" SG_ 1152 FR_CAN_TX_VEH_SPEED_DIRECTION 50;
BA_ "GenSigTimeoutTime_SRR01RR" SG_ 1152 FR_CAN_TX_VEH_SPEED_DIRECTION 150;
BA_ "GenSigSendType" SG_ 1152 FR_CAN_TX_VEH_SPEED_DIRECTION 0;
BA_ "GenSigCycleTime" SG_ 1152 FR_CAN_TX_RADIUS_CURVATURE 50;
BA_ "GenSigTimeoutTime_SRR01RR" SG_ 1152 FR_CAN_TX_RADIUS_CURVATURE 150;
BA_ "GenSigSendType" SG_ 1152 FR_CAN_TX_RADIUS_CURVATURE 0;
BA_ "GenSigCycleTime" SG_ 1152 FR_CAN_TX_STEERING_ANGLE_SIGN 50;
BA_ "GenSigTimeoutTime_SRR01RR" SG_ 1152 FR_CAN_TX_STEERING_ANGLE_SIGN 150;
BA_ "GenSigSendType" SG_ 1152 FR_CAN_TX_STEERING_ANGLE_SIGN 0;
BA_ "GenSigCycleTime" SG_ 1152 FR_CAN_TX_STEERING_ANGLE 50;
BA_ "GenSigTimeoutTime_SRR01RR" SG_ 1152 FR_CAN_TX_STEERING_ANGLE 150;
BA_ "GenSigSendType" SG_ 1152 FR_CAN_TX_STEERING_ANGLE 0;
BA_ "GenSigCycleTime" SG_ 1152 FR_CAN_TX_YAW_RATE_CALC 50;
BA_ "GenSigTimeoutTime_SRR01RR" SG_ 1152 FR_CAN_TX_YAW_RATE_CALC 150;
BA_ "GenSigSendType" SG_ 1152 FR_CAN_TX_YAW_RATE_CALC 0;
BA_ "GenSigCycleTime" SG_ 1152 FR_CAN_TX_VEHICLE_SPEED_CALC 50;
BA_ "GenSigTimeoutTime_SRR01RR" SG_ 1152 FR_CAN_TX_VEHICLE_SPEED_CALC 150;
BA_ "GenSigSendType" SG_ 1152 FR_CAN_TX_VEHICLE_SPEED_CALC 0;
BA_ "GenSigCycleTime" SG_ 1152 FR_CAN_TX_SCAN_INDEX 50;
BA_ "GenSigTimeoutTime_SRR01RR" SG_ 1152 FR_CAN_TX_SCAN_INDEX 150;
BA_ "GenSigSendType" SG_ 1152 FR_CAN_TX_SCAN_INDEX 0;
BA_ "GenSigCycleTime" SG_ 1153 FR_CAN_TX_PCAN_PROTOCOL_MINOR 50;
BA_ "GenSigTimeoutTime_SRR01RR" SG_ 1153 FR_CAN_TX_PCAN_PROTOCOL_MINOR 150;
BA_ "GenSigSendType" SG_ 1153 FR_CAN_TX_PCAN_PROTOCOL_MINOR 0;
BA_ "GenSigCycleTime" SG_ 1153 FR_CAN_TX_PCAN_PROTOCOL_MAJOR 50;
BA_ "GenSigTimeoutTime_SRR01RR" SG_ 1153 FR_CAN_TX_PCAN_PROTOCOL_MAJOR 150;
BA_ "GenSigSendType" SG_ 1153 FR_CAN_TX_PCAN_PROTOCOL_MAJOR 0;
BA_ "GenSigCycleTime" SG_ 1154 FR_CAN_TX_SERIAL_NUMBER_SEQUENCE 50;
BA_ "GenSigTimeoutTime_SRR01RR" SG_ 1154 FR_CAN_TX_SERIAL_NUMBER_SEQUENCE 150;
BA_ "GenSigSendType" SG_ 1154 FR_CAN_TX_SERIAL_NUMBER_SEQUENCE 0;
BA_ "GenSigCycleTime" SG_ 1154 FR_CAN_TX_SERIAL_NUM_JULIAN_YEAR 50;
BA_ "GenSigTimeoutTime_SRR01RR" SG_ 1154 FR_CAN_TX_SERIAL_NUM_JULIAN_YEAR 150;
BA_ "GenSigSendType" SG_ 1154 FR_CAN_TX_SERIAL_NUM_JULIAN_YEAR 0;
BA_ "GenSigCycleTime" SG_ 1154 FR_CAN_TX_SERIAL_NUM_JULIAN_DAY 50;
BA_ "GenSigTimeoutTime_SRR01RR" SG_ 1154 FR_CAN_TX_SERIAL_NUM_JULIAN_DAY 150;
BA_ "GenSigSendType" SG_ 1154 FR_CAN_TX_SERIAL_NUM_JULIAN_DAY 0;
BA_ "GenSigCycleTime" SG_ 1154 FR_CAN_TX_ARM_THROUGHPUT 50;
BA_ "GenSigTimeoutTime_SRR01RR" SG_ 1154 FR_CAN_TX_ARM_THROUGHPUT 150;
BA_ "GenSigSendType" SG_ 1154 FR_CAN_TX_ARM_THROUGHPUT 0;
BA_ "GenSigCycleTime" SG_ 1154 FR_CAN_TX_SYSTEM_STATUS 50;
BA_ "GenSigTimeoutTime_SRR01RR" SG_ 1154 FR_CAN_TX_SYSTEM_STATUS 150;
BA_ "GenSigSendType" SG_ 1154 FR_CAN_TX_SYSTEM_STATUS 0;
BA_ "GenSigCycleTime" SG_ 1154 FR_CAN_TX_CONVERGED_SENSOR_POS 50;
BA_ "GenSigTimeoutTime_SRR01RR" SG_ 1154 FR_CAN_TX_CONVERGED_SENSOR_POS 150;
BA_ "GenSigSendType" SG_ 1154 FR_CAN_TX_CONVERGED_SENSOR_POS 0;
BA_ "GenSigCycleTime" SG_ 1154 FR_CAN_TX_LOOK_TYPE_1 50;
BA_ "GenSigTimeoutTime_SRR01RR" SG_ 1154 FR_CAN_TX_LOOK_TYPE_1 150;
BA_ "GenSigSendType" SG_ 1154 FR_CAN_TX_LOOK_TYPE_1 0;
BA_ "GenSigCycleTime" SG_ 1154 FR_CAN_TX_OVERHEAT_ERROR 50;
BA_ "GenSigTimeoutTime_SRR01RR" SG_ 1154 FR_CAN_TX_OVERHEAT_ERROR 150;
BA_ "GenSigSendType" SG_ 1154 FR_CAN_TX_OVERHEAT_ERROR 0;
BA_ "GenSigCycleTime" SG_ 1154 FR_CAN_TX_RANGE_PERF_ERROR 50;
BA_ "GenSigTimeoutTime_SRR01RR" SG_ 1154 FR_CAN_TX_RANGE_PERF_ERROR 150;
BA_ "GenSigSendType" SG_ 1154 FR_CAN_TX_RANGE_PERF_ERROR 0;
BA_ "GenSigCycleTime" SG_ 1154 FR_CAN_TX_COMM_ERROR 50;
BA_ "GenSigTimeoutTime_SRR01RR" SG_ 1154 FR_CAN_TX_COMM_ERROR 150;
BA_ "GenSigSendType" SG_ 1154 FR_CAN_TX_COMM_ERROR 0;
BA_ "GenSigCycleTime" SG_ 1154 FR_CAN_TX_INTERNAL_ERROR 50;
BA_ "GenSigTimeoutTime_SRR01RR" SG_ 1154 FR_CAN_TX_INTERNAL_ERROR 150;
BA_ "GenSigSendType" SG_ 1154 FR_CAN_TX_INTERNAL_ERROR 0;
BA_ "GenSigCycleTime" SG_ 1154 FR_CAN_TX_XCVR_OPERATIONAL 50;
BA_ "GenSigTimeoutTime_SRR01RR" SG_ 1154 FR_CAN_TX_XCVR_OPERATIONAL 150;
BA_ "GenSigSendType" SG_ 1154 FR_CAN_TX_XCVR_OPERATIONAL 0;
BA_ "GenSigCycleTime" SG_ 1155 FR_CAN_TX_DRIVING_ENVIRONMENT 50;
BA_ "GenSigTimeoutTime_SRR01RR" SG_ 1155 FR_CAN_TX_DRIVING_ENVIRONMENT 150;
BA_ "GenSigSendType" SG_ 1155 FR_CAN_TX_DRIVING_ENVIRONMENT 0;
BA_ "GenSigCycleTime" SG_ 1155 FR_CAN_TX_ROLLING_COUNT_1 50;
BA_ "GenSigTimeoutTime_SRR01RR" SG_ 1155 FR_CAN_TX_ROLLING_COUNT_1 150;
BA_ "GenSigSendType" SG_ 1155 FR_CAN_TX_ROLLING_COUNT_1 0;
BA_ "GenSigCycleTime" SG_ 1155 FR_CAN_TX_Temperature 50;
BA_ "GenSigTimeoutTime_SRR01RR" SG_ 1155 FR_CAN_TX_Temperature 150;
BA_ "GenSigSendType" SG_ 1155 FR_CAN_TX_Temperature 0;
BA_ "GenSigCycleTime" SG_ 1155 FR_CAN_TX_YAW_RATE_BIAS 50;
BA_ "GenSigTimeoutTime_SRR01RR" SG_ 1155 FR_CAN_TX_YAW_RATE_BIAS 150;
BA_ "GenSigSendType" SG_ 1155 FR_CAN_TX_YAW_RATE_BIAS 0;
BA_ "GenSigCycleTime" SG_ 1155 FR_CAN_TX_VEH_SPD_COMP_FACTOR 50;
BA_ "GenSigTimeoutTime_SRR01RR" SG_ 1155 FR_CAN_TX_VEH_SPD_COMP_FACTOR 150;
BA_ "GenSigSendType" SG_ 1155 FR_CAN_TX_VEH_SPD_COMP_FACTOR 0;
BA_ "GenSigCycleTime" SG_ 1155 FR_CAN_TX_AUTO_ALIGN_QUA_FACTOR 50;
BA_ "GenSigTimeoutTime_SRR01RR" SG_ 1155 FR_CAN_TX_AUTO_ALIGN_QUA_FACTOR 150;
BA_ "GenSigSendType" SG_ 1155 FR_CAN_TX_AUTO_ALIGN_QUA_FACTOR 0;
BA_ "GenSigCycleTime" SG_ 1155 FR_CAN_TX_Alignment_MODE 50;
BA_ "GenSigTimeoutTime_SRR01RR" SG_ 1155 FR_CAN_TX_Alignment_MODE 150;
BA_ "GenSigSendType" SG_ 1155 FR_CAN_TX_Alignment_MODE 0;
BA_ "GenSigCycleTime" SG_ 1155 FR_CAN_TX_CURRENT_MISALIGN_ANGLE 50;
BA_ "GenSigTimeoutTime_SRR01RR" SG_ 1155 FR_CAN_TX_CURRENT_MISALIGN_ANGLE 150;
BA_ "GenSigSendType" SG_ 1155 FR_CAN_TX_CURRENT_MISALIGN_ANGLE 0;
BA_ "GenSigCycleTime" SG_ 1155 FR_CAN_TX_SAVED_MISALIGN_ANGLE 50;
BA_ "GenSigTimeoutTime_SRR01RR" SG_ 1155 FR_CAN_TX_SAVED_MISALIGN_ANGLE 150;
BA_ "GenSigSendType" SG_ 1155 FR_CAN_TX_SAVED_MISALIGN_ANGLE 0;
BA_ "GenSigSendType" SG_ 1161 FR_Supply_2_3v_Out_Of_Range_Flt 0;
BA_ "GenSigCycleTime" SG_ 1161 FR_Supply_2_3v_Out_Of_Range_Flt 50;
BA_ "GenSigTimeoutTime_SRR01RR" SG_ 1161 FR_Supply_2_3v_Out_Of_Range_Flt 150;
BA_ "GenSigSendType" SG_ 1161 FR_Supply_1_25v_Out_Of_Range_Flt 0;
BA_ "GenSigCycleTime" SG_ 1161 FR_Supply_1_25v_Out_Of_Range_Flt 50;
BA_ "GenSigTimeoutTime_SRR01RR" SG_ 1161 FR_Supply_1_25v_Out_Of_Range_Flt 150;
BA_ "GenSigCycleTime" SG_ 1161 FR_Software_Incompatible_Flt 50;
BA_ "GenSigTimeoutTime_SRR01RR" SG_ 1161 FR_Software_Incompatible_Flt 150;
BA_ "GenSigSendType" SG_ 1161 FR_Software_Incompatible_Flt 0;
BA_ "GenSigCycleTime" SG_ 1161 FR_Host_Spi_Checksum_Flt 50;
BA_ "GenSigTimeoutTime_SRR01RR" SG_ 1161 FR_Host_Spi_Checksum_Flt 150;
BA_ "GenSigSendType" SG_ 1161 FR_Host_Spi_Checksum_Flt 0;
BA_ "GenSigCycleTime" SG_ 1161 FR_Loss_Of_Comm_With_Dsp_Flt 50;
BA_ "GenSigTimeoutTime_SRR01RR" SG_ 1161 FR_Loss_Of_Comm_With_Dsp_Flt 150;
BA_ "GenSigSendType" SG_ 1161 FR_Loss_Of_Comm_With_Dsp_Flt 0;
BA_ "GenSigCycleTime" SG_ 1161 FR_No_Communication_With_Arm_Flt 50;
BA_ "GenSigTimeoutTime_SRR01RR" SG_ 1161 FR_No_Communication_With_Arm_Flt 150;
BA_ "GenSigSendType" SG_ 1161 FR_No_Communication_With_Arm_Flt 0;
BA_ "GenSigCycleTime" SG_ 1161 FR_Communication_With_Host_Flt 50;
BA_ "GenSigTimeoutTime_SRR01RR" SG_ 1161 FR_Communication_With_Host_Flt 150;
BA_ "GenSigSendType" SG_ 1161 FR_Communication_With_Host_Flt 0;
BA_ "GenSigCycleTime" SG_ 1161 FR_Communication_With_Arm_Flt 50;
BA_ "GenSigTimeoutTime_SRR01RR" SG_ 1161 FR_Communication_With_Arm_Flt 150;
BA_ "GenSigSendType" SG_ 1161 FR_Communication_With_Arm_Flt 0;
BA_ "GenSigCycleTime" SG_ 1161 FR_Dsp_Loop_Overrun_Flt_Dsp 50;
BA_ "GenSigTimeoutTime_SRR01RR" SG_ 1161 FR_Dsp_Loop_Overrun_Flt_Dsp 150;
BA_ "GenSigSendType" SG_ 1161 FR_Dsp_Loop_Overrun_Flt_Dsp 0;
BA_ "GenSigCycleTime" SG_ 1161 FR_Tuning_Sensitivity_Flt 50;
BA_ "GenSigTimeoutTime_SRR01RR" SG_ 1161 FR_Tuning_Sensitivity_Flt 150;
BA_ "GenSigSendType" SG_ 1161 FR_Tuning_Sensitivity_Flt 0;
BA_ "GenSigCycleTime" SG_ 1161 FR_Saturated_Tuning_Freq_Flt 50;
BA_ "GenSigTimeoutTime_SRR01RR" SG_ 1161 FR_Saturated_Tuning_Freq_Flt 150;
BA_ "GenSigSendType" SG_ 1161 FR_Saturated_Tuning_Freq_Flt 0;
BA_ "GenSigCycleTime" SG_ 1161 FR_Local_Oscillator_Power_Flt 50;
BA_ "GenSigTimeoutTime_SRR01RR" SG_ 1161 FR_Local_Oscillator_Power_Flt 150;
BA_ "GenSigSendType" SG_ 1161 FR_Local_Oscillator_Power_Flt 0;
BA_ "GenSigCycleTime" SG_ 1161 FR_Transmitter_Power_Flt 50;
BA_ "GenSigTimeoutTime_SRR01RR" SG_ 1161 FR_Transmitter_Power_Flt 150;
BA_ "GenSigSendType" SG_ 1161 FR_Transmitter_Power_Flt 0;
BA_ "GenSigCycleTime" SG_ 1161 FR_Radar_Data_Sync_Flt 50;
BA_ "GenSigTimeoutTime_SRR01RR" SG_ 1161 FR_Radar_Data_Sync_Flt 150;
BA_ "GenSigSendType" SG_ 1161 FR_Radar_Data_Sync_Flt 0;
BA_ "GenSigCycleTime" SG_ 1161 FR_Dsp_Spi_Hardware_Flt 50;
BA_ "GenSigTimeoutTime_SRR01RR" SG_ 1161 FR_Dsp_Spi_Hardware_Flt 150;
BA_ "GenSigSendType" SG_ 1161 FR_Dsp_Spi_Hardware_Flt 0;
BA_ "GenSigCycleTime" SG_ 1161 FR_Transmitter_Device_Spi_Flt 50;
BA_ "GenSigTimeoutTime_SRR01RR" SG_ 1161 FR_Transmitter_Device_Spi_Flt 150;
BA_ "GenSigSendType" SG_ 1161 FR_Transmitter_Device_Spi_Flt 0;
BA_ "GenSigCycleTime" SG_ 1161 FR_Receiver_Device_Spi_Flt 50;
BA_ "GenSigTimeoutTime_SRR01RR" SG_ 1161 FR_Receiver_Device_Spi_Flt 150;
BA_ "GenSigSendType" SG_ 1161 FR_Receiver_Device_Spi_Flt 0;
BA_ "GenSigCycleTime" SG_ 1161 FR_Freq_Synthe_Device_Spi_Flt 50;
BA_ "GenSigTimeoutTime_SRR01RR" SG_ 1161 FR_Freq_Synthe_Device_Spi_Flt 150;
BA_ "GenSigSendType" SG_ 1161 FR_Freq_Synthe_Device_Spi_Flt 0;
BA_ "GenSigCycleTime" SG_ 1161 FR_Analog_Cnvrtr_Device_Spi_Flt 50;
BA_ "GenSigTimeoutTime_SRR01RR" SG_ 1161 FR_Analog_Cnvrtr_Device_Spi_Flt 150;
BA_ "GenSigSendType" SG_ 1161 FR_Analog_Cnvrtr_Device_Spi_Flt 0;
BA_ "GenSigCycleTime" SG_ 1161 FR_Transmitter_Id_Flt 50;
BA_ "GenSigTimeoutTime_SRR01RR" SG_ 1161 FR_Transmitter_Id_Flt 150;
BA_ "GenSigSendType" SG_ 1161 FR_Transmitter_Id_Flt 0;
BA_ "GenSigCycleTime" SG_ 1161 FR_Ecu_Temperature_High_Flt 50;
BA_ "GenSigTimeoutTime_SRR01RR" SG_ 1161 FR_Ecu_Temperature_High_Flt 150;
BA_ "GenSigSendType" SG_ 1161 FR_Ecu_Temperature_High_Flt 0;
BA_ "GenSigCycleTime" SG_ 1161 FR_Transmitter_Temp_High_Flt 50;
BA_ "GenSigTimeoutTime_SRR01RR" SG_ 1161 FR_Transmitter_Temp_High_Flt 150;
BA_ "GenSigSendType" SG_ 1161 FR_Transmitter_Temp_High_Flt 0;
BA_ "GenSigCycleTime" SG_ 1161 FR_Alignment_Routine_Failed_Flt 50;
BA_ "GenSigTimeoutTime_SRR01RR" SG_ 1161 FR_Alignment_Routine_Failed_Flt 150;
BA_ "GenSigSendType" SG_ 1161 FR_Alignment_Routine_Failed_Flt 0;
BA_ "GenSigCycleTime" SG_ 1161 FR_Unreasonable_Radar_Data 50;
BA_ "GenSigTimeoutTime_SRR01RR" SG_ 1161 FR_Unreasonable_Radar_Data 150;
BA_ "GenSigSendType" SG_ 1161 FR_Unreasonable_Radar_Data 0;
BA_ "GenSigCycleTime" SG_ 1161 FR_Sensor_Blocked_Flt 50;
BA_ "GenSigTimeoutTime_SRR01RR" SG_ 1161 FR_Sensor_Blocked_Flt 150;
BA_ "GenSigSendType" SG_ 1161 FR_Sensor_Blocked_Flt 0;
BA_ "GenSigCycleTime" SG_ 1161 FR_Vertical_Alignt_Out_Of_Range 50;
BA_ "GenSigTimeoutTime_SRR01RR" SG_ 1161 FR_Vertical_Alignt_Out_Of_Range 150;
BA_ "GenSigSendType" SG_ 1161 FR_Vertical_Alignt_Out_Of_Range 0;
BA_ "GenSigCycleTime" SG_ 1161 FR_Horizontal_Align_Out_Of_Range 50;
BA_ "GenSigTimeoutTime_SRR01RR" SG_ 1161 FR_Horizontal_Align_Out_Of_Range 150;
BA_ "GenSigSendType" SG_ 1161 FR_Horizontal_Align_Out_Of_Range 0;
BA_ "GenSigCycleTime" SG_ 1161 FR_Factory_Alignment_Mode 50;
BA_ "GenSigTimeoutTime_SRR01RR" SG_ 1161 FR_Factory_Alignment_Mode 150;
BA_ "GenSigSendType" SG_ 1161 FR_Factory_Alignment_Mode 0;
BA_ "GenSigCycleTime" SG_ 1161 FR_Battery_Low_Flt 50;
BA_ "GenSigTimeoutTime_SRR01RR" SG_ 1161 FR_Battery_Low_Flt 150;
BA_ "GenSigSendType" SG_ 1161 FR_Battery_Low_Flt 0;
BA_ "GenSigCycleTime" SG_ 1161 FR_Battery_High_Flt 50;
BA_ "GenSigTimeoutTime_SRR01RR" SG_ 1161 FR_Battery_High_Flt 150;
BA_ "GenSigSendType" SG_ 1161 FR_Battery_High_Flt 0;
BA_ "GenSigCycleTime" SG_ 1161 FR_Ecu_Position_Config_Flt 50;
BA_ "GenSigTimeoutTime_SRR01RR" SG_ 1161 FR_Ecu_Position_Config_Flt 150;
BA_ "GenSigSendType" SG_ 1161 FR_Ecu_Position_Config_Flt 0;
BA_ "GenSigCycleTime" SG_ 1161 FR_Supply_1_1v_Out_Of_Range_Flt 50;
BA_ "GenSigTimeoutTime_SRR01RR" SG_ 1161 FR_Supply_1_1v_Out_Of_Range_Flt 150;
BA_ "GenSigSendType" SG_ 1161 FR_Supply_1_1v_Out_Of_Range_Flt 0;
BA_ "GenSigCycleTime" SG_ 1161 FR_Supply_1_8v_Out_Of_Range_Flt 50;
BA_ "GenSigTimeoutTime_SRR01RR" SG_ 1161 FR_Supply_1_8v_Out_Of_Range_Flt 150;
BA_ "GenSigSendType" SG_ 1161 FR_Supply_1_8v_Out_Of_Range_Flt 0;
BA_ "GenSigCycleTime" SG_ 1161 FR_Thermistor_Out_Of_Range_Flt 50;
BA_ "GenSigTimeoutTime_SRR01RR" SG_ 1161 FR_Thermistor_Out_Of_Range_Flt 150;
BA_ "GenSigSendType" SG_ 1161 FR_Thermistor_Out_Of_Range_Flt 0;
BA_ "GenSigCycleTime" SG_ 1161 FR_Supply_5v_Out_Of_Range_Flt 50;
BA_ "GenSigTimeoutTime_SRR01RR" SG_ 1161 FR_Supply_5v_Out_Of_Range_Flt 150;
BA_ "GenSigSendType" SG_ 1161 FR_Supply_5v_Out_Of_Range_Flt 0;
BA_ "GenSigCycleTime" SG_ 1161 FR_Pcan_Init_Missing_Message_Flt 50;
BA_ "GenSigTimeoutTime_SRR01RR" SG_ 1161 FR_Pcan_Init_Missing_Message_Flt 150;
BA_ "GenSigSendType" SG_ 1161 FR_Pcan_Init_Missing_Message_Flt 0;
BA_ "GenSigCycleTime" SG_ 1161 FR_Pcan_Trk_Data_Unreasnble_Flt 50;
BA_ "GenSigTimeoutTime_SRR01RR" SG_ 1161 FR_Pcan_Trk_Data_Unreasnble_Flt 150;
BA_ "GenSigSendType" SG_ 1161 FR_Pcan_Trk_Data_Unreasnble_Flt 0;
BA_ "GenSigCycleTime" SG_ 1161 FR_Pcan_Data_Range_Check_Flt 50;
BA_ "GenSigTimeoutTime_SRR01RR" SG_ 1161 FR_Pcan_Data_Range_Check_Flt 150;
BA_ "GenSigSendType" SG_ 1161 FR_Pcan_Data_Range_Check_Flt 0;
BA_ "GenSigCycleTime" SG_ 1161 FR_Pcan_Missing_Message_Flt 50;
BA_ "GenSigTimeoutTime_SRR01RR" SG_ 1161 FR_Pcan_Missing_Message_Flt 150;
BA_ "GenSigSendType" SG_ 1161 FR_Pcan_Missing_Message_Flt 0;
BA_ "GenSigCycleTime" SG_ 1161 FR_Pcan_Hw_Rx_Buffer_Flt 50;
BA_ "GenSigTimeoutTime_SRR01RR" SG_ 1161 FR_Pcan_Hw_Rx_Buffer_Flt 150;
BA_ "GenSigSendType" SG_ 1161 FR_Pcan_Hw_Rx_Buffer_Flt 0;
BA_ "GenSigCycleTime" SG_ 1161 FR_Pcan_Sw_Buffer_Flt 50;
BA_ "GenSigTimeoutTime_SRR01RR" SG_ 1161 FR_Pcan_Sw_Buffer_Flt 150;
BA_ "GenSigSendType" SG_ 1161 FR_Pcan_Sw_Buffer_Flt 0;
BA_ "GenSigCycleTime" SG_ 1161 FR_Pcan_Bus_Off 50;
BA_ "GenSigTimeoutTime_SRR01RR" SG_ 1161 FR_Pcan_Bus_Off 150;
BA_ "GenSigSendType" SG_ 1161 FR_Pcan_Bus_Off 0;
BA_ "GenSigCycleTime" SG_ 1161 FR_Host_Instrctn_Set_Check_Flt 50;
BA_ "GenSigTimeoutTime_SRR01RR" SG_ 1161 FR_Host_Instrctn_Set_Check_Flt 150;
BA_ "GenSigSendType" SG_ 1161 FR_Host_Instrctn_Set_Check_Flt 0;
BA_ "GenSigCycleTime" SG_ 1161 FR_Host_Stack_Overflow_Flt 50;
BA_ "GenSigTimeoutTime_SRR01RR" SG_ 1161 FR_Host_Stack_Overflow_Flt 150;
BA_ "GenSigSendType" SG_ 1161 FR_Host_Stack_Overflow_Flt 0;
BA_ "GenSigCycleTime" SG_ 1161 FR_Sensor_Watchdog_Flt 50;
BA_ "GenSigTimeoutTime_SRR01RR" SG_ 1161 FR_Sensor_Watchdog_Flt 150;
BA_ "GenSigSendType" SG_ 1161 FR_Sensor_Watchdog_Flt 0;
BA_ "GenSigCycleTime" SG_ 1161 FR_Sensor_Pll_Lock_Flt 50;
BA_ "GenSigTimeoutTime_SRR01RR" SG_ 1161 FR_Sensor_Pll_Lock_Flt 150;
BA_ "GenSigSendType" SG_ 1161 FR_Sensor_Pll_Lock_Flt 0;
BA_ "GenSigCycleTime" SG_ 1161 FR_Host_Pll_Lock_Flt 50;
BA_ "GenSigTimeoutTime_SRR01RR" SG_ 1161 FR_Host_Pll_Lock_Flt 150;
BA_ "GenSigSendType" SG_ 1161 FR_Host_Pll_Lock_Flt 0;
BA_ "GenSigCycleTime" SG_ 1161 FR_Sensor_Ram_Memory_Test_Flt 50;
BA_ "GenSigTimeoutTime_SRR01RR" SG_ 1161 FR_Sensor_Ram_Memory_Test_Flt 150;
BA_ "GenSigSendType" SG_ 1161 FR_Sensor_Ram_Memory_Test_Flt 0;
BA_ "GenSigCycleTime" SG_ 1161 FR_Host_Ram_Memory_Test_Flt 50;
BA_ "GenSigTimeoutTime_SRR01RR" SG_ 1161 FR_Host_Ram_Memory_Test_Flt 150;
BA_ "GenSigSendType" SG_ 1161 FR_Host_Ram_Memory_Test_Flt 0;
BA_ "GenSigCycleTime" SG_ 1161 FR_Snsr_Custmr_Cal_Flsh_Chksum 50;
BA_ "GenSigTimeoutTime_SRR01RR" SG_ 1161 FR_Snsr_Custmr_Cal_Flsh_Chksum 150;
BA_ "GenSigSendType" SG_ 1161 FR_Snsr_Custmr_Cal_Flsh_Chksum 0;
BA_ "GenSigCycleTime" SG_ 1161 FR_Dsp_Usc_Validation_Flt 50;
BA_ "GenSigTimeoutTime_SRR01RR" SG_ 1161 FR_Dsp_Usc_Validation_Flt 150;
BA_ "GenSigSendType" SG_ 1161 FR_Dsp_Usc_Validation_Flt 0;
BA_ "GenSigCycleTime" SG_ 1161 FR_Sensor_App_Flash_Checksum_Flt 50;
BA_ "GenSigTimeoutTime_SRR01RR" SG_ 1161 FR_Sensor_App_Flash_Checksum_Flt 150;
BA_ "GenSigSendType" SG_ 1161 FR_Sensor_App_Flash_Checksum_Flt 0;
BA_ "GenSigCycleTime" SG_ 1161 FR_Host_Kp_Alv_Flsh_Chcksm_Flt 50;
BA_ "GenSigTimeoutTime_SRR01RR" SG_ 1161 FR_Host_Kp_Alv_Flsh_Chcksm_Flt 150;
BA_ "GenSigSendType" SG_ 1161 FR_Host_Kp_Alv_Flsh_Chcksm_Flt 0;
BA_ "GenSigCycleTime" SG_ 1161 FR_Host_Pgm_Cal_Flsh_Chcksum_Flt 50;
BA_ "GenSigTimeoutTime_SRR01RR" SG_ 1161 FR_Host_Pgm_Cal_Flsh_Chcksum_Flt 150;
BA_ "GenSigSendType" SG_ 1161 FR_Host_Pgm_Cal_Flsh_Chcksum_Flt 0;
BA_ "GenSigCycleTime" SG_ 1161 FR_Host_App_Flash_Checksum_Flt 50;
BA_ "GenSigTimeoutTime_SRR01RR" SG_ 1161 FR_Host_App_Flash_Checksum_Flt 150;
BA_ "GenSigSendType" SG_ 1161 FR_Host_App_Flash_Checksum_Flt 0;
BA_ "GenSigCycleTime" SG_ 1162 FR_USC_Load_Error 50;
BA_ "GenSigTimeoutTime_SRR01RR" SG_ 1162 FR_USC_Load_Error 150;
BA_ "GenSigSendType" SG_ 1162 FR_USC_Load_Error 0;
BA_ "GenSigCycleTime" SG_ 1162 FR_SMC_Load_Error 50;
BA_ "GenSigTimeoutTime_SRR01RR" SG_ 1162 FR_SMC_Load_Error 150;
BA_ "GenSigSendType" SG_ 1162 FR_SMC_Load_Error 0;
BA_ "GenSigCycleTime" SG_ 1162 FR_TX_Temperature_Flt 50;
BA_ "GenSigTimeoutTime_SRR01RR" SG_ 1162 FR_TX_Temperature_Flt 150;
BA_ "GenSigSendType" SG_ 1162 FR_TX_Temperature_Flt 0;
BA_ "GenSigCycleTime" SG_ 1162 FR_Dsp_Unit_Cal_Blk_Chcksm_Error 50;
BA_ "GenSigTimeoutTime_SRR01RR" SG_ 1162 FR_Dsp_Unit_Cal_Blk_Chcksm_Error 150;
BA_ "GenSigSendType" SG_ 1162 FR_Dsp_Unit_Cal_Blk_Chcksm_Error 0;
BA_ "GenSigCycleTime" SG_ 1162 FR_Dsp_Unit_Cal_Checksum_Error 50;
BA_ "GenSigTimeoutTime_SRR01RR" SG_ 1162 FR_Dsp_Unit_Cal_Checksum_Error 150;
BA_ "GenSigSendType" SG_ 1162 FR_Dsp_Unit_Cal_Checksum_Error 0;
BA_ "GenSigCycleTime" SG_ 1162 FR_Vertical_Misalignment_error 50;
BA_ "GenSigTimeoutTime_SRR01RR" SG_ 1162 FR_Vertical_Misalignment_error 150;
BA_ "GenSigSendType" SG_ 1162 FR_Vertical_Misalignment_error 0;
BA_ "GenSigCycleTime" SG_ 1162 FR_RTN_SPI_Transfer_Error 50;
BA_ "GenSigTimeoutTime_SRR01RR" SG_ 1162 FR_RTN_SPI_Transfer_Error 150;
BA_ "GenSigSendType" SG_ 1162 FR_RTN_SPI_Transfer_Error 0;
BA_ "GenSigCycleTime" SG_ 1162 FR_RRN_SPI_Transfer_Error 50;
BA_ "GenSigTimeoutTime_SRR01RR" SG_ 1162 FR_RRN_SPI_Transfer_Error 150;
BA_ "GenSigSendType" SG_ 1162 FR_RRN_SPI_Transfer_Error 0;
BA_ "GenSigCycleTime" SG_ 1162 FR_Linearizer_SPI_Transfer_Error 50;
BA_ "GenSigTimeoutTime_SRR01RR" SG_ 1162 FR_Linearizer_SPI_Transfer_Error 150;
BA_ "GenSigSendType" SG_ 1162 FR_Linearizer_SPI_Transfer_Error 0;
BA_ "GenSigCycleTime" SG_ 1162 FR_ADC_SPI_Transfer_Error 50;
BA_ "GenSigTimeoutTime_SRR01RR" SG_ 1162 FR_ADC_SPI_Transfer_Error 150;
BA_ "GenSigSendType" SG_ 1162 FR_ADC_SPI_Transfer_Error 0;
BA_ "GenSigCycleTime" SG_ 1162 FR_Transmitter_ID_Error 50;
BA_ "GenSigTimeoutTime_SRR01RR" SG_ 1162 FR_Transmitter_ID_Error 150;
BA_ "GenSigSendType" SG_ 1162 FR_Transmitter_ID_Error 0;
BA_ "GenSigCycleTime" SG_ 1162 FR_Dsp_Loop_Overrun_Error 50;
BA_ "GenSigTimeoutTime_SRR01RR" SG_ 1162 FR_Dsp_Loop_Overrun_Error 150;
BA_ "GenSigSendType" SG_ 1162 FR_Dsp_Loop_Overrun_Error 0;
BA_ "GenSigCycleTime" SG_ 1162 FR_Saturated_Tuning_Freq_Error 50;
BA_ "GenSigTimeoutTime_SRR01RR" SG_ 1162 FR_Saturated_Tuning_Freq_Error 150;
BA_ "GenSigSendType" SG_ 1162 FR_Saturated_Tuning_Freq_Error 0;
BA_ "GenSigCycleTime" SG_ 1162 FR_Radar_Data_sync_error 50;
BA_ "GenSigTimeoutTime_SRR01RR" SG_ 1162 FR_Radar_Data_sync_error 150;
BA_ "GenSigSendType" SG_ 1162 FR_Radar_Data_sync_error 0;
BA_ "GenSigCycleTime" SG_ 1162 FR_Dsp_Tuning_Sensitivity_Error 50;
BA_ "GenSigTimeoutTime_SRR01RR" SG_ 1162 FR_Dsp_Tuning_Sensitivity_Error 150;
BA_ "GenSigSendType" SG_ 1162 FR_Dsp_Tuning_Sensitivity_Error 0;
BA_ "GenSigCycleTime" SG_ 1162 FR_Radar_LO_Power_Error 50;
BA_ "GenSigTimeoutTime_SRR01RR" SG_ 1162 FR_Radar_LO_Power_Error 150;
BA_ "GenSigSendType" SG_ 1162 FR_Radar_LO_Power_Error 0;
BA_ "GenSigCycleTime" SG_ 1162 FR_Radar_TX_Power_Error 50;
BA_ "GenSigTimeoutTime_SRR01RR" SG_ 1162 FR_Radar_TX_Power_Error 150;
BA_ "GenSigSendType" SG_ 1162 FR_Radar_TX_Power_Error 0;
BA_ "GenSigCycleTime" SG_ 1162 FR_Timer_Create_Error 50;
BA_ "GenSigTimeoutTime_SRR01RR" SG_ 1162 FR_Timer_Create_Error 150;
BA_ "GenSigSendType" SG_ 1162 FR_Timer_Create_Error 0;
BA_ "GenSigCycleTime" SG_ 1162 FR_Thread_Create_Error 50;
BA_ "GenSigTimeoutTime_SRR01RR" SG_ 1162 FR_Thread_Create_Error 150;
BA_ "GenSigSendType" SG_ 1162 FR_Thread_Create_Error 0;
BA_ "GenSigCycleTime" SG_ 1162 FR_ARM_Calibration_Error 50;
BA_ "GenSigTimeoutTime_SRR01RR" SG_ 1162 FR_ARM_Calibration_Error 150;
BA_ "GenSigSendType" SG_ 1162 FR_ARM_Calibration_Error 0;
BA_ "GenSigCycleTime" SG_ 1162 FR_SPI_FEE_Error 50;
BA_ "GenSigTimeoutTime_SRR01RR" SG_ 1162 FR_SPI_FEE_Error 150;
BA_ "GenSigSendType" SG_ 1162 FR_SPI_FEE_Error 0;
BA_ "GenSigCycleTime" SG_ 1162 FR_SPI_Comm_Error 50;
BA_ "GenSigTimeoutTime_SRR01RR" SG_ 1162 FR_SPI_Comm_Error 150;
BA_ "GenSigSendType" SG_ 1162 FR_SPI_Comm_Error 0;
BA_ "GenSigCycleTime" SG_ 1162 FR_Socket_Write_Error 50;
BA_ "GenSigTimeoutTime_SRR01RR" SG_ 1162 FR_Socket_Write_Error 150;
BA_ "GenSigSendType" SG_ 1162 FR_Socket_Write_Error 0;
BA_ "GenSigCycleTime" SG_ 1162 FR_Socket_Read_error 50;
BA_ "GenSigTimeoutTime_SRR01RR" SG_ 1162 FR_Socket_Read_error 150;
BA_ "GenSigSendType" SG_ 1162 FR_Socket_Read_error 0;
BA_ "GenSigCycleTime" SG_ 1162 FR_Socket_Init_Error 50;
BA_ "GenSigTimeoutTime_SRR01RR" SG_ 1162 FR_Socket_Init_Error 150;
BA_ "GenSigSendType" SG_ 1162 FR_Socket_Init_Error 0;
BA_ "GenSigCycleTime" SG_ 1162 FR_Signal_Wait_Error 50;
BA_ "GenSigTimeoutTime_SRR01RR" SG_ 1162 FR_Signal_Wait_Error 150;
BA_ "GenSigSendType" SG_ 1162 FR_Signal_Wait_Error 0;
BA_ "GenSigCycleTime" SG_ 1162 FR_Signal_Send_Error 50;
BA_ "GenSigTimeoutTime_SRR01RR" SG_ 1162 FR_Signal_Send_Error 150;
BA_ "GenSigSendType" SG_ 1162 FR_Signal_Send_Error 0;
BA_ "GenSigCycleTime" SG_ 1162 FR_Signal_Create_Error 50;
BA_ "GenSigTimeoutTime_SRR01RR" SG_ 1162 FR_Signal_Create_Error 150;
BA_ "GenSigSendType" SG_ 1162 FR_Signal_Create_Error 0;
BA_ "GenSigCycleTime" SG_ 1162 FR_Shared_Mem_Write_Error 50;
BA_ "GenSigTimeoutTime_SRR01RR" SG_ 1162 FR_Shared_Mem_Write_Error 150;
BA_ "GenSigSendType" SG_ 1162 FR_Shared_Mem_Write_Error 0;
BA_ "GenSigCycleTime" SG_ 1162 FR_Shared_Mem_Read_Error 50;
BA_ "GenSigTimeoutTime_SRR01RR" SG_ 1162 FR_Shared_Mem_Read_Error 150;
BA_ "GenSigSendType" SG_ 1162 FR_Shared_Mem_Read_Error 0;
BA_ "GenSigCycleTime" SG_ 1162 FR_Shared_Mem_Config_Error 50;
BA_ "GenSigTimeoutTime_SRR01RR" SG_ 1162 FR_Shared_Mem_Config_Error 150;
BA_ "GenSigSendType" SG_ 1162 FR_Shared_Mem_Config_Error 0;
BA_ "GenSigCycleTime" SG_ 1162 FR_Share_Mem_Init_Error 50;
BA_ "GenSigTimeoutTime_SRR01RR" SG_ 1162 FR_Share_Mem_Init_Error 150;
BA_ "GenSigSendType" SG_ 1162 FR_Share_Mem_Init_Error 0;
BA_ "GenSigCycleTime" SG_ 1162 FR_RAM_Test_Error 50;
BA_ "GenSigTimeoutTime_SRR01RR" SG_ 1162 FR_RAM_Test_Error 150;
BA_ "GenSigSendType" SG_ 1162 FR_RAM_Test_Error 0;
BA_ "GenSigCycleTime" SG_ 1162 FR_Num_Errors 50;
BA_ "GenSigTimeoutTime_SRR01RR" SG_ 1162 FR_Num_Errors 150;
BA_ "GenSigSendType" SG_ 1162 FR_Num_Errors 0;
BA_ "GenSigCycleTime" SG_ 1162 FR_MMAP_Memory_Error 50;
BA_ "GenSigTimeoutTime_SRR01RR" SG_ 1162 FR_MMAP_Memory_Error 150;
BA_ "GenSigSendType" SG_ 1162 FR_MMAP_Memory_Error 0;
BA_ "GenSigCycleTime" SG_ 1162 FR_ISR_Attach_Error 50;
BA_ "GenSigTimeoutTime_SRR01RR" SG_ 1162 FR_ISR_Attach_Error 150;
BA_ "GenSigSendType" SG_ 1162 FR_ISR_Attach_Error 0;
BA_ "GenSigCycleTime" SG_ 1162 FR_IPC_DRV_Write_Error 50;
BA_ "GenSigTimeoutTime_SRR01RR" SG_ 1162 FR_IPC_DRV_Write_Error 150;
BA_ "GenSigSendType" SG_ 1162 FR_IPC_DRV_Write_Error 0;
BA_ "GenSigCycleTime" SG_ 1162 FR_IPC_DRV_Trigger_Error 50;
BA_ "GenSigTimeoutTime_SRR01RR" SG_ 1162 FR_IPC_DRV_Trigger_Error 150;
BA_ "GenSigSendType" SG_ 1162 FR_IPC_DRV_Trigger_Error 0;
BA_ "GenSigCycleTime" SG_ 1162 FR_IPC_DRV_Sync_Error 50;
BA_ "GenSigTimeoutTime_SRR01RR" SG_ 1162 FR_IPC_DRV_Sync_Error 150;
BA_ "GenSigSendType" SG_ 1162 FR_IPC_DRV_Sync_Error 0;
BA_ "GenSigCycleTime" SG_ 1162 FR_IPC_DRV_Read_Error 50;
BA_ "GenSigTimeoutTime_SRR01RR" SG_ 1162 FR_IPC_DRV_Read_Error 150;
BA_ "GenSigSendType" SG_ 1162 FR_IPC_DRV_Read_Error 0;
BA_ "GenSigCycleTime" SG_ 1162 FR_IPC_DRV_Init_Error 50;
BA_ "GenSigTimeoutTime_SRR01RR" SG_ 1162 FR_IPC_DRV_Init_Error 150;
BA_ "GenSigSendType" SG_ 1162 FR_IPC_DRV_Init_Error 0;
BA_ "GenSigCycleTime" SG_ 1162 FR_Interrupt_Enable_Error 50;
BA_ "GenSigTimeoutTime_SRR01RR" SG_ 1162 FR_Interrupt_Enable_Error 150;
BA_ "GenSigSendType" SG_ 1162 FR_Interrupt_Enable_Error 0;
BA_ "GenSigCycleTime" SG_ 1162 FR_HIL_Format_Error 50;
BA_ "GenSigTimeoutTime_SRR01RR" SG_ 1162 FR_HIL_Format_Error 150;
BA_ "GenSigSendType" SG_ 1162 FR_HIL_Format_Error 0;
BA_ "GenSigCycleTime" SG_ 1162 FR_Flash_Filesystem_Error 50;
BA_ "GenSigTimeoutTime_SRR01RR" SG_ 1162 FR_Flash_Filesystem_Error 150;
BA_ "GenSigSendType" SG_ 1162 FR_Flash_Filesystem_Error 0;
BA_ "GenSigCycleTime" SG_ 1162 FR_Error_none 50;
BA_ "GenSigTimeoutTime_SRR01RR" SG_ 1162 FR_Error_none 150;
BA_ "GenSigSendType" SG_ 1162 FR_Error_none 0;
BA_ "GenSigCycleTime" SG_ 1162 FR_Dsp_Load_Read_Error 50;
BA_ "GenSigTimeoutTime_SRR01RR" SG_ 1162 FR_Dsp_Load_Read_Error 150;
BA_ "GenSigSendType" SG_ 1162 FR_Dsp_Load_Read_Error 0;
BA_ "GenSigCycleTime" SG_ 1162 FR_Dsp_Load_Open_Error 50;
BA_ "GenSigTimeoutTime_SRR01RR" SG_ 1162 FR_Dsp_Load_Open_Error 150;
BA_ "GenSigSendType" SG_ 1162 FR_Dsp_Load_Open_Error 0;
BA_ "GenSigCycleTime" SG_ 1162 FR_Dsp_Load_Address_Error 50;
BA_ "GenSigTimeoutTime_SRR01RR" SG_ 1162 FR_Dsp_Load_Address_Error 150;
BA_ "GenSigSendType" SG_ 1162 FR_Dsp_Load_Address_Error 0;
BA_ "GenSigCycleTime" SG_ 1162 FR_Dsp_ISP_Write_Error 50;
BA_ "GenSigTimeoutTime_SRR01RR" SG_ 1162 FR_Dsp_ISP_Write_Error 150;
BA_ "GenSigSendType" SG_ 1162 FR_Dsp_ISP_Write_Error 0;
BA_ "GenSigCycleTime" SG_ 1162 FR_Dsp_IPC_Read_Error 50;
BA_ "GenSigTimeoutTime_SRR01RR" SG_ 1162 FR_Dsp_IPC_Read_Error 150;
BA_ "GenSigSendType" SG_ 1162 FR_Dsp_IPC_Read_Error 0;
BA_ "GenSigCycleTime" SG_ 1162 FR_Dsp_IPC_Init 50;
BA_ "GenSigTimeoutTime_SRR01RR" SG_ 1162 FR_Dsp_IPC_Init 150;
BA_ "GenSigSendType" SG_ 1162 FR_Dsp_IPC_Init 0;
BA_ "GenSigCycleTime" SG_ 1162 FR_Dsp_Init_Error 50;
BA_ "GenSigTimeoutTime_SRR01RR" SG_ 1162 FR_Dsp_Init_Error 150;
BA_ "GenSigSendType" SG_ 1162 FR_Dsp_Init_Error 0;
BA_ "GenSigCycleTime" SG_ 1162 FR_Dsp_DRV_Start_Error 50;
BA_ "GenSigTimeoutTime_SRR01RR" SG_ 1162 FR_Dsp_DRV_Start_Error 150;
BA_ "GenSigSendType" SG_ 1162 FR_Dsp_DRV_Start_Error 0;
BA_ "GenSigCycleTime" SG_ 1162 FR_Dsp_DRV_Load_Error 50;
BA_ "GenSigTimeoutTime_SRR01RR" SG_ 1162 FR_Dsp_DRV_Load_Error 150;
BA_ "GenSigSendType" SG_ 1162 FR_Dsp_DRV_Load_Error 0;
BA_ "GenSigCycleTime" SG_ 1162 FR_Dsp_DRV_Init_Error 50;
BA_ "GenSigTimeoutTime_SRR01RR" SG_ 1162 FR_Dsp_DRV_Init_Error 150;
BA_ "GenSigSendType" SG_ 1162 FR_Dsp_DRV_Init_Error 0;
BA_ "GenSigCycleTime" SG_ 1162 FR_Dsp_DRV_Init2_error 50;
BA_ "GenSigTimeoutTime_SRR01RR" SG_ 1162 FR_Dsp_DRV_Init2_error 150;
BA_ "GenSigSendType" SG_ 1162 FR_Dsp_DRV_Init2_error 0;
BA_ "GenSigCycleTime" SG_ 1162 FR_Dsp_DRV_Init1_error 50;
BA_ "GenSigTimeoutTime_SRR01RR" SG_ 1162 FR_Dsp_DRV_Init1_error 150;
BA_ "GenSigSendType" SG_ 1162 FR_Dsp_DRV_Init1_error 0;
BA_ "GenSigCycleTime" SG_ 1162 FR_CAN_XMT_Error 50;
BA_ "GenSigTimeoutTime_SRR01RR" SG_ 1162 FR_CAN_XMT_Error 150;
BA_ "GenSigSendType" SG_ 1162 FR_CAN_XMT_Error 0;
BA_ "GenSigCycleTime" SG_ 1162 FR_CAN_RCV_Error 50;
BA_ "GenSigTimeoutTime_SRR01RR" SG_ 1162 FR_CAN_RCV_Error 150;
BA_ "GenSigSendType" SG_ 1162 FR_CAN_RCV_Error 0;
BA_ "GenSigCycleTime" SG_ 1162 FR_CAN_Hardware_Error 50;
BA_ "GenSigTimeoutTime_SRR01RR" SG_ 1162 FR_CAN_Hardware_Error 150;
BA_ "GenSigSendType" SG_ 1162 FR_CAN_Hardware_Error 0;
BA_ "GenSigCycleTime" SG_ 1162 FR_Always_True 50;
BA_ "GenSigTimeoutTime_SRR01RR" SG_ 1162 FR_Always_True 150;
BA_ "GenSigSendType" SG_ 1162 FR_Always_True 0;
BA_ "GenSigCmt" SG_ 1120 FR_CAN_NUMBER_OF_DET "Number of detections sent";
BA_ "GenSigCmt" SG_ 1120 FR_CAN_SCAN_INDEX_FUSED "Scan index fused";
BA_ "GenSigCmt" SG_ 1120 FR_CAN_LOOK_ID "Indicates the look type values 1 to 4 base on medium/long look and near/far look";
BA_ "GenSigCmt" SG_ 1120 FR_CAN_LOOK_INDEX "Scan index for SODFR";
BA_ "GenSigCmt" SG_ 1121 FR_CAN_RANGE_COVERAGE "CAN range coverage";
BA_ "GenSigCmt" SG_ 1121 FR_CAN_DOPPLER_COVERAGE "CAN range coverage";
BA_ "GenSigStartValue" SG_ 1121 FR_CAN_DOPPLER_COVERAGE 32768;
BA_ "GenSigCmt" SG_ 1121 FR_CAN_FOV_HOR "CAN range coverage";
BA_ "GenSigCmt" SG_ 1121 FR_CAN_FOV_VER "CAN range coverage";
BA_ "GenSigCmt" SG_ 1159 FR_CAN_ACTIVE_FAULTS "Active faults";
BA_ "GenSigCmt" SG_ 1160 FR_CAN_LATCH_FAULTS "Active Latch Faults";
VAL_ 913 FL_CAN_SENSOR_MOUNT_LOCATION 6 "RIGHT_REAR" 5 "RIGHT_FORWARD" 4 "CENTER_REAR" 3 "CENTER_FORWARD" 2 "LEFT_REAR" 1 "LEFT_FORWARD" 0 "UNKNOWN" ;
VAL_ 1169 FR_CAN_SENSOR_MOUNT_LOCATION 6 "RIGHT_REAR" 5 "RIGHT_FORWARD" 4 "CENTER_REAR" 3 "CENTER_FORWARD" 2 "LEFT_REAR" 1 "LEFT_FORWARD" 0 "UNKNOWN" ;
VAL_ 908 FL_CAN_BRR_STATUS 2 "FAULT" 1 "ACTIVE" 0 "INACTIVE" ;
VAL_ 907 FL_CAN_TIMESYNC_CORRECTION_TYP 3 "Down Step" 2 "Up Correction Several" 1 "Up Correction One Step" 0 "INVALID" ;
VAL_ 1164 FR_CAN_BRR_STATUS 2 "FAULT" 1 "ACTIVE" 0 "INACTIVE" ;
VAL_ 1163 FR_CAN_TIMESYNC_CORRECTION_TYP 3 "Down Step" 2 "Up Correction Several" 1 "Up Correction One Step" 0 "INVALID" ;
VAL_ 1 SRR_CAN_TSyn_SGW 1 "SyncToSubDomain" 0 "SyncToGTM" ;
VAL_ 1 SRR_CAN_TSyn_PDU 40 "CAN-FUP" 32 "CAN-SYN" ;
VAL_ 866 FL_Horizontal_Alignment_Status 15 "Undefined" 14 "Undefined" 13 "Low Amplitude (Flat-plate only)" 12 "No Peak (Flat-plate only)" 11 "Fail Ver and Hor OutOfRange" 10 "Fail Vertical Align OutOfRange" 9 "Fail Horizontal Align OutOfRange" 8 "Fail Time Out" 7 "Fail Only Right Target Found" 6 "Fail Only Left Target Found" 5 "Fail Variance Too Large" 4 "Fail Deviation Too Large" 3 "Fail No Target" 2 "Success" 1 "Busy" 0 "Off" ;
VAL_ 866 FL_Vertical_Alignment_Status 15 "Undefined" 14 "Undefined" 13 "Low Amplitude (Flat-plate only)" 12 "No Peak (Flat-plate only)" 11 "Fail Ver and Hor OutOfRange" 10 "Fail Vertical Align OutOfRange" 9 "Fail Horizontal Align OutOfRange" 8 "Fail Time Out" 7 "Fail Only Right Target Found" 6 "Fail Only Left Target Found" 5 "Fail Variance Too Large" 4 "Fail Deviation Too Large" 3 "Fail No Target" 2 "Success" 1 "Busy" 0 "Off" ;
VAL_ 866 FL_Vertical_Alignment_State 6 "Static alignment flat-plate" 5 "Static alignment 2-target" 4 "Static alignment 1-target" 3 "Service alignment" 2 "Short track alignment" 1 "Auto alignment" 0 "Off" ;
VAL_ 866 FL_Horizontal_Alignment_State 6 "Static alignment flat-plate" 5 "Static alignment 2-target" 4 "Static alignment 1-target" 3 "Service alignment" 2 "Short track alignment" 1 "Auto alignment" 0 "Off" ;
VAL_ 866 FL_Align_Vertical_QF 3 "Accurate" 2 "Innacurate" 1 "Temporarily undefined (Faulty)" 0 "Undefined" ;
VAL_ 866 FL_Align_Horizontal_QF 3 "Accurate" 2 "Innacurate" 1 "Temporarily undefined (Faulty)" 0 "Undefined" ;
VAL_ 1122 FR_Horizontal_Alignment_Status 15 "Undefined" 14 "Undefined" 13 "Low Amplitude (Flat-plate only)" 12 "No Peak (Flat-plate only)" 11 "Fail Ver and Hor OutOfRange" 10 "Fail Vertical Align OutOfRange" 9 "Fail Horizontal Align OutOfRange" 8 "Fail Time Out" 7 "Fail Only Right Target Found" 6 "Fail Only Left Target Found" 5 "Fail Variance Too Large" 4 "Fail Deviation Too Large" 3 "Fail No Target" 2 "Success" 1 "Busy" 0 "Off" ;
VAL_ 1122 FR_Vertical_Alignment_Status 15 "Undefined" 14 "Undefined" 13 "Low Amplitude (Flat-plate only)" 12 "No Peak (Flat-plate only)" 11 "Fail Ver and Hor OutOfRange" 10 "Fail Vertical Align OutOfRange" 9 "Fail Horizontal Align OutOfRange" 8 "Fail Time Out" 7 "Fail Only Right Target Found" 6 "Fail Only Left Target Found" 5 "Fail Variance Too Large" 4 "Fail Deviation Too Large" 3 "Fail No Target" 2 "Success" 1 "Busy" 0 "Off" ;
VAL_ 1122 FR_Vertical_Alignment_State 6 "Static alignment flat-plate" 5 "Static alignment 2-target" 4 "Static alignment 1-target" 3 "Service alignment" 2 "Short track alignment" 1 "Auto alignment" 0 "Off" ;
VAL_ 1122 FR_Horizontal_Alignment_State 6 "Static alignment flat-plate" 5 "Static alignment 2-target" 4 "Static alignment 1-target" 3 "Service alignment" 2 "Short track alignment" 1 "Auto alignment" 0 "Off" ;
VAL_ 1122 FR_Align_Vertical_QF 3 "Accurate" 2 "Innacurate" 1 "Temporarily undefined (Faulty)" 0 "Undefined" ;
VAL_ 1122 FR_Align_Horizontal_QF 3 "Accurate" 2 "Innacurate" 1 "Temporarily undefined (Faulty)" 0 "Undefined" ;
VAL_ 513 SRR_CAN_YAW_RATE_CALC_QF 3 "Accurate" 2 "Innaccurate" 1 "Temporarily Undefined" 0 "Undefined" ;
VAL_ 513 SRR_CAN_VEHICLE_SPEED_CALC_QF 3 "Accurate" 2 "Innaccurate" 1 "Temporarily Undefined" 0 "Undefined" ;
VAL_ 514 SRR_CAN_VEH_BATT_VOLT 255 "Fault" ;
VAL_ 514 SRR_CAN_IGN_STATUS 15 "Invalid" 8 "Start" 4 "Run" 2 "Accessory" 1 "Off" 0 "Unknown" ;
VAL_ 514 SRR_CAN_GEAR_POSITION 15 "Fault" 14 "Unknown_Position" 13 "NotUsed_2" 12 "NotUsed_1" 11 "sixth" 10 "fifth" 9 "fourth" 8 "third" 7 "second" 6 "first" 5 "Low" 4 "Sport_DriveSport" 3 "Drive" 2 "Neutral" 1 "Reverse" 0 "Park" ;
VAL_ 514 SRR_CAN_WIPER_STATUS 1 "On" 0 "Off" ;
VAL_ 514 SRR_PwPckTq_D_Stat 3 "PwPckOn_TqAvailable" 2 "StartInPrgrss_TqNotAvail" 1 "PwPckOn_TqNotAvailable" 0 "PwPckOff_TqNotAvailable" ;
VAL_ 514 SRR_CcStat_D_Actl 7 "Undefined_2" 6 "Undefined_1" 5 "Active" 4 "Active_Que_Assist" 3 "Standby" 2 "Standby_Denied" 1 "Denied" 0 "Off" ;
VAL_ 514 SRR_ElPw_D_Stat 7 "NotUsed_3" 6 "NotUsed_2" 5 "NotUsed_1" 4 "Fault_Limited" 3 "LV_Event_In_Progress" 2 "Not_Supported_Imminent" 1 "Supported" 0 "Not_Supported" ;
VAL_ 514 SRR_VehOverGnd_V_Est 65535 "Invalid" 65534 "Unknown" ;
VAL_ 514 SRR_CAN_LROS_DrivingDirection 4 "-" 2 "Forward" 1 "Backward" 0 "Unknown" ;
VAL_ 514 SRR_CAN_LROS_DrivingReverse 1 "Reverse" 0 "Not_Reverse" ;
VAL_ 514 SRR_Left_Blink 1 "On" 0 "Off" ;
VAL_ 514 SRR_Right_Blink 1 "On" 0 "Off" ;
VAL_ 897 FL_CAN_TX_PLATFORM_VARIANT 6 "VARIANT_MRR3LLP" 5 "VARIANT_MRR3LLP_A01" 4 "VARIANT_MRR360" 3 "VARIANT_RACAM" 2 "VARIANT_SRR5" 1 "VARIANT_MRR3" 0 "VARIANT_INVALID" ;
VAL_ 902 FL_CAN_SMC_PLATFROM_VERSION 5 "MRR3LLP" 4 "MRR360" 3 "RACAM" 2 "SRR5" 1 "MRR3" 0 "INVALID" ;
VAL_ 864 FL_CAN_LOOK_ID 3 "Far Look" 2 "Near Look" 1 "Long Look" 0 "Medium Look" ;
VAL_ 1153 FR_CAN_TX_PLATFORM_VARIANT 6 "VARIANT_MRR3LLP" 5 "VARIANT_MRR3LLP_A01" 4 "VARIANT_MRR360" 3 "VARIANT_RACAM" 2 "VARIANT_SRR5" 1 "VARIANT_MRR3" 0 "VARIANT_INVALID" ;
VAL_ 1158 FR_CAN_SMC_PLATFROM_VERSION 5 "MRR3LLP" 4 "MRR360" 3 "RACAM" 2 "SRR5" 1 "MRR3" 0 "INVALID" ;
VAL_ 1120 FR_CAN_LOOK_ID 3 "Far Look" 2 "Near Look" 1 "Long Look" 0 "Medium Look" ;
